VERSION ""

NS_ :

BS_:

BU_: XXX CAMERA FRONT_RADAR ADRV APRK

BO_ 53 ACCELERATOR: 32 XXX
 SG_ GEAR : 8|4@1+ (1,0) [0|15] "" XXX
 SG_ BYTE0 : 0|8@1+ (1,0) [0|255] "" XXX
 SG_ BYTE2 : 16|8@1+ (1,0) [0|255] "" XXX
 SG_ BYTE3 : 24|8@1+ (1,0) [0|255] "" XXX
 SG_ BYTE4 : 32|8@1+ (1,0) [0|255] "" XXX
 SG_ BYTE5 : 40|8@1+ (1,0) [0|255] "" XXX
 SG_ BYTE6 : 48|8@1+ (1,0) [0|255] "" XXX
 SG_ BYTE7 : 56|8@1+ (1,0) [0|255] "" XXX
 SG_ BYTE8 : 64|8@1+ (1,0) [0|255] "" XXX
 SG_ BYTE9 : 72|8@1+ (1,0) [0|255] "" XXX
 SG_ BYTE10 : 80|8@1+ (1,0) [0|255] "" XXX
 SG_ BYTE11 : 88|8@1+ (1,0) [0|255] "" XXX
 SG_ BYTE12 : 96|8@1+ (1,0) [0|255] "" XXX
 SG_ BYTE13 : 104|8@1+ (1,0) [0|255] "" XXX
 SG_ BYTE14 : 112|8@1+ (1,0) [0|255] "" XXX
 SG_ BYTE15 : 120|8@1+ (1,0) [0|255] "" XXX
 SG_ BYTE16 : 128|8@1+ (1,0) [0|255] "" XXX
 SG_ BYTE17 : 136|8@1+ (1,0) [0|255] "" XXX
 SG_ BYTE18 : 144|8@1+ (1,0) [0|255] "" XXX
 SG_ BYTE19 : 152|8@1+ (1,0) [0|255] "" XXX
 SG_ BYTE20 : 160|8@1+ (1,0) [0|255] "" XXX
 SG_ BYTE21 : 168|8@1+ (1,0) [0|255] "" XXX
 SG_ BYTE22 : 176|8@1+ (1,0) [0|255] "" XXX
 SG_ BYTE23 : 184|8@1+ (1,0) [0|255] "" XXX
 SG_ BYTE24 : 192|8@1+ (1,0) [0|255] "" XXX
 SG_ BYTE25 : 200|8@1+ (1,0) [0|255] "" XXX
 SG_ BYTE26 : 208|8@1+ (1,0) [0|255] "" XXX
 SG_ BYTE27 : 216|8@1+ (1,0) [0|255] "" XXX
 SG_ BYTE28 : 224|8@1+ (1,0) [0|255] "" XXX
 SG_ BYTE29 : 232|8@1+ (1,0) [0|255] "" XXX
 SG_ BYTE30 : 240|8@1+ (1,0) [0|255] "" XXX
 SG_ BYTE31 : 248|8@1+ (1,0) [0|255] "" XXX

BO_ 64 GEAR_ALT: 32 XXX
 SG_ GEAR : 8|4@1+ (1,0) [0|15] "" XXX
 SG_ BYTE0 : 0|8@1+ (1,0) [0|255] "" XXX
 SG_ BYTE2 : 16|8@1+ (1,0) [0|255] "" XXX
 SG_ BYTE3 : 24|8@1+ (1,0) [0|255] "" XXX
 SG_ BYTE4 : 32|8@1+ (1,0) [0|255] "" XXX
 SG_ BYTE5 : 40|8@1+ (1,0) [0|255] "" XXX
 SG_ BYTE6 : 48|8@1+ (1,0) [0|255] "" XXX
 SG_ BYTE7 : 56|8@1+ (1,0) [0|255] "" XXX
 SG_ BYTE8 : 64|8@1+ (1,0) [0|255] "" XXX
 SG_ BYTE9 : 72|8@1+ (1,0) [0|255] "" XXX
 SG_ BYTE10 : 80|8@1+ (1,0) [0|255] "" XXX
 SG_ BYTE11 : 88|8@1+ (1,0) [0|255] "" XXX
 SG_ BYTE12 : 96|8@1+ (1,0) [0|255] "" XXX
 SG_ BYTE13 : 104|8@1+ (1,0) [0|255] "" XXX
 SG_ BYTE14 : 112|8@1+ (1,0) [0|255] "" XXX
 SG_ BYTE15 : 120|8@1+ (1,0) [0|255] "" XXX
 SG_ BYTE16 : 128|8@1+ (1,0) [0|255] "" XXX
 SG_ BYTE17 : 136|8@1+ (1,0) [0|255] "" XXX
 SG_ BYTE18 : 144|8@1+ (1,0) [0|255] "" XXX
 SG_ BYTE19 : 152|8@1+ (1,0) [0|255] "" XXX
 SG_ BYTE20 : 160|8@1+ (1,0) [0|255] "" XXX
 SG_ BYTE21 : 168|8@1+ (1,0) [0|255] "" XXX
 SG_ BYTE22 : 176|8@1+ (1,0) [0|255] "" XXX
 SG_ BYTE23 : 184|8@1+ (1,0) [0|255] "" XXX
 SG_ BYTE24 : 192|8@1+ (1,0) [0|255] "" XXX
 SG_ BYTE25 : 200|8@1+ (1,0) [0|255] "" XXX
 SG_ BYTE26 : 208|8@1+ (1,0) [0|255] "" XXX
 SG_ BYTE27 : 216|8@1+ (1,0) [0|255] "" XXX
 SG_ BYTE28 : 224|8@1+ (1,0) [0|255] "" XXX
 SG_ BYTE29 : 232|8@1+ (1,0) [0|255] "" XXX
 SG_ BYTE30 : 240|8@1+ (1,0) [0|255] "" XXX
 SG_ BYTE31 : 248|8@1+ (1,0) [0|255] "" XXX

BO_ 69 GEAR: 24 XXX
 SG_ GEAR : 8|4@1+ (1,0) [0|15] "" XXX
 SG_ BYTE0 : 0|8@1+ (1,0) [0|255] "" XXX
 SG_ BYTE2 : 16|8@1+ (1,0) [0|255] "" XXX
 SG_ BYTE3 : 24|8@1+ (1,0) [0|255] "" XXX
 SG_ BYTE4 : 32|8@1+ (1,0) [0|255] "" XXX
 SG_ BYTE5 : 40|8@1+ (1,0) [0|255] "" XXX
 SG_ BYTE6 : 48|8@1+ (1,0) [0|255] "" XXX
 SG_ BYTE7 : 56|8@1+ (1,0) [0|255] "" XXX
 SG_ BYTE8 : 64|8@1+ (1,0) [0|255] "" XXX
 SG_ BYTE9 : 72|8@1+ (1,0) [0|255] "" XXX
 SG_ BYTE10 : 80|8@1+ (1,0) [0|255] "" XXX
 SG_ BYTE11 : 88|8@1+ (1,0) [0|255] "" XXX
 SG_ BYTE12 : 96|8@1+ (1,0) [0|255] "" XXX
 SG_ BYTE13 : 104|8@1+ (1,0) [0|255] "" XXX
 SG_ BYTE14 : 112|8@1+ (1,0) [0|255] "" XXX
 SG_ BYTE15 : 120|8@1+ (1,0) [0|255] "" XXX
 SG_ BYTE16 : 128|8@1+ (1,0) [0|255] "" XXX
 SG_ BYTE17 : 136|8@1+ (1,0) [0|255] "" XXX
 SG_ BYTE18 : 144|8@1+ (1,0) [0|255] "" XXX
 SG_ BYTE19 : 152|8@1+ (1,0) [0|255] "" XXX
 SG_ BYTE20 : 160|8@1+ (1,0) [0|255] "" XXX
 SG_ BYTE21 : 168|8@1+ (1,0) [0|255] "" XXX
 SG_ BYTE22 : 176|8@1+ (1,0) [0|255] "" XXX
 SG_ BYTE23 : 184|8@1+ (1,0) [0|255] "" XXX

BO_ 81 ADRV_0x51: 16 XXX
 SG_ BYTE0 : 0|8@1+ (1,0) [0|255] "" XXX
 SG_ BYTE1 : 8|8@1+ (1,0) [0|255] "" XXX
 SG_ BYTE2 : 16|8@1+ (1,0) [0|255] "" XXX
 SG_ BYTE3 : 24|8@1+ (1,0) [0|255] "" XXX
 SG_ BYTE4 : 32|8@1+ (1,0) [0|255] "" XXX
 SG_ BYTE5 : 40|8@1+ (1,0) [0|255] "" XXX
 SG_ BYTE6 : 48|8@1+ (1,0) [0|255] "" XXX
 SG_ BYTE7 : 56|8@1+ (1,0) [0|255] "" XXX
 SG_ BYTE8 : 64|8@1+ (1,0) [0|255] "" XXX
 SG_ BYTE9 : 72|8@1+ (1,0) [0|255] "" XXX
 SG_ BYTE10 : 80|8@1+ (1,0) [0|255] "" XXX
 SG_ BYTE11 : 88|8@1+ (1,0) [0|255] "" XXX
 SG_ BYTE12 : 96|8@1+ (1,0) [0|255] "" XXX
 SG_ BYTE13 : 104|8@1+ (1,0) [0|255] "" XXX
 SG_ BYTE14 : 112|8@1+ (1,0) [0|255] "" XXX
 SG_ BYTE15 : 120|8@1+ (1,0) [0|255] "" XXX

BO_ 96 ESP_STATUS: 32 XXX

BO_ 101 BRAKE: 32 XXX

BO_ 160 WHEEL_SPEEDS: 24 XXX
 SG_ BYTE0 : 0|8@1+ (1,0) [0|255] "" XXX
 SG_ BYTE1 : 8|8@1+ (1,0) [0|255] "" XXX
 SG_ BYTE2 : 16|8@1+ (1,0) [0|255] "" XXX
 SG_ BYTE3 : 24|8@1+ (1,0) [0|255] "" XXX
 SG_ BYTE4 : 32|8@1+ (1,0) [0|255] "" XXX
 SG_ BYTE5 : 40|8@1+ (1,0) [0|255] "" XXX
 SG_ BYTE6 : 48|8@1+ (1,0) [0|255] "" XXX
 SG_ BYTE7 : 56|8@1+ (1,0) [0|255] "" XXX
 SG_ BYTE8 : 64|8@1+ (1,0) [0|255] "" XXX
 SG_ BYTE9 : 72|8@1+ (1,0) [0|255] "" XXX
 SG_ BYTE10 : 80|8@1+ (1,0) [0|255] "" XXX
 SG_ BYTE11 : 88|8@1+ (1,0) [0|255] "" XXX
 SG_ BYTE12 : 96|8@1+ (1,0) [0|255] "" XXX
 SG_ BYTE13 : 104|8@1+ (1,0) [0|255] "" XXX
 SG_ BYTE14 : 112|8@1+ (1,0) [0|255] "" XXX
 SG_ BYTE15 : 120|8@1+ (1,0) [0|255] "" XXX
 SG_ BYTE16 : 128|8@1+ (1,0) [0|255] "" XXX
 SG_ BYTE17 : 136|8@1+ (1,0) [0|255] "" XXX
 SG_ BYTE18 : 144|8@1+ (1,0) [0|255] "" XXX
 SG_ BYTE19 : 152|8@1+ (1,0) [0|255] "" XXX
 SG_ BYTE20 : 160|8@1+ (1,0) [0|255] "" XXX
 SG_ BYTE21 : 168|8@1+ (1,0) [0|255] "" XXX
 SG_ BYTE22 : 176|8@1+ (1,0) [0|255] "" XXX
 SG_ BYTE23 : 184|8@1+ (1,0) [0|255] "" XXX

BO_ 234 MDPS: 32 XXX
 SG_ BYTE0 : 0|8@1+ (1,0) [0|255] "" XXX
 SG_ BYTE1 : 8|8@1+ (1,0) [0|255] "" XXX
 SG_ BYTE2 : 16|8@1+ (1,0) [0|255] "" XXX
 SG_ BYTE3 : 24|8@1+ (1,0) [0|255] "" XXX
 SG_ BYTE4 : 32|8@1+ (1,0) [0|255] "" XXX
 SG_ BYTE5 : 40|8@1+ (1,0) [0|255] "" XXX
 SG_ BYTE6 : 48|8@1+ (1,0) [0|255] "" XXX
 SG_ BYTE7 : 56|8@1+ (1,0) [0|255] "" XXX
 SG_ BYTE8 : 64|8@1+ (1,0) [0|255] "" XXX
 SG_ BYTE9 : 72|8@1+ (1,0) [0|255] "" XXX
 SG_ BYTE10 : 80|8@1+ (1,0) [0|255] "" XXX
 SG_ BYTE11 : 88|8@1+ (1,0) [0|255] "" XXX
 SG_ BYTE12 : 96|8@1+ (1,0) [0|255] "" XXX
 SG_ BYTE13 : 104|8@1+ (1,0) [0|255] "" XXX
 SG_ BYTE14 : 112|8@1+ (1,0) [0|255] "" XXX
 SG_ BYTE15 : 120|8@1+ (1,0) [0|255] "" XXX
 SG_ BYTE16 : 128|8@1+ (1,0) [0|255] "" XXX
 SG_ BYTE17 : 136|8@1+ (1,0) [0|255] "" XXX
 SG_ BYTE18 : 144|8@1+ (1,0) [0|255] "" XXX
 SG_ BYTE19 : 152|8@1+ (1,0) [0|255] "" XXX
 SG_ BYTE20 : 160|8@1+ (1,0) [0|255] "" XXX
 SG_ BYTE21 : 168|8@1+ (1,0) [0|255] "" XXX
 SG_ BYTE22 : 176|8@1+ (1,0) [0|255] "" XXX
 SG_ BYTE23 : 184|8@1+ (1,0) [0|255] "" XXX
 SG_ BYTE24 : 192|8@1+ (1,0) [0|255] "" XXX
 SG_ BYTE25 : 200|8@1+ (1,0) [0|255] "" XXX
 SG_ BYTE26 : 208|8@1+ (1,0) [0|255] "" XXX
 SG_ BYTE27 : 216|8@1+ (1,0) [0|255] "" XXX
 SG_ BYTE28 : 224|8@1+ (1,0) [0|255] "" XXX
 SG_ BYTE29 : 232|8@1+ (1,0) [0|255] "" XXX
 SG_ BYTE30 : 240|8@1+ (1,0) [0|255] "" XXX
 SG_ BYTE31 : 248|8@1+ (1,0) [0|255] "" XXX

BO_ 256 ACCELERATOR_BRAKE_ALT: 24 XXX
 SG_ BYTE0 : 0|8@1+ (1,0) [0|255] "" XXX
 SG_ BYTE1 : 8|8@1+ (1,0) [0|255] "" XXX
 SG_ BYTE2 : 16|8@1+ (1,0) [0|255] "" XXX
 SG_ BYTE3 : 24|8@1+ (1,0) [0|255] "" XXX
 SG_ BYTE4 : 32|8@1+ (1,0) [0|255] "" XXX
 SG_ BYTE5 : 40|8@1+ (1,0) [0|255] "" XXX
 SG_ BYTE6 : 48|8@1+ (1,0) [0|255] "" XXX
 SG_ BYTE7 : 56|8@1+ (1,0) [0|255] "" XXX
 SG_ BYTE8 : 64|8@1+ (1,0) [0|255] "" XXX
 SG_ BYTE9 : 72|8@1+ (1,0) [0|255] "" XXX
 SG_ BYTE10 : 80|8@1+ (1,0) [0|255] "" XXX
 SG_ BYTE11 : 88|8@1+ (1,0) [0|255] "" XXX
 SG_ BYTE12 : 96|8@1+ (1,0) [0|255] "" XXX
 SG_ BYTE13 : 104|8@1+ (1,0) [0|255] "" XXX
 SG_ BYTE14 : 112|8@1+ (1,0) [0|255] "" XXX
 SG_ BYTE15 : 120|8@1+ (1,0) [0|255] "" XXX
 SG_ BYTE16 : 128|8@1+ (1,0) [0|255] "" XXX
 SG_ BYTE17 : 136|8@1+ (1,0) [0|255] "" XXX
 SG_ BYTE18 : 144|8@1+ (1,0) [0|255] "" XXX
 SG_ BYTE19 : 152|8@1+ (1,0) [0|255] "" XXX
 SG_ BYTE20 : 160|8@1+ (1,0) [0|255] "" XXX
 SG_ BYTE21 : 168|8@1+ (1,0) [0|255] "" XXX
 SG_ BYTE22 : 176|8@1+ (1,0) [0|255] "" XXX
 SG_ BYTE23 : 184|8@1+ (1,0) [0|255] "" XXX

BO_ 272 LKAS_ALT: 32 XXX
 SG_ LKA_MODE : 24|4@1+ (1,0) [0|15] "" XXX
 SG_ LKA_ICON : 28|4@1+ (1,0) [0|15] "" XXX
 SG_ TORQUE_REQUEST : 32|11@1- (1,0) [-1024|1023] "" XXX
 SG_ LKA_ASSIST : 43|1@1+ (1,0) [0|1] "" XXX
 SG_ STEER_REQ : 44|1@1+ (1,0) [0|1] "" XXX
 SG_ STEER_MODE : 45|3@1+ (1,0) [0|7] "" XXX
 SG_ HAS_LANE_SAFETY : 48|1@1+ (1,0) [0|1] "" XXX
 SG_ LKA_AVAILABLE : 27|2@1+ (1,0) [0|3] "" XXX
 SG_ CHECKSUM : 0|16@1+ (1,0) [0|65535] "" XXX
 SG_ COUNTER : 16|8@1+ (1,0) [0|255] "" XXX
 SG_ BYTE7 : 56|8@1+ (1,0) [0|255] "" XXX
 SG_ BYTE8 : 64|8@1+ (1,0) [0|255] "" XXX
 SG_ BYTE9 : 72|8@1+ (1,0) [0|255] "" XXX
 SG_ BYTE10 : 80|8@1+ (1,0) [0|255] "" XXX
 SG_ BYTE11 : 88|8@1+ (1,0) [0|255] "" XXX
 SG_ BYTE12 : 96|8@1+ (1,0) [0|255] "" XXX
 SG_ BYTE13 : 104|8@1+ (1,0) [0|255] "" XXX
 SG_ BYTE14 : 112|8@1+ (1,0) [0|255] "" XXX
 SG_ BYTE15 : 120|8@1+ (1,0) [0|255] "" XXX
 SG_ BYTE16 : 128|8@1+ (1,0) [0|255] "" XXX
 SG_ BYTE17 : 136|8@1+ (1,0) [0|255] "" XXX
 SG_ BYTE18 : 144|8@1+ (1,0) [0|255] "" XXX
 SG_ BYTE19 : 152|8@1+ (1,0) [0|255] "" XXX
 SG_ BYTE20 : 160|8@1+ (1,0) [0|255] "" XXX
 SG_ BYTE21 : 168|8@1+ (1,0) [0|255] "" XXX
 SG_ BYTE22 : 176|8@1+ (1,0) [0|255] "" XXX
 SG_ BYTE23 : 184|8@1+ (1,0) [0|255] "" XXX
 SG_ BYTE24 : 192|8@1+ (1,0) [0|255] "" XXX
 SG_ BYTE25 : 200|8@1+ (1,0) [0|255] "" XXX
 SG_ BYTE26 : 208|8@1+ (1,0) [0|255] "" XXX
 SG_ BYTE27 : 216|8@1+ (1,0) [0|255] "" XXX
 SG_ BYTE28 : 224|8@1+ (1,0) [0|255] "" XXX
 SG_ BYTE29 : 232|8@1+ (1,0) [0|255] "" XXX
 SG_ BYTE30 : 240|8@1+ (1,0) [0|255] "" XXX
 SG_ BYTE31 : 248|8@1+ (1,0) [0|255] "" XXX

BO_ 282 FR_CMR_01_10ms: 16 XXX

BO_ 293 STEERING_SENSORS: 32 XXX
 SG_ BYTE0 : 0|8@1+ (1,0) [0|255] "" XXX
 SG_ BYTE1 : 8|8@1+ (1,0) [0|255] "" XXX
 SG_ BYTE2 : 16|8@1+ (1,0) [0|255] "" XXX
 SG_ BYTE3 : 24|8@1+ (1,0) [0|255] "" XXX
 SG_ BYTE4 : 32|8@1+ (1,0) [0|255] "" XXX
 SG_ BYTE5 : 40|8@1+ (1,0) [0|255] "" XXX
 SG_ BYTE6 : 48|8@1+ (1,0) [0|255] "" XXX
 SG_ BYTE7 : 56|8@1+ (1,0) [0|255] "" XXX
 SG_ BYTE8 : 64|8@1+ (1,0) [0|255] "" XXX
 SG_ BYTE9 : 72|8@1+ (1,0) [0|255] "" XXX
 SG_ BYTE10 : 80|8@1+ (1,0) [0|255] "" XXX
 SG_ BYTE11 : 88|8@1+ (1,0) [0|255] "" XXX
 SG_ BYTE12 : 96|8@1+ (1,0) [0|255] "" XXX
 SG_ BYTE13 : 104|8@1+ (1,0) [0|255] "" XXX
 SG_ BYTE14 : 112|8@1+ (1,0) [0|255] "" XXX
 SG_ BYTE15 : 120|8@1+ (1,0) [0|255] "" XXX
 SG_ BYTE16 : 128|8@1+ (1,0) [0|255] "" XXX
 SG_ BYTE17 : 136|8@1+ (1,0) [0|255] "" XXX
 SG_ BYTE18 : 144|8@1+ (1,0) [0|255] "" XXX
 SG_ BYTE19 : 152|8@1+ (1,0) [0|255] "" XXX
 SG_ BYTE20 : 160|8@1+ (1,0) [0|255] "" XXX
 SG_ BYTE21 : 168|8@1+ (1,0) [0|255] "" XXX
 SG_ BYTE22 : 176|8@1+ (1,0) [0|255] "" XXX
 SG_ BYTE23 : 184|8@1+ (1,0) [0|255] "" XXX
 SG_ BYTE24 : 192|8@1+ (1,0) [0|255] "" XXX
 SG_ BYTE25 : 200|8@1+ (1,0) [0|255] "" XXX
 SG_ BYTE26 : 208|8@1+ (1,0) [0|255] "" XXX
 SG_ BYTE27 : 216|8@1+ (1,0) [0|255] "" XXX
 SG_ BYTE28 : 224|8@1+ (1,0) [0|255] "" XXX
 SG_ BYTE29 : 232|8@1+ (1,0) [0|255] "" XXX
 SG_ BYTE30 : 240|8@1+ (1,0) [0|255] "" XXX
 SG_ BYTE31 : 248|8@1+ (1,0) [0|255] "" XXX

BO_ 298 LFA: 32 XXX
 SG_ LKA_MODE : 24|4@1+ (1,0) [0|15] "" XXX
 SG_ LKA_ICON : 28|4@1+ (1,0) [0|15] "" XXX
 SG_ TORQUE_REQUEST : 32|11@1- (1,0) [-1024|1023] "" XXX
 SG_ LKA_ASSIST : 43|1@1+ (1,0) [0|1] "" XXX
 SG_ STEER_REQ : 44|1@1+ (1,0) [0|1] "" XXX
 SG_ STEER_MODE : 45|3@1+ (1,0) [0|7] "" XXX
 SG_ HAS_LANE_SAFETY : 48|1@1+ (1,0) [0|1] "" XXX
 SG_ LKA_AVAILABLE : 27|2@1+ (1,0) [0|3] "" XXX
 SG_ CHECKSUM : 0|16@1+ (1,0) [0|65535] "" XXX
 SG_ COUNTER : 16|8@1+ (1,0) [0|255] "" XXX
 SG_ BYTE7 : 56|8@1+ (1,0) [0|255] "" XXX
 SG_ BYTE8 : 64|8@1+ (1,0) [0|255] "" XXX
 SG_ BYTE9 : 72|8@1+ (1,0) [0|255] "" XXX
 SG_ BYTE10 : 80|8@1+ (1,0) [0|255] "" XXX
 SG_ BYTE11 : 88|8@1+ (1,0) [0|255] "" XXX
 SG_ BYTE12 : 96|8@1+ (1,0) [0|255] "" XXX
 SG_ BYTE13 : 104|8@1+ (1,0) [0|255] "" XXX
 SG_ BYTE14 : 112|8@1+ (1,0) [0|255] "" XXX
 SG_ BYTE15 : 120|8@1+ (1,0) [0|255] "" XXX
 SG_ BYTE16 : 128|8@1+ (1,0) [0|255] "" XXX
 SG_ BYTE17 : 136|8@1+ (1,0) [0|255] "" XXX
 SG_ BYTE18 : 144|8@1+ (1,0) [0|255] "" XXX
 SG_ BYTE19 : 152|8@1+ (1,0) [0|255] "" XXX
 SG_ BYTE20 : 160|8@1+ (1,0) [0|255] "" XXX
 SG_ BYTE21 : 168|8@1+ (1,0) [0|255] "" XXX
 SG_ BYTE22 : 176|8@1+ (1,0) [0|255] "" XXX
 SG_ BYTE23 : 184|8@1+ (1,0) [0|255] "" XXX
 SG_ BYTE24 : 192|8@1+ (1,0) [0|255] "" XXX
 SG_ BYTE25 : 200|8@1+ (1,0) [0|255] "" XXX
 SG_ BYTE26 : 208|8@1+ (1,0) [0|255] "" XXX
 SG_ BYTE27 : 216|8@1+ (1,0) [0|255] "" XXX
 SG_ BYTE28 : 224|8@1+ (1,0) [0|255] "" XXX
 SG_ BYTE29 : 232|8@1+ (1,0) [0|255] "" XXX
 SG_ BYTE30 : 240|8@1+ (1,0) [0|255] "" XXX
 SG_ BYTE31 : 248|8@1+ (1,0) [0|255] "" XXX

BO_ 304 GEAR_SHIFTER: 32 XXX
 SG_ GEAR : 8|4@1+ (1,0) [0|15] "" XXX
 SG_ BYTE0 : 0|8@1+ (1,0) [0|255] "" XXX
 SG_ BYTE2 : 16|8@1+ (1,0) [0|255] "" XXX
 SG_ BYTE3 : 24|8@1+ (1,0) [0|255] "" XXX
 SG_ BYTE4 : 32|8@1+ (1,0) [0|255] "" XXX
 SG_ BYTE5 : 40|8@1+ (1,0) [0|255] "" XXX
 SG_ BYTE6 : 48|8@1+ (1,0) [0|255] "" XXX
 SG_ BYTE7 : 56|8@1+ (1,0) [0|255] "" XXX
 SG_ BYTE8 : 64|8@1+ (1,0) [0|255] "" XXX
 SG_ BYTE9 : 72|8@1+ (1,0) [0|255] "" XXX
 SG_ BYTE10 : 80|8@1+ (1,0) [0|255] "" XXX
 SG_ BYTE11 : 88|8@1+ (1,0) [0|255] "" XXX
 SG_ BYTE12 : 96|8@1+ (1,0) [0|255] "" XXX
 SG_ BYTE13 : 104|8@1+ (1,0) [0|255] "" XXX
 SG_ BYTE14 : 112|8@1+ (1,0) [0|255] "" XXX
 SG_ BYTE15 : 120|8@1+ (1,0) [0|255] "" XXX
 SG_ BYTE16 : 128|8@1+ (1,0) [0|255] "" XXX
 SG_ BYTE17 : 136|8@1+ (1,0) [0|255] "" XXX
 SG_ BYTE18 : 144|8@1+ (1,0) [0|255] "" XXX
 SG_ BYTE19 : 152|8@1+ (1,0) [0|255] "" XXX
 SG_ BYTE20 : 160|8@1+ (1,0) [0|255] "" XXX
 SG_ BYTE21 : 168|8@1+ (1,0) [0|255] "" XXX
 SG_ BYTE22 : 176|8@1+ (1,0) [0|255] "" XXX
 SG_ BYTE23 : 184|8@1+ (1,0) [0|255] "" XXX
 SG_ BYTE24 : 192|8@1+ (1,0) [0|255] "" XXX
 SG_ BYTE25 : 200|8@1+ (1,0) [0|255] "" XXX
 SG_ BYTE26 : 208|8@1+ (1,0) [0|255] "" XXX
 SG_ BYTE27 : 216|8@1+ (1,0) [0|255] "" XXX
 SG_ BYTE28 : 224|8@1+ (1,0) [0|255] "" XXX
 SG_ BYTE29 : 232|8@1+ (1,0) [0|255] "" XXX
 SG_ BYTE30 : 240|8@1+ (1,0) [0|255] "" XXX
 SG_ BYTE31 : 248|8@1+ (1,0) [0|255] "" XXX

BO_ 352 ADRV_0x160: 16 XXX
 SG_ BYTE0 : 0|8@1+ (1,0) [0|255] "" XXX
 SG_ BYTE1 : 8|8@1+ (1,0) [0|255] "" XXX
 SG_ BYTE2 : 16|8@1+ (1,0) [0|255] "" XXX
 SG_ BYTE3 : 24|8@1+ (1,0) [0|255] "" XXX
 SG_ BYTE4 : 32|8@1+ (1,0) [0|255] "" XXX
 SG_ BYTE5 : 40|8@1+ (1,0) [0|255] "" XXX
 SG_ BYTE6 : 48|8@1+ (1,0) [0|255] "" XXX
 SG_ BYTE7 : 56|8@1+ (1,0) [0|255] "" XXX
 SG_ BYTE8 : 64|8@1+ (1,0) [0|255] "" XXX
 SG_ BYTE9 : 72|8@1+ (1,0) [0|255] "" XXX
 SG_ BYTE10 : 80|8@1+ (1,0) [0|255] "" XXX
 SG_ BYTE11 : 88|8@1+ (1,0) [0|255] "" XXX
 SG_ BYTE12 : 96|8@1+ (1,0) [0|255] "" XXX
 SG_ BYTE13 : 104|8@1+ (1,0) [0|255] "" XXX
 SG_ BYTE14 : 112|8@1+ (1,0) [0|255] "" XXX
 SG_ BYTE15 : 120|8@1+ (1,0) [0|255] "" XXX

BO_ 357 ADRV_0x165: 16 XXX
 SG_ BYTE0 : 0|8@1+ (1,0) [0|255] "" XXX
 SG_ BYTE1 : 8|8@1+ (1,0) [0|255] "" XXX
 SG_ BYTE2 : 16|8@1+ (1,0) [0|255] "" XXX
 SG_ BYTE3 : 24|8@1+ (1,0) [0|255] "" XXX
 SG_ BYTE4 : 32|8@1+ (1,0) [0|255] "" XXX
 SG_ BYTE5 : 40|8@1+ (1,0) [0|255] "" XXX
 SG_ BYTE6 : 48|8@1+ (1,0) [0|255] "" XXX
 SG_ BYTE7 : 56|8@1+ (1,0) [0|255] "" XXX
 SG_ BYTE8 : 64|8@1+ (1,0) [0|255] "" XXX
 SG_ BYTE9 : 72|8@1+ (1,0) [0|255] "" XXX
 SG_ BYTE10 : 80|8@1+ (1,0) [0|255] "" XXX
 SG_ BYTE11 : 88|8@1+ (1,0) [0|255] "" XXX
 SG_ BYTE12 : 96|8@1+ (1,0) [0|255] "" XXX
 SG_ BYTE13 : 104|8@1+ (1,0) [0|255] "" XXX
 SG_ BYTE14 : 112|8@1+ (1,0) [0|255] "" XXX
 SG_ BYTE15 : 120|8@1+ (1,0) [0|255] "" XXX

BO_ 373 TCS: 16 XXX
 SG_ BYTE0 : 0|8@1+ (1,0) [0|255] "" XXX
 SG_ BYTE1 : 8|8@1+ (1,0) [0|255] "" XXX
 SG_ BYTE2 : 16|8@1+ (1,0) [0|255] "" XXX
 SG_ BYTE3 : 24|8@1+ (1,0) [0|255] "" XXX
 SG_ BYTE4 : 32|8@1+ (1,0) [0|255] "" XXX
 SG_ BYTE5 : 40|8@1+ (1,0) [0|255] "" XXX
 SG_ BYTE6 : 48|8@1+ (1,0) [0|255] "" XXX
 SG_ BYTE7 : 56|8@1+ (1,0) [0|255] "" XXX
 SG_ BYTE8 : 64|8@1+ (1,0) [0|255] "" XXX
 SG_ BYTE9 : 72|8@1+ (1,0) [0|255] "" XXX
 SG_ BYTE10 : 80|8@1+ (1,0) [0|255] "" XXX
 SG_ BYTE11 : 88|8@1+ (1,0) [0|255] "" XXX
 SG_ BYTE12 : 96|8@1+ (1,0) [0|255] "" XXX
 SG_ BYTE13 : 104|8@1+ (1,0) [0|255] "" XXX
 SG_ BYTE14 : 112|8@1+ (1,0) [0|255] "" XXX
 SG_ BYTE15 : 120|8@1+ (1,0) [0|255] "" XXX

BO_ 416 SCC_CONTROL: 32 XXX
 SG_ ACCMode : 68|3@1+ (1,0) [0|7] "" XXX
 SG_ CRUISE_STANDSTILL : 76|1@1+ (1,0) [0|1] "" XXX
 SG_ VSetDis : 103|8@0+ (1,0) [0|255] "" XXX
 SG_ aReqValue : 128|11@1+ (0.01,-10.23) [-10.23|10.24] "m/s^2" XXX
 SG_ aReqRaw : 140|11@1+ (0.01,-10.23) [-10.23|10.24] "m/s^2" XXX
 SG_ CHECKSUM : 0|16@1+ (1,0) [0|65535] "" XXX
 SG_ COUNTER : 16|8@1+ (1,0) [0|255] "" XXX
 SG_ BYTE3 : 24|8@1+ (1,0) [0|255] "" XXX
 SG_ BYTE4 : 32|8@1+ (1,0) [0|255] "" XXX
 SG_ BYTE5 : 40|8@1+ (1,0) [0|255] "" XXX
 SG_ BYTE6 : 48|8@1+ (1,0) [0|255] "" XXX
 SG_ BYTE7 : 56|8@1+ (1,0) [0|255] "" XXX
 SG_ BYTE10 : 80|8@1+ (1,0) [0|255] "" XXX
 SG_ BYTE11 : 88|8@1+ (1,0) [0|255] "" XXX
 SG_ BYTE13 : 104|8@1+ (1,0) [0|255] "" XXX
 SG_ BYTE14 : 112|8@1+ (1,0) [0|255] "" XXX
 SG_ BYTE15 : 120|8@1+ (1,0) [0|255] "" XXX
 SG_ BYTE21 : 168|8@1+ (1,0) [0|255] "" XXX
 SG_ BYTE22 : 176|8@1+ (1,0) [0|255] "" XXX
 SG_ BYTE23 : 184|8@1+ (1,0) [0|255] "" XXX
 SG_ BYTE24 : 192|8@1+ (1,0) [0|255] "" XXX
 SG_ BYTE25 : 200|8@1+ (1,0) [0|255] "" XXX
 SG_ BYTE26 : 208|8@1+ (1,0) [0|255] "" XXX
 SG_ BYTE27 : 216|8@1+ (1,0) [0|255] "" XXX
 SG_ BYTE28 : 224|8@1+ (1,0) [0|255] "" XXX
 SG_ BYTE29 : 232|8@1+ (1,0) [0|255] "" XXX
 SG_ BYTE30 : 240|8@1+ (1,0) [0|255] "" XXX
 SG_ BYTE31 : 248|8@1+ (1,0) [0|255] "" XXX

BO_ 426 CRUISE_BUTTONS_ALT: 16 XXX
 SG_ DISTANCE_UNIT : 30|1@1+ (1,0) [0|1] "" XXX
 SG_ CRUISE_BUTTONS : 36|3@1+ (1,0) [0|4] "" XXX
 SG_ LDA_BTN : 39|1@1+ (1,0) [0|1] "" XXX
 SG_ CHECKSUM : 0|16@1+ (1,0) [0|65535] "" XXX
 SG_ COUNTER : 16|8@1+ (1,0) [0|255] "" XXX
 SG_ BYTE6 : 48|8@1+ (1,0) [0|255] "" XXX
 SG_ BYTE7 : 56|8@1+ (1,0) [0|255] "" XXX
 SG_ BYTE8 : 64|8@1+ (1,0) [0|255] "" XXX
 SG_ BYTE9 : 72|8@1+ (1,0) [0|255] "" XXX
 SG_ BYTE10 : 80|8@1+ (1,0) [0|255] "" XXX
 SG_ BYTE11 : 88|8@1+ (1,0) [0|255] "" XXX
 SG_ BYTE12 : 96|8@1+ (1,0) [0|255] "" XXX
 SG_ BYTE13 : 104|8@1+ (1,0) [0|255] "" XXX
 SG_ BYTE14 : 112|8@1+ (1,0) [0|255] "" XXX
 SG_ BYTE15 : 120|8@1+ (1,0) [0|255] "" XXX

BO_ 437 CAMERA_0x1b5: 32 XXX
 SG_ BYTE0 : 0|8@1+ (1,0) [0|255] "" XXX
 SG_ BYTE1 : 8|8@1+ (1,0) [0|255] "" XXX
 SG_ BYTE2 : 16|8@1+ (1,0) [0|255] "" XXX
 SG_ BYTE3 : 24|8@1+ (1,0) [0|255] "" XXX
 SG_ BYTE4 : 32|8@1+ (1,0) [0|255] "" XXX
 SG_ BYTE5 : 40|8@1+ (1,0) [0|255] "" XXX
 SG_ BYTE6 : 48|8@1+ (1,0) [0|255] "" XXX
 SG_ BYTE7 : 56|8@1+ (1,0) [0|255] "" XXX
 SG_ BYTE8 : 64|8@1+ (1,0) [0|255] "" XXX
 SG_ BYTE9 : 72|8@1+ (1,0) [0|255] "" XXX
 SG_ BYTE10 : 80|8@1+ (1,0) [0|255] "" XXX
 SG_ BYTE11 : 88|8@1+ (1,0) [0|255] "" XXX
 SG_ BYTE12 : 96|8@1+ (1,0) [0|255] "" XXX
 SG_ BYTE13 : 104|8@1+ (1,0) [0|255] "" XXX
 SG_ BYTE14 : 112|8@1+ (1,0) [0|255] "" XXX
 SG_ BYTE15 : 120|8@1+ (1,0) [0|255] "" XXX
 SG_ BYTE16 : 128|8@1+ (1,0) [0|255] "" XXX
 SG_ BYTE17 : 136|8@1+ (1,0) [0|255] "" XXX
 SG_ BYTE18 : 144|8@1+ (1,0) [0|255] "" XXX
 SG_ BYTE19 : 152|8@1+ (1,0) [0|255] "" XXX
 SG_ BYTE20 : 160|8@1+ (1,0) [0|255] "" XXX
 SG_ BYTE21 : 168|8@1+ (1,0) [0|255] "" XXX
 SG_ BYTE22 : 176|8@1+ (1,0) [0|255] "" XXX
 SG_ BYTE23 : 184|8@1+ (1,0) [0|255] "" XXX
 SG_ BYTE24 : 192|8@1+ (1,0) [0|255] "" XXX
 SG_ BYTE25 : 200|8@1+ (1,0) [0|255] "" XXX
 SG_ BYTE26 : 208|8@1+ (1,0) [0|255] "" XXX
 SG_ BYTE27 : 216|8@1+ (1,0) [0|255] "" XXX
 SG_ BYTE28 : 224|8@1+ (1,0) [0|255] "" XXX
 SG_ BYTE29 : 232|8@1+ (1,0) [0|255] "" XXX
 SG_ BYTE30 : 240|8@1+ (1,0) [0|255] "" XXX
 SG_ BYTE31 : 248|8@1+ (1,0) [0|255] "" XXX

BO_ 442 BLINDSPOTS_REAR_CORNERS: 24 XXX
 SG_ BYTE0 : 0|8@1+ (1,0) [0|255] "" XXX
 SG_ BYTE1 : 8|8@1+ (1,0) [0|255] "" XXX
 SG_ BYTE2 : 16|8@1+ (1,0) [0|255] "" XXX
 SG_ BYTE3 : 24|8@1+ (1,0) [0|255] "" XXX
 SG_ BYTE4 : 32|8@1+ (1,0) [0|255] "" XXX
 SG_ BYTE5 : 40|8@1+ (1,0) [0|255] "" XXX
 SG_ BYTE6 : 48|8@1+ (1,0) [0|255] "" XXX
 SG_ BYTE7 : 56|8@1+ (1,0) [0|255] "" XXX
 SG_ BYTE8 : 64|8@1+ (1,0) [0|255] "" XXX
 SG_ BYTE9 : 72|8@1+ (1,0) [0|255] "" XXX
 SG_ BYTE10 : 80|8@1+ (1,0) [0|255] "" XXX
 SG_ BYTE11 : 88|8@1+ (1,0) [0|255] "" XXX
 SG_ BYTE12 : 96|8@1+ (1,0) [0|255] "" XXX
 SG_ BYTE13 : 104|8@1+ (1,0) [0|255] "" XXX
 SG_ BYTE14 : 112|8@1+ (1,0) [0|255] "" XXX
 SG_ BYTE15 : 120|8@1+ (1,0) [0|255] "" XXX
 SG_ BYTE16 : 128|8@1+ (1,0) [0|255] "" XXX
 SG_ BYTE17 : 136|8@1+ (1,0) [0|255] "" XXX
 SG_ BYTE18 : 144|8@1+ (1,0) [0|255] "" XXX
 SG_ BYTE19 : 152|8@1+ (1,0) [0|255] "" XXX
 SG_ BYTE20 : 160|8@1+ (1,0) [0|255] "" XXX
 SG_ BYTE21 : 168|8@1+ (1,0) [0|255] "" XXX
 SG_ BYTE22 : 176|8@1+ (1,0) [0|255] "" XXX
 SG_ BYTE23 : 184|8@1+ (1,0) [0|255] "" XXX

BO_ 474 ADRV_0x1da: 16 XXX
 SG_ BYTE0 : 0|8@1+ (1,0) [0|255] "" XXX
 SG_ BYTE1 : 8|8@1+ (1,0) [0|255] "" XXX
 SG_ BYTE2 : 16|8@1+ (1,0) [0|255] "" XXX
 SG_ BYTE3 : 24|8@1+ (1,0) [0|255] "" XXX
 SG_ BYTE4 : 32|8@1+ (1,0) [0|255] "" XXX
 SG_ BYTE5 : 40|8@1+ (1,0) [0|255] "" XXX
 SG_ BYTE6 : 48|8@1+ (1,0) [0|255] "" XXX
 SG_ BYTE7 : 56|8@1+ (1,0) [0|255] "" XXX
 SG_ BYTE8 : 64|8@1+ (1,0) [0|255] "" XXX
 SG_ BYTE9 : 72|8@1+ (1,0) [0|255] "" XXX
 SG_ BYTE10 : 80|8@1+ (1,0) [0|255] "" XXX
 SG_ BYTE11 : 88|8@1+ (1,0) [0|255] "" XXX
 SG_ BYTE12 : 96|8@1+ (1,0) [0|255] "" XXX
 SG_ BYTE13 : 104|8@1+ (1,0) [0|255] "" XXX
 SG_ BYTE14 : 112|8@1+ (1,0) [0|255] "" XXX
 SG_ BYTE15 : 120|8@1+ (1,0) [0|255] "" XXX

BO_ 480 LFAHDA_CLUSTER: 32 XXX
 SG_ HDA_ICON : 24|2@1+ (1,0) [0|3] "" XXX
 SG_ LFA_ICON : 28|2@1+ (1,0) [0|3] "" XXX
 SG_ CHECKSUM : 0|16@1+ (1,0) [0|65535] "" XXX
 SG_ COUNTER : 16|8@1+ (1,0) [0|255] "" XXX
 SG_ BYTE4 : 32|8@1+ (1,0) [0|255] "" XXX
 SG_ BYTE5 : 40|8@1+ (1,0) [0|255] "" XXX
 SG_ BYTE6 : 48|8@1+ (1,0) [0|255] "" XXX
 SG_ BYTE7 : 56|8@1+ (1,0) [0|255] "" XXX
 SG_ BYTE8 : 64|8@1+ (1,0) [0|255] "" XXX
 SG_ BYTE9 : 72|8@1+ (1,0) [0|255] "" XXX
 SG_ BYTE10 : 80|8@1+ (1,0) [0|255] "" XXX
 SG_ BYTE11 : 88|8@1+ (1,0) [0|255] "" XXX
 SG_ BYTE12 : 96|8@1+ (1,0) [0|255] "" XXX
 SG_ BYTE13 : 104|8@1+ (1,0) [0|255] "" XXX
 SG_ BYTE14 : 112|8@1+ (1,0) [0|255] "" XXX
 SG_ BYTE15 : 120|8@1+ (1,0) [0|255] "" XXX
 SG_ BYTE16 : 128|8@1+ (1,0) [0|255] "" XXX
 SG_ BYTE17 : 136|8@1+ (1,0) [0|255] "" XXX
 SG_ BYTE18 : 144|8@1+ (1,0) [0|255] "" XXX
 SG_ BYTE19 : 152|8@1+ (1,0) [0|255] "" XXX
 SG_ BYTE20 : 160|8@1+ (1,0) [0|255] "" XXX
 SG_ BYTE21 : 168|8@1+ (1,0) [0|255] "" XXX
 SG_ BYTE22 : 176|8@1+ (1,0) [0|255] "" XXX
 SG_ BYTE23 : 184|8@1+ (1,0) [0|255] "" XXX
 SG_ BYTE24 : 192|8@1+ (1,0) [0|255] "" XXX
 SG_ BYTE25 : 200|8@1+ (1,0) [0|255] "" XXX
 SG_ BYTE26 : 208|8@1+ (1,0) [0|255] "" XXX
 SG_ BYTE27 : 216|8@1+ (1,0) [0|255] "" XXX
 SG_ BYTE28 : 224|8@1+ (1,0) [0|255] "" XXX
 SG_ BYTE29 : 232|8@1+ (1,0) [0|255] "" XXX
 SG_ BYTE30 : 240|8@1+ (1,0) [0|255] "" XXX
 SG_ BYTE31 : 248|8@1+ (1,0) [0|255] "" XXX

BO_ 490 ADRV_0x1ea: 32 XXX
 SG_ BYTE0 : 0|8@1+ (1,0) [0|255] "" XXX
 SG_ BYTE1 : 8|8@1+ (1,0) [0|255] "" XXX
 SG_ BYTE2 : 16|8@1+ (1,0) [0|255] "" XXX
 SG_ BYTE3 : 24|8@1+ (1,0) [0|255] "" XXX
 SG_ BYTE4 : 32|8@1+ (1,0) [0|255] "" XXX
 SG_ BYTE5 : 40|8@1+ (1,0) [0|255] "" XXX
 SG_ BYTE6 : 48|8@1+ (1,0) [0|255] "" XXX
 SG_ BYTE7 : 56|8@1+ (1,0) [0|255] "" XXX
 SG_ BYTE8 : 64|8@1+ (1,0) [0|255] "" XXX
 SG_ BYTE9 : 72|8@1+ (1,0) [0|255] "" XXX
 SG_ BYTE10 : 80|8@1+ (1,0) [0|255] "" XXX
 SG_ BYTE11 : 88|8@1+ (1,0) [0|255] "" XXX
 SG_ BYTE12 : 96|8@1+ (1,0) [0|255] "" XXX
 SG_ BYTE13 : 104|8@1+ (1,0) [0|255] "" XXX
 SG_ BYTE14 : 112|8@1+ (1,0) [0|255] "" XXX
 SG_ BYTE15 : 120|8@1+ (1,0) [0|255] "" XXX
 SG_ BYTE16 : 128|8@1+ (1,0) [0|255] "" XXX
 SG_ BYTE17 : 136|8@1+ (1,0) [0|255] "" XXX
 SG_ BYTE18 : 144|8@1+ (1,0) [0|255] "" XXX
 SG_ BYTE19 : 152|8@1+ (1,0) [0|255] "" XXX
 SG_ BYTE20 : 160|8@1+ (1,0) [0|255] "" XXX
 SG_ BYTE21 : 168|8@1+ (1,0) [0|255] "" XXX
 SG_ BYTE22 : 176|8@1+ (1,0) [0|255] "" XXX
 SG_ BYTE23 : 184|8@1+ (1,0) [0|255] "" XXX
 SG_ BYTE24 : 192|8@1+ (1,0) [0|255] "" XXX
 SG_ BYTE25 : 200|8@1+ (1,0) [0|255] "" XXX
 SG_ BYTE26 : 208|8@1+ (1,0) [0|255] "" XXX
 SG_ BYTE27 : 216|8@1+ (1,0) [0|255] "" XXX
 SG_ BYTE28 : 224|8@1+ (1,0) [0|255] "" XXX
 SG_ BYTE29 : 232|8@1+ (1,0) [0|255] "" XXX
 SG_ BYTE30 : 240|8@1+ (1,0) [0|255] "" XXX
 SG_ BYTE31 : 248|8@1+ (1,0) [0|255] "" XXX

BO_ 506 ISLA: 32 XXX
 SG_ BYTE0 : 0|8@1+ (1,0) [0|255] "" XXX
 SG_ BYTE1 : 8|8@1+ (1,0) [0|255] "" XXX
 SG_ BYTE2 : 16|8@1+ (1,0) [0|255] "" XXX
 SG_ BYTE3 : 24|8@1+ (1,0) [0|255] "" XXX
 SG_ BYTE4 : 32|8@1+ (1,0) [0|255] "" XXX
 SG_ BYTE5 : 40|8@1+ (1,0) [0|255] "" XXX
 SG_ BYTE6 : 48|8@1+ (1,0) [0|255] "" XXX
 SG_ BYTE7 : 56|8@1+ (1,0) [0|255] "" XXX
 SG_ BYTE8 : 64|8@1+ (1,0) [0|255] "" XXX
 SG_ BYTE9 : 72|8@1+ (1,0) [0|255] "" XXX
 SG_ BYTE10 : 80|8@1+ (1,0) [0|255] "" XXX
 SG_ BYTE11 : 88|8@1+ (1,0) [0|255] "" XXX
 SG_ BYTE12 : 96|8@1+ (1,0) [0|255] "" XXX
 SG_ BYTE13 : 104|8@1+ (1,0) [0|255] "" XXX
 SG_ BYTE14 : 112|8@1+ (1,0) [0|255] "" XXX
 SG_ BYTE15 : 120|8@1+ (1,0) [0|255] "" XXX
 SG_ BYTE16 : 128|8@1+ (1,0) [0|255] "" XXX
 SG_ BYTE17 : 136|8@1+ (1,0) [0|255] "" XXX
 SG_ BYTE18 : 144|8@1+ (1,0) [0|255] "" XXX
 SG_ BYTE19 : 152|8@1+ (1,0) [0|255] "" XXX
 SG_ BYTE20 : 160|8@1+ (1,0) [0|255] "" XXX
 SG_ BYTE21 : 168|8@1+ (1,0) [0|255] "" XXX
 SG_ BYTE22 : 176|8@1+ (1,0) [0|255] "" XXX
 SG_ BYTE23 : 184|8@1+ (1,0) [0|255] "" XXX
 SG_ BYTE24 : 192|8@1+ (1,0) [0|255] "" XXX
 SG_ BYTE25 : 200|8@1+ (1,0) [0|255] "" XXX
 SG_ BYTE26 : 208|8@1+ (1,0) [0|255] "" XXX
 SG_ BYTE27 : 216|8@1+ (1,0) [0|255] "" XXX
 SG_ BYTE28 : 224|8@1+ (1,0) [0|255] "" XXX
 SG_ BYTE29 : 232|8@1+ (1,0) [0|255] "" XXX
 SG_ BYTE30 : 240|8@1+ (1,0) [0|255] "" XXX
 SG_ BYTE31 : 248|8@1+ (1,0) [0|255] "" XXX

BO_ 512 ADRV_0x200: 16 XXX
 SG_ BYTE0 : 0|8@1+ (1,0) [0|255] "" XXX
 SG_ BYTE1 : 8|8@1+ (1,0) [0|255] "" XXX
 SG_ BYTE2 : 16|8@1+ (1,0) [0|255] "" XXX
 SG_ BYTE3 : 24|8@1+ (1,0) [0|255] "" XXX
 SG_ BYTE4 : 32|8@1+ (1,0) [0|255] "" XXX
 SG_ BYTE5 : 40|8@1+ (1,0) [0|255] "" XXX
 SG_ BYTE6 : 48|8@1+ (1,0) [0|255] "" XXX
 SG_ BYTE7 : 56|8@1+ (1,0) [0|255] "" XXX
 SG_ BYTE8 : 64|8@1+ (1,0) [0|255] "" XXX
 SG_ BYTE9 : 72|8@1+ (1,0) [0|255] "" XXX
 SG_ BYTE10 : 80|8@1+ (1,0) [0|255] "" XXX
 SG_ BYTE11 : 88|8@1+ (1,0) [0|255] "" XXX
 SG_ BYTE12 : 96|8@1+ (1,0) [0|255] "" XXX
 SG_ BYTE13 : 104|8@1+ (1,0) [0|255] "" XXX
 SG_ BYTE14 : 112|8@1+ (1,0) [0|255] "" XXX
 SG_ BYTE15 : 120|8@1+ (1,0) [0|255] "" XXX

BO_ 560 HBA_0x230: 16 XXX
 SG_ BYTE0 : 0|8@1+ (1,0) [0|255] "" XXX
 SG_ BYTE1 : 8|8@1+ (1,0) [0|255] "" XXX
 SG_ BYTE2 : 16|8@1+ (1,0) [0|255] "" XXX
 SG_ BYTE3 : 24|8@1+ (1,0) [0|255] "" XXX
 SG_ BYTE4 : 32|8@1+ (1,0) [0|255] "" XXX
 SG_ BYTE5 : 40|8@1+ (1,0) [0|255] "" XXX
 SG_ BYTE6 : 48|8@1+ (1,0) [0|255] "" XXX
 SG_ BYTE7 : 56|8@1+ (1,0) [0|255] "" XXX
 SG_ BYTE8 : 64|8@1+ (1,0) [0|255] "" XXX
 SG_ BYTE9 : 72|8@1+ (1,0) [0|255] "" XXX
 SG_ BYTE10 : 80|8@1+ (1,0) [0|255] "" XXX
 SG_ BYTE11 : 88|8@1+ (1,0) [0|255] "" XXX
 SG_ BYTE12 : 96|8@1+ (1,0) [0|255] "" XXX
 SG_ BYTE13 : 104|8@1+ (1,0) [0|255] "" XXX
 SG_ BYTE14 : 112|8@1+ (1,0) [0|255] "" XXX
 SG_ BYTE15 : 120|8@1+ (1,0) [0|255] "" XXX

BO_ 561 HBA_0x231: 32 XXX
 SG_ BYTE0 : 0|8@1+ (1,0) [0|255] "" XXX
 SG_ BYTE1 : 8|8@1+ (1,0) [0|255] "" XXX
 SG_ BYTE2 : 16|8@1+ (1,0) [0|255] "" XXX
 SG_ BYTE3 : 24|8@1+ (1,0) [0|255] "" XXX
 SG_ BYTE4 : 32|8@1+ (1,0) [0|255] "" XXX
 SG_ BYTE5 : 40|8@1+ (1,0) [0|255] "" XXX
 SG_ BYTE6 : 48|8@1+ (1,0) [0|255] "" XXX
 SG_ BYTE7 : 56|8@1+ (1,0) [0|255] "" XXX
 SG_ BYTE8 : 64|8@1+ (1,0) [0|255] "" XXX
 SG_ BYTE9 : 72|8@1+ (1,0) [0|255] "" XXX
 SG_ BYTE10 : 80|8@1+ (1,0) [0|255] "" XXX
 SG_ BYTE11 : 88|8@1+ (1,0) [0|255] "" XXX
 SG_ BYTE12 : 96|8@1+ (1,0) [0|255] "" XXX
 SG_ BYTE13 : 104|8@1+ (1,0) [0|255] "" XXX
 SG_ BYTE14 : 112|8@1+ (1,0) [0|255] "" XXX
 SG_ BYTE15 : 120|8@1+ (1,0) [0|255] "" XXX
 SG_ BYTE16 : 128|8@1+ (1,0) [0|255] "" XXX
 SG_ BYTE17 : 136|8@1+ (1,0) [0|255] "" XXX
 SG_ BYTE18 : 144|8@1+ (1,0) [0|255] "" XXX
 SG_ BYTE19 : 152|8@1+ (1,0) [0|255] "" XXX
 SG_ BYTE20 : 160|8@1+ (1,0) [0|255] "" XXX
 SG_ BYTE21 : 168|8@1+ (1,0) [0|255] "" XXX
 SG_ BYTE22 : 176|8@1+ (1,0) [0|255] "" XXX
 SG_ BYTE23 : 184|8@1+ (1,0) [0|255] "" XXX
 SG_ BYTE24 : 192|8@1+ (1,0) [0|255] "" XXX
 SG_ BYTE25 : 200|8@1+ (1,0) [0|255] "" XXX
 SG_ BYTE26 : 208|8@1+ (1,0) [0|255] "" XXX
 SG_ BYTE27 : 216|8@1+ (1,0) [0|255] "" XXX
 SG_ BYTE28 : 224|8@1+ (1,0) [0|255] "" XXX
 SG_ BYTE29 : 232|8@1+ (1,0) [0|255] "" XXX
 SG_ BYTE30 : 240|8@1+ (1,0) [0|255] "" XXX
 SG_ BYTE31 : 248|8@1+ (1,0) [0|255] "" XXX

BO_ 562 HBA_0x232: 32 XXX
 SG_ BYTE0 : 0|8@1+ (1,0) [0|255] "" XXX
 SG_ BYTE1 : 8|8@1+ (1,0) [0|255] "" XXX
 SG_ BYTE2 : 16|8@1+ (1,0) [0|255] "" XXX
 SG_ BYTE3 : 24|8@1+ (1,0) [0|255] "" XXX
 SG_ BYTE4 : 32|8@1+ (1,0) [0|255] "" XXX
 SG_ BYTE5 : 40|8@1+ (1,0) [0|255] "" XXX
 SG_ BYTE6 : 48|8@1+ (1,0) [0|255] "" XXX
 SG_ BYTE7 : 56|8@1+ (1,0) [0|255] "" XXX
 SG_ BYTE8 : 64|8@1+ (1,0) [0|255] "" XXX
 SG_ BYTE9 : 72|8@1+ (1,0) [0|255] "" XXX
 SG_ BYTE10 : 80|8@1+ (1,0) [0|255] "" XXX
 SG_ BYTE11 : 88|8@1+ (1,0) [0|255] "" XXX
 SG_ BYTE12 : 96|8@1+ (1,0) [0|255] "" XXX
 SG_ BYTE13 : 104|8@1+ (1,0) [0|255] "" XXX
 SG_ BYTE14 : 112|8@1+ (1,0) [0|255] "" XXX
 SG_ BYTE15 : 120|8@1+ (1,0) [0|255] "" XXX
 SG_ BYTE16 : 128|8@1+ (1,0) [0|255] "" XXX
 SG_ BYTE17 : 136|8@1+ (1,0) [0|255] "" XXX
 SG_ BYTE18 : 144|8@1+ (1,0) [0|255] "" XXX
 SG_ BYTE19 : 152|8@1+ (1,0) [0|255] "" XXX
 SG_ BYTE20 : 160|8@1+ (1,0) [0|255] "" XXX
 SG_ BYTE21 : 168|8@1+ (1,0) [0|255] "" XXX
 SG_ BYTE22 : 176|8@1+ (1,0) [0|255] "" XXX
 SG_ BYTE23 : 184|8@1+ (1,0) [0|255] "" XXX
 SG_ BYTE24 : 192|8@1+ (1,0) [0|255] "" XXX
 SG_ BYTE25 : 200|8@1+ (1,0) [0|255] "" XXX
 SG_ BYTE26 : 208|8@1+ (1,0) [0|255] "" XXX
 SG_ BYTE27 : 216|8@1+ (1,0) [0|255] "" XXX
 SG_ BYTE28 : 224|8@1+ (1,0) [0|255] "" XXX
 SG_ BYTE29 : 232|8@1+ (1,0) [0|255] "" XXX
 SG_ BYTE30 : 240|8@1+ (1,0) [0|255] "" XXX
 SG_ BYTE31 : 248|8@1+ (1,0) [0|255] "" XXX

BO_ 563 HBA_0x233: 32 XXX
 SG_ BYTE0 : 0|8@1+ (1,0) [0|255] "" XXX
 SG_ BYTE1 : 8|8@1+ (1,0) [0|255] "" XXX
 SG_ BYTE2 : 16|8@1+ (1,0) [0|255] "" XXX
 SG_ BYTE3 : 24|8@1+ (1,0) [0|255] "" XXX
 SG_ BYTE4 : 32|8@1+ (1,0) [0|255] "" XXX
 SG_ BYTE5 : 40|8@1+ (1,0) [0|255] "" XXX
 SG_ BYTE6 : 48|8@1+ (1,0) [0|255] "" XXX
 SG_ BYTE7 : 56|8@1+ (1,0) [0|255] "" XXX
 SG_ BYTE8 : 64|8@1+ (1,0) [0|255] "" XXX
 SG_ BYTE9 : 72|8@1+ (1,0) [0|255] "" XXX
 SG_ BYTE10 : 80|8@1+ (1,0) [0|255] "" XXX
 SG_ BYTE11 : 88|8@1+ (1,0) [0|255] "" XXX
 SG_ BYTE12 : 96|8@1+ (1,0) [0|255] "" XXX
 SG_ BYTE13 : 104|8@1+ (1,0) [0|255] "" XXX
 SG_ BYTE14 : 112|8@1+ (1,0) [0|255] "" XXX
 SG_ BYTE15 : 120|8@1+ (1,0) [0|255] "" XXX
 SG_ BYTE16 : 128|8@1+ (1,0) [0|255] "" XXX
 SG_ BYTE17 : 136|8@1+ (1,0) [0|255] "" XXX
 SG_ BYTE18 : 144|8@1+ (1,0) [0|255] "" XXX
 SG_ BYTE19 : 152|8@1+ (1,0) [0|255] "" XXX
 SG_ BYTE20 : 160|8@1+ (1,0) [0|255] "" XXX
 SG_ BYTE21 : 168|8@1+ (1,0) [0|255] "" XXX
 SG_ BYTE22 : 176|8@1+ (1,0) [0|255] "" XXX
 SG_ BYTE23 : 184|8@1+ (1,0) [0|255] "" XXX
 SG_ BYTE24 : 192|8@1+ (1,0) [0|255] "" XXX
 SG_ BYTE25 : 200|8@1+ (1,0) [0|255] "" XXX
 SG_ BYTE26 : 208|8@1+ (1,0) [0|255] "" XXX
 SG_ BYTE27 : 216|8@1+ (1,0) [0|255] "" XXX
 SG_ BYTE28 : 224|8@1+ (1,0) [0|255] "" XXX
 SG_ BYTE29 : 232|8@1+ (1,0) [0|255] "" XXX
 SG_ BYTE30 : 240|8@1+ (1,0) [0|255] "" XXX
 SG_ BYTE31 : 248|8@1+ (1,0) [0|255] "" XXX

BO_ 564 HBA_0x234: 32 XXX
 SG_ BYTE0 : 0|8@1+ (1,0) [0|255] "" XXX
 SG_ BYTE1 : 8|8@1+ (1,0) [0|255] "" XXX
 SG_ BYTE2 : 16|8@1+ (1,0) [0|255] "" XXX
 SG_ BYTE3 : 24|8@1+ (1,0) [0|255] "" XXX
 SG_ BYTE4 : 32|8@1+ (1,0) [0|255] "" XXX
 SG_ BYTE5 : 40|8@1+ (1,0) [0|255] "" XXX
 SG_ BYTE6 : 48|8@1+ (1,0) [0|255] "" XXX
 SG_ BYTE7 : 56|8@1+ (1,0) [0|255] "" XXX
 SG_ BYTE8 : 64|8@1+ (1,0) [0|255] "" XXX
 SG_ BYTE9 : 72|8@1+ (1,0) [0|255] "" XXX
 SG_ BYTE10 : 80|8@1+ (1,0) [0|255] "" XXX
 SG_ BYTE11 : 88|8@1+ (1,0) [0|255] "" XXX
 SG_ BYTE12 : 96|8@1+ (1,0) [0|255] "" XXX
 SG_ BYTE13 : 104|8@1+ (1,0) [0|255] "" XXX
 SG_ BYTE14 : 112|8@1+ (1,0) [0|255] "" XXX
 SG_ BYTE15 : 120|8@1+ (1,0) [0|255] "" XXX
 SG_ BYTE16 : 128|8@1+ (1,0) [0|255] "" XXX
 SG_ BYTE17 : 136|8@1+ (1,0) [0|255] "" XXX
 SG_ BYTE18 : 144|8@1+ (1,0) [0|255] "" XXX
 SG_ BYTE19 : 152|8@1+ (1,0) [0|255] "" XXX
 SG_ BYTE20 : 160|8@1+ (1,0) [0|255] "" XXX
 SG_ BYTE21 : 168|8@1+ (1,0) [0|255] "" XXX
 SG_ BYTE22 : 176|8@1+ (1,0) [0|255] "" XXX
 SG_ BYTE23 : 184|8@1+ (1,0) [0|255] "" XXX
 SG_ BYTE24 : 192|8@1+ (1,0) [0|255] "" XXX
 SG_ BYTE25 : 200|8@1+ (1,0) [0|255] "" XXX
 SG_ BYTE26 : 208|8@1+ (1,0) [0|255] "" XXX
 SG_ BYTE27 : 216|8@1+ (1,0) [0|255] "" XXX
 SG_ BYTE28 : 224|8@1+ (1,0) [0|255] "" XXX
 SG_ BYTE29 : 232|8@1+ (1,0) [0|255] "" XXX
 SG_ BYTE30 : 240|8@1+ (1,0) [0|255] "" XXX
 SG_ BYTE31 : 248|8@1+ (1,0) [0|255] "" XXX

BO_ 565 HBA_0x235: 32 XXX
 SG_ BYTE0 : 0|8@1+ (1,0) [0|255] "" XXX
 SG_ BYTE1 : 8|8@1+ (1,0) [0|255] "" XXX
 SG_ BYTE2 : 16|8@1+ (1,0) [0|255] "" XXX
 SG_ BYTE3 : 24|8@1+ (1,0) [0|255] "" XXX
 SG_ BYTE4 : 32|8@1+ (1,0) [0|255] "" XXX
 SG_ BYTE5 : 40|8@1+ (1,0) [0|255] "" XXX
 SG_ BYTE6 : 48|8@1+ (1,0) [0|255] "" XXX
 SG_ BYTE7 : 56|8@1+ (1,0) [0|255] "" XXX
 SG_ BYTE8 : 64|8@1+ (1,0) [0|255] "" XXX
 SG_ BYTE9 : 72|8@1+ (1,0) [0|255] "" XXX
 SG_ BYTE10 : 80|8@1+ (1,0) [0|255] "" XXX
 SG_ BYTE11 : 88|8@1+ (1,0) [0|255] "" XXX
 SG_ BYTE12 : 96|8@1+ (1,0) [0|255] "" XXX
 SG_ BYTE13 : 104|8@1+ (1,0) [0|255] "" XXX
 SG_ BYTE14 : 112|8@1+ (1,0) [0|255] "" XXX
 SG_ BYTE15 : 120|8@1+ (1,0) [0|255] "" XXX
 SG_ BYTE16 : 128|8@1+ (1,0) [0|255] "" XXX
 SG_ BYTE17 : 136|8@1+ (1,0) [0|255] "" XXX
 SG_ BYTE18 : 144|8@1+ (1,0) [0|255] "" XXX
 SG_ BYTE19 : 152|8@1+ (1,0) [0|255] "" XXX
 SG_ BYTE20 : 160|8@1+ (1,0) [0|255] "" XXX
 SG_ BYTE21 : 168|8@1+ (1,0) [0|255] "" XXX
 SG_ BYTE22 : 176|8@1+ (1,0) [0|255] "" XXX
 SG_ BYTE23 : 184|8@1+ (1,0) [0|255] "" XXX
 SG_ BYTE24 : 192|8@1+ (1,0) [0|255] "" XXX
 SG_ BYTE25 : 200|8@1+ (1,0) [0|255] "" XXX
 SG_ BYTE26 : 208|8@1+ (1,0) [0|255] "" XXX
 SG_ BYTE27 : 216|8@1+ (1,0) [0|255] "" XXX
 SG_ BYTE28 : 224|8@1+ (1,0) [0|255] "" XXX
 SG_ BYTE29 : 232|8@1+ (1,0) [0|255] "" XXX
 SG_ BYTE30 : 240|8@1+ (1,0) [0|255] "" XXX
 SG_ BYTE31 : 248|8@1+ (1,0) [0|255] "" XXX

BO_ 566 HBA_0x236: 32 XXX
 SG_ BYTE0 : 0|8@1+ (1,0) [0|255] "" XXX
 SG_ BYTE1 : 8|8@1+ (1,0) [0|255] "" XXX
 SG_ BYTE2 : 16|8@1+ (1,0) [0|255] "" XXX
 SG_ BYTE3 : 24|8@1+ (1,0) [0|255] "" XXX
 SG_ BYTE4 : 32|8@1+ (1,0) [0|255] "" XXX
 SG_ BYTE5 : 40|8@1+ (1,0) [0|255] "" XXX
 SG_ BYTE6 : 48|8@1+ (1,0) [0|255] "" XXX
 SG_ BYTE7 : 56|8@1+ (1,0) [0|255] "" XXX
 SG_ BYTE8 : 64|8@1+ (1,0) [0|255] "" XXX
 SG_ BYTE9 : 72|8@1+ (1,0) [0|255] "" XXX
 SG_ BYTE10 : 80|8@1+ (1,0) [0|255] "" XXX
 SG_ BYTE11 : 88|8@1+ (1,0) [0|255] "" XXX
 SG_ BYTE12 : 96|8@1+ (1,0) [0|255] "" XXX
 SG_ BYTE13 : 104|8@1+ (1,0) [0|255] "" XXX
 SG_ BYTE14 : 112|8@1+ (1,0) [0|255] "" XXX
 SG_ BYTE15 : 120|8@1+ (1,0) [0|255] "" XXX
 SG_ BYTE16 : 128|8@1+ (1,0) [0|255] "" XXX
 SG_ BYTE17 : 136|8@1+ (1,0) [0|255] "" XXX
 SG_ BYTE18 : 144|8@1+ (1,0) [0|255] "" XXX
 SG_ BYTE19 : 152|8@1+ (1,0) [0|255] "" XXX
 SG_ BYTE20 : 160|8@1+ (1,0) [0|255] "" XXX
 SG_ BYTE21 : 168|8@1+ (1,0) [0|255] "" XXX
 SG_ BYTE22 : 176|8@1+ (1,0) [0|255] "" XXX
 SG_ BYTE23 : 184|8@1+ (1,0) [0|255] "" XXX
 SG_ BYTE24 : 192|8@1+ (1,0) [0|255] "" XXX
 SG_ BYTE25 : 200|8@1+ (1,0) [0|255] "" XXX
 SG_ BYTE26 : 208|8@1+ (1,0) [0|255] "" XXX
 SG_ BYTE27 : 216|8@1+ (1,0) [0|255] "" XXX
 SG_ BYTE28 : 224|8@1+ (1,0) [0|255] "" XXX
 SG_ BYTE29 : 232|8@1+ (1,0) [0|255] "" XXX
 SG_ BYTE30 : 240|8@1+ (1,0) [0|255] "" XXX
 SG_ BYTE31 : 248|8@1+ (1,0) [0|255] "" XXX

BO_ 567 HBA_0x237: 32 XXX
 SG_ BYTE0 : 0|8@1+ (1,0) [0|255] "" XXX
 SG_ BYTE1 : 8|8@1+ (1,0) [0|255] "" XXX
 SG_ BYTE2 : 16|8@1+ (1,0) [0|255] "" XXX
 SG_ BYTE3 : 24|8@1+ (1,0) [0|255] "" XXX
 SG_ BYTE4 : 32|8@1+ (1,0) [0|255] "" XXX
 SG_ BYTE5 : 40|8@1+ (1,0) [0|255] "" XXX
 SG_ BYTE6 : 48|8@1+ (1,0) [0|255] "" XXX
 SG_ BYTE7 : 56|8@1+ (1,0) [0|255] "" XXX
 SG_ BYTE8 : 64|8@1+ (1,0) [0|255] "" XXX
 SG_ BYTE9 : 72|8@1+ (1,0) [0|255] "" XXX
 SG_ BYTE10 : 80|8@1+ (1,0) [0|255] "" XXX
 SG_ BYTE11 : 88|8@1+ (1,0) [0|255] "" XXX
 SG_ BYTE12 : 96|8@1+ (1,0) [0|255] "" XXX
 SG_ BYTE13 : 104|8@1+ (1,0) [0|255] "" XXX
 SG_ BYTE14 : 112|8@1+ (1,0) [0|255] "" XXX
 SG_ BYTE15 : 120|8@1+ (1,0) [0|255] "" XXX
 SG_ BYTE16 : 128|8@1+ (1,0) [0|255] "" XXX
 SG_ BYTE17 : 136|8@1+ (1,0) [0|255] "" XXX
 SG_ BYTE18 : 144|8@1+ (1,0) [0|255] "" XXX
 SG_ BYTE19 : 152|8@1+ (1,0) [0|255] "" XXX
 SG_ BYTE20 : 160|8@1+ (1,0) [0|255] "" XXX
 SG_ BYTE21 : 168|8@1+ (1,0) [0|255] "" XXX
 SG_ BYTE22 : 176|8@1+ (1,0) [0|255] "" XXX
 SG_ BYTE23 : 184|8@1+ (1,0) [0|255] "" XXX
 SG_ BYTE24 : 192|8@1+ (1,0) [0|255] "" XXX
 SG_ BYTE25 : 200|8@1+ (1,0) [0|255] "" XXX
 SG_ BYTE26 : 208|8@1+ (1,0) [0|255] "" XXX
 SG_ BYTE27 : 216|8@1+ (1,0) [0|255] "" XXX
 SG_ BYTE28 : 224|8@1+ (1,0) [0|255] "" XXX
 SG_ BYTE29 : 232|8@1+ (1,0) [0|255] "" XXX
 SG_ BYTE30 : 240|8@1+ (1,0) [0|255] "" XXX
 SG_ BYTE31 : 248|8@1+ (1,0) [0|255] "" XXX

BO_ 568 HBA_0x238: 32 XXX
 SG_ BYTE0 : 0|8@1+ (1,0) [0|255] "" XXX
 SG_ BYTE1 : 8|8@1+ (1,0) [0|255] "" XXX
 SG_ BYTE2 : 16|8@1+ (1,0) [0|255] "" XXX
 SG_ BYTE3 : 24|8@1+ (1,0) [0|255] "" XXX
 SG_ BYTE4 : 32|8@1+ (1,0) [0|255] "" XXX
 SG_ BYTE5 : 40|8@1+ (1,0) [0|255] "" XXX
 SG_ BYTE6 : 48|8@1+ (1,0) [0|255] "" XXX
 SG_ BYTE7 : 56|8@1+ (1,0) [0|255] "" XXX
 SG_ BYTE8 : 64|8@1+ (1,0) [0|255] "" XXX
 SG_ BYTE9 : 72|8@1+ (1,0) [0|255] "" XXX
 SG_ BYTE10 : 80|8@1+ (1,0) [0|255] "" XXX
 SG_ BYTE11 : 88|8@1+ (1,0) [0|255] "" XXX
 SG_ BYTE12 : 96|8@1+ (1,0) [0|255] "" XXX
 SG_ BYTE13 : 104|8@1+ (1,0) [0|255] "" XXX
 SG_ BYTE14 : 112|8@1+ (1,0) [0|255] "" XXX
 SG_ BYTE15 : 120|8@1+ (1,0) [0|255] "" XXX
 SG_ BYTE16 : 128|8@1+ (1,0) [0|255] "" XXX
 SG_ BYTE17 : 136|8@1+ (1,0) [0|255] "" XXX
 SG_ BYTE18 : 144|8@1+ (1,0) [0|255] "" XXX
 SG_ BYTE19 : 152|8@1+ (1,0) [0|255] "" XXX
 SG_ BYTE20 : 160|8@1+ (1,0) [0|255] "" XXX
 SG_ BYTE21 : 168|8@1+ (1,0) [0|255] "" XXX
 SG_ BYTE22 : 176|8@1+ (1,0) [0|255] "" XXX
 SG_ BYTE23 : 184|8@1+ (1,0) [0|255] "" XXX
 SG_ BYTE24 : 192|8@1+ (1,0) [0|255] "" XXX
 SG_ BYTE25 : 200|8@1+ (1,0) [0|255] "" XXX
 SG_ BYTE26 : 208|8@1+ (1,0) [0|255] "" XXX
 SG_ BYTE27 : 216|8@1+ (1,0) [0|255] "" XXX
 SG_ BYTE28 : 224|8@1+ (1,0) [0|255] "" XXX
 SG_ BYTE29 : 232|8@1+ (1,0) [0|255] "" XXX
 SG_ BYTE30 : 240|8@1+ (1,0) [0|255] "" XXX
 SG_ BYTE31 : 248|8@1+ (1,0) [0|255] "" XXX

BO_ 569 HBA_0x239: 32 XXX
 SG_ BYTE0 : 0|8@1+ (1,0) [0|255] "" XXX
 SG_ BYTE1 : 8|8@1+ (1,0) [0|255] "" XXX
 SG_ BYTE2 : 16|8@1+ (1,0) [0|255] "" XXX
 SG_ BYTE3 : 24|8@1+ (1,0) [0|255] "" XXX
 SG_ BYTE4 : 32|8@1+ (1,0) [0|255] "" XXX
 SG_ BYTE5 : 40|8@1+ (1,0) [0|255] "" XXX
 SG_ BYTE6 : 48|8@1+ (1,0) [0|255] "" XXX
 SG_ BYTE7 : 56|8@1+ (1,0) [0|255] "" XXX
 SG_ BYTE8 : 64|8@1+ (1,0) [0|255] "" XXX
 SG_ BYTE9 : 72|8@1+ (1,0) [0|255] "" XXX
 SG_ BYTE10 : 80|8@1+ (1,0) [0|255] "" XXX
 SG_ BYTE11 : 88|8@1+ (1,0) [0|255] "" XXX
 SG_ BYTE12 : 96|8@1+ (1,0) [0|255] "" XXX
 SG_ BYTE13 : 104|8@1+ (1,0) [0|255] "" XXX
 SG_ BYTE14 : 112|8@1+ (1,0) [0|255] "" XXX
 SG_ BYTE15 : 120|8@1+ (1,0) [0|255] "" XXX
 SG_ BYTE16 : 128|8@1+ (1,0) [0|255] "" XXX
 SG_ BYTE17 : 136|8@1+ (1,0) [0|255] "" XXX
 SG_ BYTE18 : 144|8@1+ (1,0) [0|255] "" XXX
 SG_ BYTE19 : 152|8@1+ (1,0) [0|255] "" XXX
 SG_ BYTE20 : 160|8@1+ (1,0) [0|255] "" XXX
 SG_ BYTE21 : 168|8@1+ (1,0) [0|255] "" XXX
 SG_ BYTE22 : 176|8@1+ (1,0) [0|255] "" XXX
 SG_ BYTE23 : 184|8@1+ (1,0) [0|255] "" XXX
 SG_ BYTE24 : 192|8@1+ (1,0) [0|255] "" XXX
 SG_ BYTE25 : 200|8@1+ (1,0) [0|255] "" XXX
 SG_ BYTE26 : 208|8@1+ (1,0) [0|255] "" XXX
 SG_ BYTE27 : 216|8@1+ (1,0) [0|255] "" XXX
 SG_ BYTE28 : 224|8@1+ (1,0) [0|255] "" XXX
 SG_ BYTE29 : 232|8@1+ (1,0) [0|255] "" XXX
 SG_ BYTE30 : 240|8@1+ (1,0) [0|255] "" XXX
 SG_ BYTE31 : 248|8@1+ (1,0) [0|255] "" XXX

BO_ 570 HBA_0x23a: 32 XXX
 SG_ BYTE0 : 0|8@1+ (1,0) [0|255] "" XXX
 SG_ BYTE1 : 8|8@1+ (1,0) [0|255] "" XXX
 SG_ BYTE2 : 16|8@1+ (1,0) [0|255] "" XXX
 SG_ BYTE3 : 24|8@1+ (1,0) [0|255] "" XXX
 SG_ BYTE4 : 32|8@1+ (1,0) [0|255] "" XXX
 SG_ BYTE5 : 40|8@1+ (1,0) [0|255] "" XXX
 SG_ BYTE6 : 48|8@1+ (1,0) [0|255] "" XXX
 SG_ BYTE7 : 56|8@1+ (1,0) [0|255] "" XXX
 SG_ BYTE8 : 64|8@1+ (1,0) [0|255] "" XXX
 SG_ BYTE9 : 72|8@1+ (1,0) [0|255] "" XXX
 SG_ BYTE10 : 80|8@1+ (1,0) [0|255] "" XXX
 SG_ BYTE11 : 88|8@1+ (1,0) [0|255] "" XXX
 SG_ BYTE12 : 96|8@1+ (1,0) [0|255] "" XXX
 SG_ BYTE13 : 104|8@1+ (1,0) [0|255] "" XXX
 SG_ BYTE14 : 112|8@1+ (1,0) [0|255] "" XXX
 SG_ BYTE15 : 120|8@1+ (1,0) [0|255] "" XXX
 SG_ BYTE16 : 128|8@1+ (1,0) [0|255] "" XXX
 SG_ BYTE17 : 136|8@1+ (1,0) [0|255] "" XXX
 SG_ BYTE18 : 144|8@1+ (1,0) [0|255] "" XXX
 SG_ BYTE19 : 152|8@1+ (1,0) [0|255] "" XXX
 SG_ BYTE20 : 160|8@1+ (1,0) [0|255] "" XXX
 SG_ BYTE21 : 168|8@1+ (1,0) [0|255] "" XXX
 SG_ BYTE22 : 176|8@1+ (1,0) [0|255] "" XXX
 SG_ BYTE23 : 184|8@1+ (1,0) [0|255] "" XXX
 SG_ BYTE24 : 192|8@1+ (1,0) [0|255] "" XXX
 SG_ BYTE25 : 200|8@1+ (1,0) [0|255] "" XXX
 SG_ BYTE26 : 208|8@1+ (1,0) [0|255] "" XXX
 SG_ BYTE27 : 216|8@1+ (1,0) [0|255] "" XXX
 SG_ BYTE28 : 224|8@1+ (1,0) [0|255] "" XXX
 SG_ BYTE29 : 232|8@1+ (1,0) [0|255] "" XXX
 SG_ BYTE30 : 240|8@1+ (1,0) [0|255] "" XXX
 SG_ BYTE31 : 248|8@1+ (1,0) [0|255] "" XXX

BO_ 571 HBA_0x23b: 32 XXX
 SG_ BYTE0 : 0|8@1+ (1,0) [0|255] "" XXX
 SG_ BYTE1 : 8|8@1+ (1,0) [0|255] "" XXX
 SG_ BYTE2 : 16|8@1+ (1,0) [0|255] "" XXX
 SG_ BYTE3 : 24|8@1+ (1,0) [0|255] "" XXX
 SG_ BYTE4 : 32|8@1+ (1,0) [0|255] "" XXX
 SG_ BYTE5 : 40|8@1+ (1,0) [0|255] "" XXX
 SG_ BYTE6 : 48|8@1+ (1,0) [0|255] "" XXX
 SG_ BYTE7 : 56|8@1+ (1,0) [0|255] "" XXX
 SG_ BYTE8 : 64|8@1+ (1,0) [0|255] "" XXX
 SG_ BYTE9 : 72|8@1+ (1,0) [0|255] "" XXX
 SG_ BYTE10 : 80|8@1+ (1,0) [0|255] "" XXX
 SG_ BYTE11 : 88|8@1+ (1,0) [0|255] "" XXX
 SG_ BYTE12 : 96|8@1+ (1,0) [0|255] "" XXX
 SG_ BYTE13 : 104|8@1+ (1,0) [0|255] "" XXX
 SG_ BYTE14 : 112|8@1+ (1,0) [0|255] "" XXX
 SG_ BYTE15 : 120|8@1+ (1,0) [0|255] "" XXX
 SG_ BYTE16 : 128|8@1+ (1,0) [0|255] "" XXX
 SG_ BYTE17 : 136|8@1+ (1,0) [0|255] "" XXX
 SG_ BYTE18 : 144|8@1+ (1,0) [0|255] "" XXX
 SG_ BYTE19 : 152|8@1+ (1,0) [0|255] "" XXX
 SG_ BYTE20 : 160|8@1+ (1,0) [0|255] "" XXX
 SG_ BYTE21 : 168|8@1+ (1,0) [0|255] "" XXX
 SG_ BYTE22 : 176|8@1+ (1,0) [0|255] "" XXX
 SG_ BYTE23 : 184|8@1+ (1,0) [0|255] "" XXX
 SG_ BYTE24 : 192|8@1+ (1,0) [0|255] "" XXX
 SG_ BYTE25 : 200|8@1+ (1,0) [0|255] "" XXX
 SG_ BYTE26 : 208|8@1+ (1,0) [0|255] "" XXX
 SG_ BYTE27 : 216|8@1+ (1,0) [0|255] "" XXX
 SG_ BYTE28 : 224|8@1+ (1,0) [0|255] "" XXX
 SG_ BYTE29 : 232|8@1+ (1,0) [0|255] "" XXX
 SG_ BYTE30 : 240|8@1+ (1,0) [0|255] "" XXX
 SG_ BYTE31 : 248|8@1+ (1,0) [0|255] "" XXX

BO_ 572 HBA_0x23c: 32 XXX
 SG_ BYTE0 : 0|8@1+ (1,0) [0|255] "" XXX
 SG_ BYTE1 : 8|8@1+ (1,0) [0|255] "" XXX
 SG_ BYTE2 : 16|8@1+ (1,0) [0|255] "" XXX
 SG_ BYTE3 : 24|8@1+ (1,0) [0|255] "" XXX
 SG_ BYTE4 : 32|8@1+ (1,0) [0|255] "" XXX
 SG_ BYTE5 : 40|8@1+ (1,0) [0|255] "" XXX
 SG_ BYTE6 : 48|8@1+ (1,0) [0|255] "" XXX
 SG_ BYTE7 : 56|8@1+ (1,0) [0|255] "" XXX
 SG_ BYTE8 : 64|8@1+ (1,0) [0|255] "" XXX
 SG_ BYTE9 : 72|8@1+ (1,0) [0|255] "" XXX
 SG_ BYTE10 : 80|8@1+ (1,0) [0|255] "" XXX
 SG_ BYTE11 : 88|8@1+ (1,0) [0|255] "" XXX
 SG_ BYTE12 : 96|8@1+ (1,0) [0|255] "" XXX
 SG_ BYTE13 : 104|8@1+ (1,0) [0|255] "" XXX
 SG_ BYTE14 : 112|8@1+ (1,0) [0|255] "" XXX
 SG_ BYTE15 : 120|8@1+ (1,0) [0|255] "" XXX
 SG_ BYTE16 : 128|8@1+ (1,0) [0|255] "" XXX
 SG_ BYTE17 : 136|8@1+ (1,0) [0|255] "" XXX
 SG_ BYTE18 : 144|8@1+ (1,0) [0|255] "" XXX
 SG_ BYTE19 : 152|8@1+ (1,0) [0|255] "" XXX
 SG_ BYTE20 : 160|8@1+ (1,0) [0|255] "" XXX
 SG_ BYTE21 : 168|8@1+ (1,0) [0|255] "" XXX
 SG_ BYTE22 : 176|8@1+ (1,0) [0|255] "" XXX
 SG_ BYTE23 : 184|8@1+ (1,0) [0|255] "" XXX
 SG_ BYTE24 : 192|8@1+ (1,0) [0|255] "" XXX
 SG_ BYTE25 : 200|8@1+ (1,0) [0|255] "" XXX
 SG_ BYTE26 : 208|8@1+ (1,0) [0|255] "" XXX
 SG_ BYTE27 : 216|8@1+ (1,0) [0|255] "" XXX
 SG_ BYTE28 : 224|8@1+ (1,0) [0|255] "" XXX
 SG_ BYTE29 : 232|8@1+ (1,0) [0|255] "" XXX
 SG_ BYTE30 : 240|8@1+ (1,0) [0|255] "" XXX
 SG_ BYTE31 : 248|8@1+ (1,0) [0|255] "" XXX

BO_ 573 HBA_0x23d: 32 XXX
 SG_ BYTE0 : 0|8@1+ (1,0) [0|255] "" XXX
 SG_ BYTE1 : 8|8@1+ (1,0) [0|255] "" XXX
 SG_ BYTE2 : 16|8@1+ (1,0) [0|255] "" XXX
 SG_ BYTE3 : 24|8@1+ (1,0) [0|255] "" XXX
 SG_ BYTE4 : 32|8@1+ (1,0) [0|255] "" XXX
 SG_ BYTE5 : 40|8@1+ (1,0) [0|255] "" XXX
 SG_ BYTE6 : 48|8@1+ (1,0) [0|255] "" XXX
 SG_ BYTE7 : 56|8@1+ (1,0) [0|255] "" XXX
 SG_ BYTE8 : 64|8@1+ (1,0) [0|255] "" XXX
 SG_ BYTE9 : 72|8@1+ (1,0) [0|255] "" XXX
 SG_ BYTE10 : 80|8@1+ (1,0) [0|255] "" XXX
 SG_ BYTE11 : 88|8@1+ (1,0) [0|255] "" XXX
 SG_ BYTE12 : 96|8@1+ (1,0) [0|255] "" XXX
 SG_ BYTE13 : 104|8@1+ (1,0) [0|255] "" XXX
 SG_ BYTE14 : 112|8@1+ (1,0) [0|255] "" XXX
 SG_ BYTE15 : 120|8@1+ (1,0) [0|255] "" XXX
 SG_ BYTE16 : 128|8@1+ (1,0) [0|255] "" XXX
 SG_ BYTE17 : 136|8@1+ (1,0) [0|255] "" XXX
 SG_ BYTE18 : 144|8@1+ (1,0) [0|255] "" XXX
 SG_ BYTE19 : 152|8@1+ (1,0) [0|255] "" XXX
 SG_ BYTE20 : 160|8@1+ (1,0) [0|255] "" XXX
 SG_ BYTE21 : 168|8@1+ (1,0) [0|255] "" XXX
 SG_ BYTE22 : 176|8@1+ (1,0) [0|255] "" XXX
 SG_ BYTE23 : 184|8@1+ (1,0) [0|255] "" XXX
 SG_ BYTE24 : 192|8@1+ (1,0) [0|255] "" XXX
 SG_ BYTE25 : 200|8@1+ (1,0) [0|255] "" XXX
 SG_ BYTE26 : 208|8@1+ (1,0) [0|255] "" XXX
 SG_ BYTE27 : 216|8@1+ (1,0) [0|255] "" XXX
 SG_ BYTE28 : 224|8@1+ (1,0) [0|255] "" XXX
 SG_ BYTE29 : 232|8@1+ (1,0) [0|255] "" XXX
 SG_ BYTE30 : 240|8@1+ (1,0) [0|255] "" XXX
 SG_ BYTE31 : 248|8@1+ (1,0) [0|255] "" XXX

BO_ 574 HBA_0x23e: 32 XXX
 SG_ BYTE0 : 0|8@1+ (1,0) [0|255] "" XXX
 SG_ BYTE1 : 8|8@1+ (1,0) [0|255] "" XXX
 SG_ BYTE2 : 16|8@1+ (1,0) [0|255] "" XXX
 SG_ BYTE3 : 24|8@1+ (1,0) [0|255] "" XXX
 SG_ BYTE4 : 32|8@1+ (1,0) [0|255] "" XXX
 SG_ BYTE5 : 40|8@1+ (1,0) [0|255] "" XXX
 SG_ BYTE6 : 48|8@1+ (1,0) [0|255] "" XXX
 SG_ BYTE7 : 56|8@1+ (1,0) [0|255] "" XXX
 SG_ BYTE8 : 64|8@1+ (1,0) [0|255] "" XXX
 SG_ BYTE9 : 72|8@1+ (1,0) [0|255] "" XXX
 SG_ BYTE10 : 80|8@1+ (1,0) [0|255] "" XXX
 SG_ BYTE11 : 88|8@1+ (1,0) [0|255] "" XXX
 SG_ BYTE12 : 96|8@1+ (1,0) [0|255] "" XXX
 SG_ BYTE13 : 104|8@1+ (1,0) [0|255] "" XXX
 SG_ BYTE14 : 112|8@1+ (1,0) [0|255] "" XXX
 SG_ BYTE15 : 120|8@1+ (1,0) [0|255] "" XXX
 SG_ BYTE16 : 128|8@1+ (1,0) [0|255] "" XXX
 SG_ BYTE17 : 136|8@1+ (1,0) [0|255] "" XXX
 SG_ BYTE18 : 144|8@1+ (1,0) [0|255] "" XXX
 SG_ BYTE19 : 152|8@1+ (1,0) [0|255] "" XXX
 SG_ BYTE20 : 160|8@1+ (1,0) [0|255] "" XXX
 SG_ BYTE21 : 168|8@1+ (1,0) [0|255] "" XXX
 SG_ BYTE22 : 176|8@1+ (1,0) [0|255] "" XXX
 SG_ BYTE23 : 184|8@1+ (1,0) [0|255] "" XXX
 SG_ BYTE24 : 192|8@1+ (1,0) [0|255] "" XXX
 SG_ BYTE25 : 200|8@1+ (1,0) [0|255] "" XXX
 SG_ BYTE26 : 208|8@1+ (1,0) [0|255] "" XXX
 SG_ BYTE27 : 216|8@1+ (1,0) [0|255] "" XXX
 SG_ BYTE28 : 224|8@1+ (1,0) [0|255] "" XXX
 SG_ BYTE29 : 232|8@1+ (1,0) [0|255] "" XXX
 SG_ BYTE30 : 240|8@1+ (1,0) [0|255] "" XXX
 SG_ BYTE31 : 248|8@1+ (1,0) [0|255] "" XXX

BO_ 575 HBA_0x23f: 32 XXX
 SG_ BYTE0 : 0|8@1+ (1,0) [0|255] "" XXX
 SG_ BYTE1 : 8|8@1+ (1,0) [0|255] "" XXX
 SG_ BYTE2 : 16|8@1+ (1,0) [0|255] "" XXX
 SG_ BYTE3 : 24|8@1+ (1,0) [0|255] "" XXX
 SG_ BYTE4 : 32|8@1+ (1,0) [0|255] "" XXX
 SG_ BYTE5 : 40|8@1+ (1,0) [0|255] "" XXX
 SG_ BYTE6 : 48|8@1+ (1,0) [0|255] "" XXX
 SG_ BYTE7 : 56|8@1+ (1,0) [0|255] "" XXX
 SG_ BYTE8 : 64|8@1+ (1,0) [0|255] "" XXX
 SG_ BYTE9 : 72|8@1+ (1,0) [0|255] "" XXX
 SG_ BYTE10 : 80|8@1+ (1,0) [0|255] "" XXX
 SG_ BYTE11 : 88|8@1+ (1,0) [0|255] "" XXX
 SG_ BYTE12 : 96|8@1+ (1,0) [0|255] "" XXX
 SG_ BYTE13 : 104|8@1+ (1,0) [0|255] "" XXX
 SG_ BYTE14 : 112|8@1+ (1,0) [0|255] "" XXX
 SG_ BYTE15 : 120|8@1+ (1,0) [0|255] "" XXX
 SG_ BYTE16 : 128|8@1+ (1,0) [0|255] "" XXX
 SG_ BYTE17 : 136|8@1+ (1,0) [0|255] "" XXX
 SG_ BYTE18 : 144|8@1+ (1,0) [0|255] "" XXX
 SG_ BYTE19 : 152|8@1+ (1,0) [0|255] "" XXX
 SG_ BYTE20 : 160|8@1+ (1,0) [0|255] "" XXX
 SG_ BYTE21 : 168|8@1+ (1,0) [0|255] "" XXX
 SG_ BYTE22 : 176|8@1+ (1,0) [0|255] "" XXX
 SG_ BYTE23 : 184|8@1+ (1,0) [0|255] "" XXX
 SG_ BYTE24 : 192|8@1+ (1,0) [0|255] "" XXX
 SG_ BYTE25 : 200|8@1+ (1,0) [0|255] "" XXX
 SG_ BYTE26 : 208|8@1+ (1,0) [0|255] "" XXX
 SG_ BYTE27 : 216|8@1+ (1,0) [0|255] "" XXX
 SG_ BYTE28 : 224|8@1+ (1,0) [0|255] "" XXX
 SG_ BYTE29 : 232|8@1+ (1,0) [0|255] "" XXX
 SG_ BYTE30 : 240|8@1+ (1,0) [0|255] "" XXX
 SG_ BYTE31 : 248|8@1+ (1,0) [0|255] "" XXX

BO_ 576 RADAR_0x240: 32 XXX
 SG_ BYTE0 : 0|8@1+ (1,0) [0|255] "" XXX
 SG_ BYTE1 : 8|8@1+ (1,0) [0|255] "" XXX
 SG_ BYTE2 : 16|8@1+ (1,0) [0|255] "" XXX
 SG_ BYTE3 : 24|8@1+ (1,0) [0|255] "" XXX
 SG_ BYTE4 : 32|8@1+ (1,0) [0|255] "" XXX
 SG_ BYTE5 : 40|8@1+ (1,0) [0|255] "" XXX
 SG_ BYTE6 : 48|8@1+ (1,0) [0|255] "" XXX
 SG_ BYTE7 : 56|8@1+ (1,0) [0|255] "" XXX
 SG_ BYTE8 : 64|8@1+ (1,0) [0|255] "" XXX
 SG_ BYTE9 : 72|8@1+ (1,0) [0|255] "" XXX
 SG_ BYTE10 : 80|8@1+ (1,0) [0|255] "" XXX
 SG_ BYTE11 : 88|8@1+ (1,0) [0|255] "" XXX
 SG_ BYTE12 : 96|8@1+ (1,0) [0|255] "" XXX
 SG_ BYTE13 : 104|8@1+ (1,0) [0|255] "" XXX
 SG_ BYTE14 : 112|8@1+ (1,0) [0|255] "" XXX
 SG_ BYTE15 : 120|8@1+ (1,0) [0|255] "" XXX
 SG_ BYTE16 : 128|8@1+ (1,0) [0|255] "" XXX
 SG_ BYTE17 : 136|8@1+ (1,0) [0|255] "" XXX
 SG_ BYTE18 : 144|8@1+ (1,0) [0|255] "" XXX
 SG_ BYTE19 : 152|8@1+ (1,0) [0|255] "" XXX
 SG_ BYTE20 : 160|8@1+ (1,0) [0|255] "" XXX
 SG_ BYTE21 : 168|8@1+ (1,0) [0|255] "" XXX
 SG_ BYTE22 : 176|8@1+ (1,0) [0|255] "" XXX
 SG_ BYTE23 : 184|8@1+ (1,0) [0|255] "" XXX
 SG_ BYTE24 : 192|8@1+ (1,0) [0|255] "" XXX
 SG_ BYTE25 : 200|8@1+ (1,0) [0|255] "" XXX
 SG_ BYTE26 : 208|8@1+ (1,0) [0|255] "" XXX
 SG_ BYTE27 : 216|8@1+ (1,0) [0|255] "" XXX
 SG_ BYTE28 : 224|8@1+ (1,0) [0|255] "" XXX
 SG_ BYTE29 : 232|8@1+ (1,0) [0|255] "" XXX
 SG_ BYTE30 : 240|8@1+ (1,0) [0|255] "" XXX
 SG_ BYTE31 : 248|8@1+ (1,0) [0|255] "" XXX

BO_ 577 HBA_0x241: 32 XXX
 SG_ BYTE0 : 0|8@1+ (1,0) [0|255] "" XXX
 SG_ BYTE1 : 8|8@1+ (1,0) [0|255] "" XXX
 SG_ BYTE2 : 16|8@1+ (1,0) [0|255] "" XXX
 SG_ BYTE3 : 24|8@1+ (1,0) [0|255] "" XXX
 SG_ BYTE4 : 32|8@1+ (1,0) [0|255] "" XXX
 SG_ BYTE5 : 40|8@1+ (1,0) [0|255] "" XXX
 SG_ BYTE6 : 48|8@1+ (1,0) [0|255] "" XXX
 SG_ BYTE7 : 56|8@1+ (1,0) [0|255] "" XXX
 SG_ BYTE8 : 64|8@1+ (1,0) [0|255] "" XXX
 SG_ BYTE9 : 72|8@1+ (1,0) [0|255] "" XXX
 SG_ BYTE10 : 80|8@1+ (1,0) [0|255] "" XXX
 SG_ BYTE11 : 88|8@1+ (1,0) [0|255] "" XXX
 SG_ BYTE12 : 96|8@1+ (1,0) [0|255] "" XXX
 SG_ BYTE13 : 104|8@1+ (1,0) [0|255] "" XXX
 SG_ BYTE14 : 112|8@1+ (1,0) [0|255] "" XXX
 SG_ BYTE15 : 120|8@1+ (1,0) [0|255] "" XXX
 SG_ BYTE16 : 128|8@1+ (1,0) [0|255] "" XXX
 SG_ BYTE17 : 136|8@1+ (1,0) [0|255] "" XXX
 SG_ BYTE18 : 144|8@1+ (1,0) [0|255] "" XXX
 SG_ BYTE19 : 152|8@1+ (1,0) [0|255] "" XXX
 SG_ BYTE20 : 160|8@1+ (1,0) [0|255] "" XXX
 SG_ BYTE21 : 168|8@1+ (1,0) [0|255] "" XXX
 SG_ BYTE22 : 176|8@1+ (1,0) [0|255] "" XXX
 SG_ BYTE23 : 184|8@1+ (1,0) [0|255] "" XXX
 SG_ BYTE24 : 192|8@1+ (1,0) [0|255] "" XXX
 SG_ BYTE25 : 200|8@1+ (1,0) [0|255] "" XXX
 SG_ BYTE26 : 208|8@1+ (1,0) [0|255] "" XXX
 SG_ BYTE27 : 216|8@1+ (1,0) [0|255] "" XXX
 SG_ BYTE28 : 224|8@1+ (1,0) [0|255] "" XXX
 SG_ BYTE29 : 232|8@1+ (1,0) [0|255] "" XXX
 SG_ BYTE30 : 240|8@1+ (1,0) [0|255] "" XXX
 SG_ BYTE31 : 248|8@1+ (1,0) [0|255] "" XXX

BO_ 578 HBA_0x242: 32 XXX
 SG_ BYTE0 : 0|8@1+ (1,0) [0|255] "" XXX
 SG_ BYTE1 : 8|8@1+ (1,0) [0|255] "" XXX
 SG_ BYTE2 : 16|8@1+ (1,0) [0|255] "" XXX
 SG_ BYTE3 : 24|8@1+ (1,0) [0|255] "" XXX
 SG_ BYTE4 : 32|8@1+ (1,0) [0|255] "" XXX
 SG_ BYTE5 : 40|8@1+ (1,0) [0|255] "" XXX
 SG_ BYTE6 : 48|8@1+ (1,0) [0|255] "" XXX
 SG_ BYTE7 : 56|8@1+ (1,0) [0|255] "" XXX
 SG_ BYTE8 : 64|8@1+ (1,0) [0|255] "" XXX
 SG_ BYTE9 : 72|8@1+ (1,0) [0|255] "" XXX
 SG_ BYTE10 : 80|8@1+ (1,0) [0|255] "" XXX
 SG_ BYTE11 : 88|8@1+ (1,0) [0|255] "" XXX
 SG_ BYTE12 : 96|8@1+ (1,0) [0|255] "" XXX
 SG_ BYTE13 : 104|8@1+ (1,0) [0|255] "" XXX
 SG_ BYTE14 : 112|8@1+ (1,0) [0|255] "" XXX
 SG_ BYTE15 : 120|8@1+ (1,0) [0|255] "" XXX
 SG_ BYTE16 : 128|8@1+ (1,0) [0|255] "" XXX
 SG_ BYTE17 : 136|8@1+ (1,0) [0|255] "" XXX
 SG_ BYTE18 : 144|8@1+ (1,0) [0|255] "" XXX
 SG_ BYTE19 : 152|8@1+ (1,0) [0|255] "" XXX
 SG_ BYTE20 : 160|8@1+ (1,0) [0|255] "" XXX
 SG_ BYTE21 : 168|8@1+ (1,0) [0|255] "" XXX
 SG_ BYTE22 : 176|8@1+ (1,0) [0|255] "" XXX
 SG_ BYTE23 : 184|8@1+ (1,0) [0|255] "" XXX
 SG_ BYTE24 : 192|8@1+ (1,0) [0|255] "" XXX
 SG_ BYTE25 : 200|8@1+ (1,0) [0|255] "" XXX
 SG_ BYTE26 : 208|8@1+ (1,0) [0|255] "" XXX
 SG_ BYTE27 : 216|8@1+ (1,0) [0|255] "" XXX
 SG_ BYTE28 : 224|8@1+ (1,0) [0|255] "" XXX
 SG_ BYTE29 : 232|8@1+ (1,0) [0|255] "" XXX
 SG_ BYTE30 : 240|8@1+ (1,0) [0|255] "" XXX
 SG_ BYTE31 : 248|8@1+ (1,0) [0|255] "" XXX

BO_ 579 HBA_0x243: 32 XXX
 SG_ BYTE0 : 0|8@1+ (1,0) [0|255] "" XXX
 SG_ BYTE1 : 8|8@1+ (1,0) [0|255] "" XXX
 SG_ BYTE2 : 16|8@1+ (1,0) [0|255] "" XXX
 SG_ BYTE3 : 24|8@1+ (1,0) [0|255] "" XXX
 SG_ BYTE4 : 32|8@1+ (1,0) [0|255] "" XXX
 SG_ BYTE5 : 40|8@1+ (1,0) [0|255] "" XXX
 SG_ BYTE6 : 48|8@1+ (1,0) [0|255] "" XXX
 SG_ BYTE7 : 56|8@1+ (1,0) [0|255] "" XXX
 SG_ BYTE8 : 64|8@1+ (1,0) [0|255] "" XXX
 SG_ BYTE9 : 72|8@1+ (1,0) [0|255] "" XXX
 SG_ BYTE10 : 80|8@1+ (1,0) [0|255] "" XXX
 SG_ BYTE11 : 88|8@1+ (1,0) [0|255] "" XXX
 SG_ BYTE12 : 96|8@1+ (1,0) [0|255] "" XXX
 SG_ BYTE13 : 104|8@1+ (1,0) [0|255] "" XXX
 SG_ BYTE14 : 112|8@1+ (1,0) [0|255] "" XXX
 SG_ BYTE15 : 120|8@1+ (1,0) [0|255] "" XXX
 SG_ BYTE16 : 128|8@1+ (1,0) [0|255] "" XXX
 SG_ BYTE17 : 136|8@1+ (1,0) [0|255] "" XXX
 SG_ BYTE18 : 144|8@1+ (1,0) [0|255] "" XXX
 SG_ BYTE19 : 152|8@1+ (1,0) [0|255] "" XXX
 SG_ BYTE20 : 160|8@1+ (1,0) [0|255] "" XXX
 SG_ BYTE21 : 168|8@1+ (1,0) [0|255] "" XXX
 SG_ BYTE22 : 176|8@1+ (1,0) [0|255] "" XXX
 SG_ BYTE23 : 184|8@1+ (1,0) [0|255] "" XXX
 SG_ BYTE24 : 192|8@1+ (1,0) [0|255] "" XXX
 SG_ BYTE25 : 200|8@1+ (1,0) [0|255] "" XXX
 SG_ BYTE26 : 208|8@1+ (1,0) [0|255] "" XXX
 SG_ BYTE27 : 216|8@1+ (1,0) [0|255] "" XXX
 SG_ BYTE28 : 224|8@1+ (1,0) [0|255] "" XXX
 SG_ BYTE29 : 232|8@1+ (1,0) [0|255] "" XXX
 SG_ BYTE30 : 240|8@1+ (1,0) [0|255] "" XXX
 SG_ BYTE31 : 248|8@1+ (1,0) [0|255] "" XXX

BO_ 580 HBA_0x244: 32 XXX
 SG_ BYTE0 : 0|8@1+ (1,0) [0|255] "" XXX
 SG_ BYTE1 : 8|8@1+ (1,0) [0|255] "" XXX
 SG_ BYTE2 : 16|8@1+ (1,0) [0|255] "" XXX
 SG_ BYTE3 : 24|8@1+ (1,0) [0|255] "" XXX
 SG_ BYTE4 : 32|8@1+ (1,0) [0|255] "" XXX
 SG_ BYTE5 : 40|8@1+ (1,0) [0|255] "" XXX
 SG_ BYTE6 : 48|8@1+ (1,0) [0|255] "" XXX
 SG_ BYTE7 : 56|8@1+ (1,0) [0|255] "" XXX
 SG_ BYTE8 : 64|8@1+ (1,0) [0|255] "" XXX
 SG_ BYTE9 : 72|8@1+ (1,0) [0|255] "" XXX
 SG_ BYTE10 : 80|8@1+ (1,0) [0|255] "" XXX
 SG_ BYTE11 : 88|8@1+ (1,0) [0|255] "" XXX
 SG_ BYTE12 : 96|8@1+ (1,0) [0|255] "" XXX
 SG_ BYTE13 : 104|8@1+ (1,0) [0|255] "" XXX
 SG_ BYTE14 : 112|8@1+ (1,0) [0|255] "" XXX
 SG_ BYTE15 : 120|8@1+ (1,0) [0|255] "" XXX
 SG_ BYTE16 : 128|8@1+ (1,0) [0|255] "" XXX
 SG_ BYTE17 : 136|8@1+ (1,0) [0|255] "" XXX
 SG_ BYTE18 : 144|8@1+ (1,0) [0|255] "" XXX
 SG_ BYTE19 : 152|8@1+ (1,0) [0|255] "" XXX
 SG_ BYTE20 : 160|8@1+ (1,0) [0|255] "" XXX
 SG_ BYTE21 : 168|8@1+ (1,0) [0|255] "" XXX
 SG_ BYTE22 : 176|8@1+ (1,0) [0|255] "" XXX
 SG_ BYTE23 : 184|8@1+ (1,0) [0|255] "" XXX
 SG_ BYTE24 : 192|8@1+ (1,0) [0|255] "" XXX
 SG_ BYTE25 : 200|8@1+ (1,0) [0|255] "" XXX
 SG_ BYTE26 : 208|8@1+ (1,0) [0|255] "" XXX
 SG_ BYTE27 : 216|8@1+ (1,0) [0|255] "" XXX
 SG_ BYTE28 : 224|8@1+ (1,0) [0|255] "" XXX
 SG_ BYTE29 : 232|8@1+ (1,0) [0|255] "" XXX
 SG_ BYTE30 : 240|8@1+ (1,0) [0|255] "" XXX
 SG_ BYTE31 : 248|8@1+ (1,0) [0|255] "" XXX

BO_ 581 HBA_0x245: 32 XXX
 SG_ BYTE0 : 0|8@1+ (1,0) [0|255] "" XXX
 SG_ BYTE1 : 8|8@1+ (1,0) [0|255] "" XXX
 SG_ BYTE2 : 16|8@1+ (1,0) [0|255] "" XXX
 SG_ BYTE3 : 24|8@1+ (1,0) [0|255] "" XXX
 SG_ BYTE4 : 32|8@1+ (1,0) [0|255] "" XXX
 SG_ BYTE5 : 40|8@1+ (1,0) [0|255] "" XXX
 SG_ BYTE6 : 48|8@1+ (1,0) [0|255] "" XXX
 SG_ BYTE7 : 56|8@1+ (1,0) [0|255] "" XXX
 SG_ BYTE8 : 64|8@1+ (1,0) [0|255] "" XXX
 SG_ BYTE9 : 72|8@1+ (1,0) [0|255] "" XXX
 SG_ BYTE10 : 80|8@1+ (1,0) [0|255] "" XXX
 SG_ BYTE11 : 88|8@1+ (1,0) [0|255] "" XXX
 SG_ BYTE12 : 96|8@1+ (1,0) [0|255] "" XXX
 SG_ BYTE13 : 104|8@1+ (1,0) [0|255] "" XXX
 SG_ BYTE14 : 112|8@1+ (1,0) [0|255] "" XXX
 SG_ BYTE15 : 120|8@1+ (1,0) [0|255] "" XXX
 SG_ BYTE16 : 128|8@1+ (1,0) [0|255] "" XXX
 SG_ BYTE17 : 136|8@1+ (1,0) [0|255] "" XXX
 SG_ BYTE18 : 144|8@1+ (1,0) [0|255] "" XXX
 SG_ BYTE19 : 152|8@1+ (1,0) [0|255] "" XXX
 SG_ BYTE20 : 160|8@1+ (1,0) [0|255] "" XXX
 SG_ BYTE21 : 168|8@1+ (1,0) [0|255] "" XXX
 SG_ BYTE22 : 176|8@1+ (1,0) [0|255] "" XXX
 SG_ BYTE23 : 184|8@1+ (1,0) [0|255] "" XXX
 SG_ BYTE24 : 192|8@1+ (1,0) [0|255] "" XXX
 SG_ BYTE25 : 200|8@1+ (1,0) [0|255] "" XXX
 SG_ BYTE26 : 208|8@1+ (1,0) [0|255] "" XXX
 SG_ BYTE27 : 216|8@1+ (1,0) [0|255] "" XXX
 SG_ BYTE28 : 224|8@1+ (1,0) [0|255] "" XXX
 SG_ BYTE29 : 232|8@1+ (1,0) [0|255] "" XXX
 SG_ BYTE30 : 240|8@1+ (1,0) [0|255] "" XXX
 SG_ BYTE31 : 248|8@1+ (1,0) [0|255] "" XXX

BO_ 582 HBA_0x246: 32 XXX
 SG_ BYTE0 : 0|8@1+ (1,0) [0|255] "" XXX
 SG_ BYTE1 : 8|8@1+ (1,0) [0|255] "" XXX
 SG_ BYTE2 : 16|8@1+ (1,0) [0|255] "" XXX
 SG_ BYTE3 : 24|8@1+ (1,0) [0|255] "" XXX
 SG_ BYTE4 : 32|8@1+ (1,0) [0|255] "" XXX
 SG_ BYTE5 : 40|8@1+ (1,0) [0|255] "" XXX
 SG_ BYTE6 : 48|8@1+ (1,0) [0|255] "" XXX
 SG_ BYTE7 : 56|8@1+ (1,0) [0|255] "" XXX
 SG_ BYTE8 : 64|8@1+ (1,0) [0|255] "" XXX
 SG_ BYTE9 : 72|8@1+ (1,0) [0|255] "" XXX
 SG_ BYTE10 : 80|8@1+ (1,0) [0|255] "" XXX
 SG_ BYTE11 : 88|8@1+ (1,0) [0|255] "" XXX
 SG_ BYTE12 : 96|8@1+ (1,0) [0|255] "" XXX
 SG_ BYTE13 : 104|8@1+ (1,0) [0|255] "" XXX
 SG_ BYTE14 : 112|8@1+ (1,0) [0|255] "" XXX
 SG_ BYTE15 : 120|8@1+ (1,0) [0|255] "" XXX
 SG_ BYTE16 : 128|8@1+ (1,0) [0|255] "" XXX
 SG_ BYTE17 : 136|8@1+ (1,0) [0|255] "" XXX
 SG_ BYTE18 : 144|8@1+ (1,0) [0|255] "" XXX
 SG_ BYTE19 : 152|8@1+ (1,0) [0|255] "" XXX
 SG_ BYTE20 : 160|8@1+ (1,0) [0|255] "" XXX
 SG_ BYTE21 : 168|8@1+ (1,0) [0|255] "" XXX
 SG_ BYTE22 : 176|8@1+ (1,0) [0|255] "" XXX
 SG_ BYTE23 : 184|8@1+ (1,0) [0|255] "" XXX
 SG_ BYTE24 : 192|8@1+ (1,0) [0|255] "" XXX
 SG_ BYTE25 : 200|8@1+ (1,0) [0|255] "" XXX
 SG_ BYTE26 : 208|8@1+ (1,0) [0|255] "" XXX
 SG_ BYTE27 : 216|8@1+ (1,0) [0|255] "" XXX
 SG_ BYTE28 : 224|8@1+ (1,0) [0|255] "" XXX
 SG_ BYTE29 : 232|8@1+ (1,0) [0|255] "" XXX
 SG_ BYTE30 : 240|8@1+ (1,0) [0|255] "" XXX
 SG_ BYTE31 : 248|8@1+ (1,0) [0|255] "" XXX

BO_ 583 HBA_0x247: 32 XXX
 SG_ BYTE0 : 0|8@1+ (1,0) [0|255] "" XXX
 SG_ BYTE1 : 8|8@1+ (1,0) [0|255] "" XXX
 SG_ BYTE2 : 16|8@1+ (1,0) [0|255] "" XXX
 SG_ BYTE3 : 24|8@1+ (1,0) [0|255] "" XXX
 SG_ BYTE4 : 32|8@1+ (1,0) [0|255] "" XXX
 SG_ BYTE5 : 40|8@1+ (1,0) [0|255] "" XXX
 SG_ BYTE6 : 48|8@1+ (1,0) [0|255] "" XXX
 SG_ BYTE7 : 56|8@1+ (1,0) [0|255] "" XXX
 SG_ BYTE8 : 64|8@1+ (1,0) [0|255] "" XXX
 SG_ BYTE9 : 72|8@1+ (1,0) [0|255] "" XXX
 SG_ BYTE10 : 80|8@1+ (1,0) [0|255] "" XXX
 SG_ BYTE11 : 88|8@1+ (1,0) [0|255] "" XXX
 SG_ BYTE12 : 96|8@1+ (1,0) [0|255] "" XXX
 SG_ BYTE13 : 104|8@1+ (1,0) [0|255] "" XXX
 SG_ BYTE14 : 112|8@1+ (1,0) [0|255] "" XXX
 SG_ BYTE15 : 120|8@1+ (1,0) [0|255] "" XXX
 SG_ BYTE16 : 128|8@1+ (1,0) [0|255] "" XXX
 SG_ BYTE17 : 136|8@1+ (1,0) [0|255] "" XXX
 SG_ BYTE18 : 144|8@1+ (1,0) [0|255] "" XXX
 SG_ BYTE19 : 152|8@1+ (1,0) [0|255] "" XXX
 SG_ BYTE20 : 160|8@1+ (1,0) [0|255] "" XXX
 SG_ BYTE21 : 168|8@1+ (1,0) [0|255] "" XXX
 SG_ BYTE22 : 176|8@1+ (1,0) [0|255] "" XXX
 SG_ BYTE23 : 184|8@1+ (1,0) [0|255] "" XXX
 SG_ BYTE24 : 192|8@1+ (1,0) [0|255] "" XXX
 SG_ BYTE25 : 200|8@1+ (1,0) [0|255] "" XXX
 SG_ BYTE26 : 208|8@1+ (1,0) [0|255] "" XXX
 SG_ BYTE27 : 216|8@1+ (1,0) [0|255] "" XXX
 SG_ BYTE28 : 224|8@1+ (1,0) [0|255] "" XXX
 SG_ BYTE29 : 232|8@1+ (1,0) [0|255] "" XXX
 SG_ BYTE30 : 240|8@1+ (1,0) [0|255] "" XXX
 SG_ BYTE31 : 248|8@1+ (1,0) [0|255] "" XXX

BO_ 584 HBA_0x248: 32 XXX
 SG_ BYTE0 : 0|8@1+ (1,0) [0|255] "" XXX
 SG_ BYTE1 : 8|8@1+ (1,0) [0|255] "" XXX
 SG_ BYTE2 : 16|8@1+ (1,0) [0|255] "" XXX
 SG_ BYTE3 : 24|8@1+ (1,0) [0|255] "" XXX
 SG_ BYTE4 : 32|8@1+ (1,0) [0|255] "" XXX
 SG_ BYTE5 : 40|8@1+ (1,0) [0|255] "" XXX
 SG_ BYTE6 : 48|8@1+ (1,0) [0|255] "" XXX
 SG_ BYTE7 : 56|8@1+ (1,0) [0|255] "" XXX
 SG_ BYTE8 : 64|8@1+ (1,0) [0|255] "" XXX
 SG_ BYTE9 : 72|8@1+ (1,0) [0|255] "" XXX
 SG_ BYTE10 : 80|8@1+ (1,0) [0|255] "" XXX
 SG_ BYTE11 : 88|8@1+ (1,0) [0|255] "" XXX
 SG_ BYTE12 : 96|8@1+ (1,0) [0|255] "" XXX
 SG_ BYTE13 : 104|8@1+ (1,0) [0|255] "" XXX
 SG_ BYTE14 : 112|8@1+ (1,0) [0|255] "" XXX
 SG_ BYTE15 : 120|8@1+ (1,0) [0|255] "" XXX
 SG_ BYTE16 : 128|8@1+ (1,0) [0|255] "" XXX
 SG_ BYTE17 : 136|8@1+ (1,0) [0|255] "" XXX
 SG_ BYTE18 : 144|8@1+ (1,0) [0|255] "" XXX
 SG_ BYTE19 : 152|8@1+ (1,0) [0|255] "" XXX
 SG_ BYTE20 : 160|8@1+ (1,0) [0|255] "" XXX
 SG_ BYTE21 : 168|8@1+ (1,0) [0|255] "" XXX
 SG_ BYTE22 : 176|8@1+ (1,0) [0|255] "" XXX
 SG_ BYTE23 : 184|8@1+ (1,0) [0|255] "" XXX
 SG_ BYTE24 : 192|8@1+ (1,0) [0|255] "" XXX
 SG_ BYTE25 : 200|8@1+ (1,0) [0|255] "" XXX
 SG_ BYTE26 : 208|8@1+ (1,0) [0|255] "" XXX
 SG_ BYTE27 : 216|8@1+ (1,0) [0|255] "" XXX
 SG_ BYTE28 : 224|8@1+ (1,0) [0|255] "" XXX
 SG_ BYTE29 : 232|8@1+ (1,0) [0|255] "" XXX
 SG_ BYTE30 : 240|8@1+ (1,0) [0|255] "" XXX
 SG_ BYTE31 : 248|8@1+ (1,0) [0|255] "" XXX

BO_ 676 CAM_0x2a4: 24 XXX

BO_ 698 IFS_0x2ba: 32 XXX
 SG_ BYTE0 : 0|8@1+ (1,0) [0|255] "" XXX
 SG_ BYTE1 : 8|8@1+ (1,0) [0|255] "" XXX
 SG_ BYTE2 : 16|8@1+ (1,0) [0|255] "" XXX
 SG_ BYTE3 : 24|8@1+ (1,0) [0|255] "" XXX
 SG_ BYTE4 : 32|8@1+ (1,0) [0|255] "" XXX
 SG_ BYTE5 : 40|8@1+ (1,0) [0|255] "" XXX
 SG_ BYTE6 : 48|8@1+ (1,0) [0|255] "" XXX
 SG_ BYTE7 : 56|8@1+ (1,0) [0|255] "" XXX
 SG_ BYTE8 : 64|8@1+ (1,0) [0|255] "" XXX
 SG_ BYTE9 : 72|8@1+ (1,0) [0|255] "" XXX
 SG_ BYTE10 : 80|8@1+ (1,0) [0|255] "" XXX
 SG_ BYTE11 : 88|8@1+ (1,0) [0|255] "" XXX
 SG_ BYTE12 : 96|8@1+ (1,0) [0|255] "" XXX
 SG_ BYTE13 : 104|8@1+ (1,0) [0|255] "" XXX
 SG_ BYTE14 : 112|8@1+ (1,0) [0|255] "" XXX
 SG_ BYTE15 : 120|8@1+ (1,0) [0|255] "" XXX
 SG_ BYTE16 : 128|8@1+ (1,0) [0|255] "" XXX
 SG_ BYTE17 : 136|8@1+ (1,0) [0|255] "" XXX
 SG_ BYTE18 : 144|8@1+ (1,0) [0|255] "" XXX
 SG_ BYTE19 : 152|8@1+ (1,0) [0|255] "" XXX
 SG_ BYTE20 : 160|8@1+ (1,0) [0|255] "" XXX
 SG_ BYTE21 : 168|8@1+ (1,0) [0|255] "" XXX
 SG_ BYTE22 : 176|8@1+ (1,0) [0|255] "" XXX
 SG_ BYTE23 : 184|8@1+ (1,0) [0|255] "" XXX
 SG_ BYTE24 : 192|8@1+ (1,0) [0|255] "" XXX
 SG_ BYTE25 : 200|8@1+ (1,0) [0|255] "" XXX
 SG_ BYTE26 : 208|8@1+ (1,0) [0|255] "" XXX
 SG_ BYTE27 : 216|8@1+ (1,0) [0|255] "" XXX
 SG_ BYTE28 : 224|8@1+ (1,0) [0|255] "" XXX
 SG_ BYTE29 : 232|8@1+ (1,0) [0|255] "" XXX
 SG_ BYTE30 : 240|8@1+ (1,0) [0|255] "" XXX
 SG_ BYTE31 : 248|8@1+ (1,0) [0|255] "" XXX

BO_ 736 MANUAL_SPEED_LIMIT_ASSIST: 32 XXX

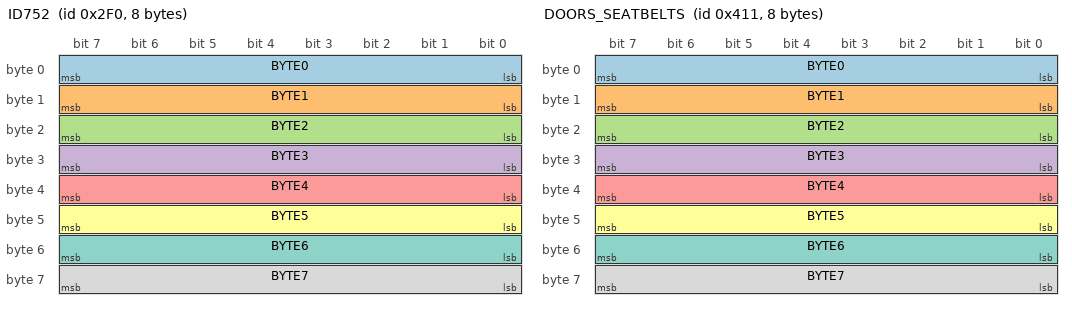
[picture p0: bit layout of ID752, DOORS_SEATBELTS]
BO_ 752 ID752: 8 XXX
 SG_ BYTE0 : 0|8@1+ (1,0) [0|255] "" XXX
 SG_ BYTE1 : 8|8@1+ (1,0) [0|255] "" XXX
 SG_ BYTE2 : 16|8@1+ (1,0) [0|255] "" XXX
 SG_ BYTE3 : 24|8@1+ (1,0) [0|255] "" XXX
 SG_ BYTE4 : 32|8@1+ (1,0) [0|255] "" XXX
 SG_ BYTE5 : 40|8@1+ (1,0) [0|255] "" XXX
 SG_ BYTE6 : 48|8@1+ (1,0) [0|255] "" XXX
 SG_ BYTE7 : 56|8@1+ (1,0) [0|255] "" XXX

BO_ 811 ADRV_0x32b: 32 XXX
 SG_ BYTE0 : 0|8@1+ (1,0) [0|255] "" XXX
 SG_ BYTE1 : 8|8@1+ (1,0) [0|255] "" XXX
 SG_ BYTE2 : 16|8@1+ (1,0) [0|255] "" XXX
 SG_ BYTE3 : 24|8@1+ (1,0) [0|255] "" XXX
 SG_ BYTE4 : 32|8@1+ (1,0) [0|255] "" XXX
 SG_ BYTE5 : 40|8@1+ (1,0) [0|255] "" XXX
 SG_ BYTE6 : 48|8@1+ (1,0) [0|255] "" XXX
 SG_ BYTE7 : 56|8@1+ (1,0) [0|255] "" XXX
 SG_ BYTE8 : 64|8@1+ (1,0) [0|255] "" XXX
 SG_ BYTE9 : 72|8@1+ (1,0) [0|255] "" XXX
 SG_ BYTE10 : 80|8@1+ (1,0) [0|255] "" XXX
 SG_ BYTE11 : 88|8@1+ (1,0) [0|255] "" XXX
 SG_ BYTE12 : 96|8@1+ (1,0) [0|255] "" XXX
 SG_ BYTE13 : 104|8@1+ (1,0) [0|255] "" XXX
 SG_ BYTE14 : 112|8@1+ (1,0) [0|255] "" XXX
 SG_ BYTE15 : 120|8@1+ (1,0) [0|255] "" XXX
 SG_ BYTE16 : 128|8@1+ (1,0) [0|255] "" XXX
 SG_ BYTE17 : 136|8@1+ (1,0) [0|255] "" XXX
 SG_ BYTE18 : 144|8@1+ (1,0) [0|255] "" XXX
 SG_ BYTE19 : 152|8@1+ (1,0) [0|255] "" XXX
 SG_ BYTE20 : 160|8@1+ (1,0) [0|255] "" XXX
 SG_ BYTE21 : 168|8@1+ (1,0) [0|255] "" XXX
 SG_ BYTE22 : 176|8@1+ (1,0) [0|255] "" XXX
 SG_ BYTE23 : 184|8@1+ (1,0) [0|255] "" XXX
 SG_ BYTE24 : 192|8@1+ (1,0) [0|255] "" XXX
 SG_ BYTE25 : 200|8@1+ (1,0) [0|255] "" XXX
 SG_ BYTE26 : 208|8@1+ (1,0) [0|255] "" XXX
 SG_ BYTE27 : 216|8@1+ (1,0) [0|255] "" XXX
 SG_ BYTE28 : 224|8@1+ (1,0) [0|255] "" XXX
 SG_ BYTE29 : 232|8@1+ (1,0) [0|255] "" XXX
 SG_ BYTE30 : 240|8@1+ (1,0) [0|255] "" XXX
 SG_ BYTE31 : 248|8@1+ (1,0) [0|255] "" XXX

BO_ 813 ADRV_0x32d: 32 XXX
 SG_ BYTE0 : 0|8@1+ (1,0) [0|255] "" XXX
 SG_ BYTE1 : 8|8@1+ (1,0) [0|255] "" XXX
 SG_ BYTE2 : 16|8@1+ (1,0) [0|255] "" XXX
 SG_ BYTE3 : 24|8@1+ (1,0) [0|255] "" XXX
 SG_ BYTE4 : 32|8@1+ (1,0) [0|255] "" XXX
 SG_ BYTE5 : 40|8@1+ (1,0) [0|255] "" XXX
 SG_ BYTE6 : 48|8@1+ (1,0) [0|255] "" XXX
 SG_ BYTE7 : 56|8@1+ (1,0) [0|255] "" XXX
 SG_ BYTE8 : 64|8@1+ (1,0) [0|255] "" XXX
 SG_ BYTE9 : 72|8@1+ (1,0) [0|255] "" XXX
 SG_ BYTE10 : 80|8@1+ (1,0) [0|255] "" XXX
 SG_ BYTE11 : 88|8@1+ (1,0) [0|255] "" XXX
 SG_ BYTE12 : 96|8@1+ (1,0) [0|255] "" XXX
 SG_ BYTE13 : 104|8@1+ (1,0) [0|255] "" XXX
 SG_ BYTE14 : 112|8@1+ (1,0) [0|255] "" XXX
 SG_ BYTE15 : 120|8@1+ (1,0) [0|255] "" XXX
 SG_ BYTE16 : 128|8@1+ (1,0) [0|255] "" XXX
 SG_ BYTE17 : 136|8@1+ (1,0) [0|255] "" XXX
 SG_ BYTE18 : 144|8@1+ (1,0) [0|255] "" XXX
 SG_ BYTE19 : 152|8@1+ (1,0) [0|255] "" XXX
 SG_ BYTE20 : 160|8@1+ (1,0) [0|255] "" XXX
 SG_ BYTE21 : 168|8@1+ (1,0) [0|255] "" XXX
 SG_ BYTE22 : 176|8@1+ (1,0) [0|255] "" XXX
 SG_ BYTE23 : 184|8@1+ (1,0) [0|255] "" XXX
 SG_ BYTE24 : 192|8@1+ (1,0) [0|255] "" XXX
 SG_ BYTE25 : 200|8@1+ (1,0) [0|255] "" XXX
 SG_ BYTE26 : 208|8@1+ (1,0) [0|255] "" XXX
 SG_ BYTE27 : 216|8@1+ (1,0) [0|255] "" XXX
 SG_ BYTE28 : 224|8@1+ (1,0) [0|255] "" XXX
 SG_ BYTE29 : 232|8@1+ (1,0) [0|255] "" XXX
 SG_ BYTE30 : 240|8@1+ (1,0) [0|255] "" XXX
 SG_ BYTE31 : 248|8@1+ (1,0) [0|255] "" XXX

BO_ 816 ADRV_0x330: 32 XXX
 SG_ BYTE0 : 0|8@1+ (1,0) [0|255] "" XXX
 SG_ BYTE1 : 8|8@1+ (1,0) [0|255] "" XXX
 SG_ BYTE2 : 16|8@1+ (1,0) [0|255] "" XXX
 SG_ BYTE3 : 24|8@1+ (1,0) [0|255] "" XXX
 SG_ BYTE4 : 32|8@1+ (1,0) [0|255] "" XXX
 SG_ BYTE5 : 40|8@1+ (1,0) [0|255] "" XXX
 SG_ BYTE6 : 48|8@1+ (1,0) [0|255] "" XXX
 SG_ BYTE7 : 56|8@1+ (1,0) [0|255] "" XXX
 SG_ BYTE8 : 64|8@1+ (1,0) [0|255] "" XXX
 SG_ BYTE9 : 72|8@1+ (1,0) [0|255] "" XXX
 SG_ BYTE10 : 80|8@1+ (1,0) [0|255] "" XXX
 SG_ BYTE11 : 88|8@1+ (1,0) [0|255] "" XXX
 SG_ BYTE12 : 96|8@1+ (1,0) [0|255] "" XXX
 SG_ BYTE13 : 104|8@1+ (1,0) [0|255] "" XXX
 SG_ BYTE14 : 112|8@1+ (1,0) [0|255] "" XXX
 SG_ BYTE15 : 120|8@1+ (1,0) [0|255] "" XXX
 SG_ BYTE16 : 128|8@1+ (1,0) [0|255] "" XXX
 SG_ BYTE17 : 136|8@1+ (1,0) [0|255] "" XXX
 SG_ BYTE18 : 144|8@1+ (1,0) [0|255] "" XXX
 SG_ BYTE19 : 152|8@1+ (1,0) [0|255] "" XXX
 SG_ BYTE20 : 160|8@1+ (1,0) [0|255] "" XXX
 SG_ BYTE21 : 168|8@1+ (1,0) [0|255] "" XXX
 SG_ BYTE22 : 176|8@1+ (1,0) [0|255] "" XXX
 SG_ BYTE23 : 184|8@1+ (1,0) [0|255] "" XXX
 SG_ BYTE24 : 192|8@1+ (1,0) [0|255] "" XXX
 SG_ BYTE25 : 200|8@1+ (1,0) [0|255] "" XXX
 SG_ BYTE26 : 208|8@1+ (1,0) [0|255] "" XXX
 SG_ BYTE27 : 216|8@1+ (1,0) [0|255] "" XXX
 SG_ BYTE28 : 224|8@1+ (1,0) [0|255] "" XXX
 SG_ BYTE29 : 232|8@1+ (1,0) [0|255] "" XXX
 SG_ BYTE30 : 240|8@1+ (1,0) [0|255] "" XXX
 SG_ BYTE31 : 248|8@1+ (1,0) [0|255] "" XXX

BO_ 837 ADRV_0x345: 16 XXX
 SG_ BYTE0 : 0|8@1+ (1,0) [0|255] "" XXX
 SG_ BYTE1 : 8|8@1+ (1,0) [0|255] "" XXX
 SG_ BYTE2 : 16|8@1+ (1,0) [0|255] "" XXX
 SG_ BYTE3 : 24|8@1+ (1,0) [0|255] "" XXX
 SG_ BYTE4 : 32|8@1+ (1,0) [0|255] "" XXX
 SG_ BYTE5 : 40|8@1+ (1,0) [0|255] "" XXX
 SG_ BYTE6 : 48|8@1+ (1,0) [0|255] "" XXX
 SG_ BYTE7 : 56|8@1+ (1,0) [0|255] "" XXX
 SG_ BYTE8 : 64|8@1+ (1,0) [0|255] "" XXX
 SG_ BYTE9 : 72|8@1+ (1,0) [0|255] "" XXX
 SG_ BYTE10 : 80|8@1+ (1,0) [0|255] "" XXX
 SG_ BYTE11 : 88|8@1+ (1,0) [0|255] "" XXX
 SG_ BYTE12 : 96|8@1+ (1,0) [0|255] "" XXX
 SG_ BYTE13 : 104|8@1+ (1,0) [0|255] "" XXX
 SG_ BYTE14 : 112|8@1+ (1,0) [0|255] "" XXX
 SG_ BYTE15 : 120|8@1+ (1,0) [0|255] "" XXX

BO_ 864 LFA_BUTTON: 32 XXX
 SG_ LEFT_BLINKER : 0|8@1+ (1,0) [0|255] "" XXX
 SG_ RIGHT_BLINKER : 8|8@1+ (1,0) [0|255] "" XXX
 SG_ LFA_BTN : 16|1@1+ (1,0) [0|1] "" XXX
 SG_ BYTE3 : 24|8@1+ (1,0) [0|255] "" XXX
 SG_ BYTE4 : 32|8@1+ (1,0) [0|255] "" XXX
 SG_ BYTE5 : 40|8@1+ (1,0) [0|255] "" XXX
 SG_ BYTE6 : 48|8@1+ (1,0) [0|255] "" XXX
 SG_ BYTE7 : 56|8@1+ (1,0) [0|255] "" XXX
 SG_ BYTE8 : 64|8@1+ (1,0) [0|255] "" XXX
 SG_ BYTE9 : 72|8@1+ (1,0) [0|255] "" XXX
 SG_ BYTE10 : 80|8@1+ (1,0) [0|255] "" XXX
 SG_ BYTE11 : 88|8@1+ (1,0) [0|255] "" XXX
 SG_ BYTE12 : 96|8@1+ (1,0) [0|255] "" XXX
 SG_ BYTE13 : 104|8@1+ (1,0) [0|255] "" XXX
 SG_ BYTE14 : 112|8@1+ (1,0) [0|255] "" XXX
 SG_ BYTE15 : 120|8@1+ (1,0) [0|255] "" XXX
 SG_ BYTE16 : 128|8@1+ (1,0) [0|255] "" XXX
 SG_ BYTE17 : 136|8@1+ (1,0) [0|255] "" XXX
 SG_ BYTE18 : 144|8@1+ (1,0) [0|255] "" XXX
 SG_ BYTE19 : 152|8@1+ (1,0) [0|255] "" XXX
 SG_ BYTE20 : 160|8@1+ (1,0) [0|255] "" XXX
 SG_ BYTE21 : 168|8@1+ (1,0) [0|255] "" XXX
 SG_ BYTE22 : 176|8@1+ (1,0) [0|255] "" XXX
 SG_ BYTE23 : 184|8@1+ (1,0) [0|255] "" XXX
 SG_ BYTE24 : 192|8@1+ (1,0) [0|255] "" XXX
 SG_ BYTE25 : 200|8@1+ (1,0) [0|255] "" XXX
 SG_ BYTE26 : 208|8@1+ (1,0) [0|255] "" XXX
 SG_ BYTE27 : 216|8@1+ (1,0) [0|255] "" XXX
 SG_ BYTE28 : 224|8@1+ (1,0) [0|255] "" XXX
 SG_ BYTE29 : 232|8@1+ (1,0) [0|255] "" XXX
 SG_ BYTE30 : 240|8@1+ (1,0) [0|255] "" XXX
 SG_ BYTE31 : 248|8@1+ (1,0) [0|255] "" XXX

BO_ 865 ID865: 32 XXX
 SG_ BYTE0 : 0|8@1+ (1,0) [0|255] "" XXX
 SG_ BYTE1 : 8|8@1+ (1,0) [0|255] "" XXX
 SG_ BYTE2 : 16|8@1+ (1,0) [0|255] "" XXX
 SG_ BYTE3 : 24|8@1+ (1,0) [0|255] "" XXX
 SG_ BYTE4 : 32|8@1+ (1,0) [0|255] "" XXX
 SG_ BYTE5 : 40|8@1+ (1,0) [0|255] "" XXX
 SG_ BYTE6 : 48|8@1+ (1,0) [0|255] "" XXX
 SG_ BYTE7 : 56|8@1+ (1,0) [0|255] "" XXX
 SG_ BYTE8 : 64|8@1+ (1,0) [0|255] "" XXX
 SG_ BYTE9 : 72|8@1+ (1,0) [0|255] "" XXX
 SG_ BYTE10 : 80|8@1+ (1,0) [0|255] "" XXX
 SG_ BYTE11 : 88|8@1+ (1,0) [0|255] "" XXX
 SG_ BYTE12 : 96|8@1+ (1,0) [0|255] "" XXX
 SG_ BYTE13 : 104|8@1+ (1,0) [0|255] "" XXX
 SG_ BYTE14 : 112|8@1+ (1,0) [0|255] "" XXX
 SG_ BYTE15 : 120|8@1+ (1,0) [0|255] "" XXX
 SG_ BYTE16 : 128|8@1+ (1,0) [0|255] "" XXX
 SG_ BYTE17 : 136|8@1+ (1,0) [0|255] "" XXX
 SG_ BYTE18 : 144|8@1+ (1,0) [0|255] "" XXX
 SG_ BYTE19 : 152|8@1+ (1,0) [0|255] "" XXX
 SG_ BYTE20 : 160|8@1+ (1,0) [0|255] "" XXX
 SG_ BYTE21 : 168|8@1+ (1,0) [0|255] "" XXX
 SG_ BYTE22 : 176|8@1+ (1,0) [0|255] "" XXX
 SG_ BYTE23 : 184|8@1+ (1,0) [0|255] "" XXX
 SG_ BYTE24 : 192|8@1+ (1,0) [0|255] "" XXX
 SG_ BYTE25 : 200|8@1+ (1,0) [0|255] "" XXX
 SG_ BYTE26 : 208|8@1+ (1,0) [0|255] "" XXX
 SG_ BYTE27 : 216|8@1+ (1,0) [0|255] "" XXX
 SG_ BYTE28 : 224|8@1+ (1,0) [0|255] "" XXX
 SG_ BYTE29 : 232|8@1+ (1,0) [0|255] "" XXX
 SG_ BYTE30 : 240|8@1+ (1,0) [0|255] "" XXX
 SG_ BYTE31 : 248|8@1+ (1,0) [0|255] "" XXX

BO_ 866 CAM_0x362: 32 XXX
 SG_ BYTE0 : 0|8@1+ (1,0) [0|255] "" XXX
 SG_ BYTE1 : 8|8@1+ (1,0) [0|255] "" XXX
 SG_ BYTE2 : 16|8@1+ (1,0) [0|255] "" XXX
 SG_ BYTE3 : 24|8@1+ (1,0) [0|255] "" XXX
 SG_ BYTE4 : 32|8@1+ (1,0) [0|255] "" XXX
 SG_ BYTE5 : 40|8@1+ (1,0) [0|255] "" XXX
 SG_ BYTE6 : 48|8@1+ (1,0) [0|255] "" XXX
 SG_ BYTE7 : 56|8@1+ (1,0) [0|255] "" XXX
 SG_ BYTE8 : 64|8@1+ (1,0) [0|255] "" XXX
 SG_ BYTE9 : 72|8@1+ (1,0) [0|255] "" XXX
 SG_ BYTE10 : 80|8@1+ (1,0) [0|255] "" XXX
 SG_ BYTE11 : 88|8@1+ (1,0) [0|255] "" XXX
 SG_ BYTE12 : 96|8@1+ (1,0) [0|255] "" XXX
 SG_ BYTE13 : 104|8@1+ (1,0) [0|255] "" XXX
 SG_ BYTE14 : 112|8@1+ (1,0) [0|255] "" XXX
 SG_ BYTE15 : 120|8@1+ (1,0) [0|255] "" XXX
 SG_ BYTE16 : 128|8@1+ (1,0) [0|255] "" XXX
 SG_ BYTE17 : 136|8@1+ (1,0) [0|255] "" XXX
 SG_ BYTE18 : 144|8@1+ (1,0) [0|255] "" XXX
 SG_ BYTE19 : 152|8@1+ (1,0) [0|255] "" XXX
 SG_ BYTE20 : 160|8@1+ (1,0) [0|255] "" XXX
 SG_ BYTE21 : 168|8@1+ (1,0) [0|255] "" XXX
 SG_ BYTE22 : 176|8@1+ (1,0) [0|255] "" XXX
 SG_ BYTE23 : 184|8@1+ (1,0) [0|255] "" XXX
 SG_ BYTE24 : 192|8@1+ (1,0) [0|255] "" XXX
 SG_ BYTE25 : 200|8@1+ (1,0) [0|255] "" XXX
 SG_ BYTE26 : 208|8@1+ (1,0) [0|255] "" XXX
 SG_ BYTE27 : 216|8@1+ (1,0) [0|255] "" XXX
 SG_ BYTE28 : 224|8@1+ (1,0) [0|255] "" XXX
 SG_ BYTE29 : 232|8@1+ (1,0) [0|255] "" XXX
 SG_ BYTE30 : 240|8@1+ (1,0) [0|255] "" XXX
 SG_ BYTE31 : 248|8@1+ (1,0) [0|255] "" XXX

BO_ 867 CAM_0x363: 32 XXX
 SG_ BYTE0 : 0|8@1+ (1,0) [0|255] "" XXX
 SG_ BYTE1 : 8|8@1+ (1,0) [0|255] "" XXX
 SG_ BYTE2 : 16|8@1+ (1,0) [0|255] "" XXX
 SG_ BYTE3 : 24|8@1+ (1,0) [0|255] "" XXX
 SG_ BYTE4 : 32|8@1+ (1,0) [0|255] "" XXX
 SG_ BYTE5 : 40|8@1+ (1,0) [0|255] "" XXX
 SG_ BYTE6 : 48|8@1+ (1,0) [0|255] "" XXX
 SG_ BYTE7 : 56|8@1+ (1,0) [0|255] "" XXX
 SG_ BYTE8 : 64|8@1+ (1,0) [0|255] "" XXX
 SG_ BYTE9 : 72|8@1+ (1,0) [0|255] "" XXX
 SG_ BYTE10 : 80|8@1+ (1,0) [0|255] "" XXX
 SG_ BYTE11 : 88|8@1+ (1,0) [0|255] "" XXX
 SG_ BYTE12 : 96|8@1+ (1,0) [0|255] "" XXX
 SG_ BYTE13 : 104|8@1+ (1,0) [0|255] "" XXX
 SG_ BYTE14 : 112|8@1+ (1,0) [0|255] "" XXX
 SG_ BYTE15 : 120|8@1+ (1,0) [0|255] "" XXX
 SG_ BYTE16 : 128|8@1+ (1,0) [0|255] "" XXX
 SG_ BYTE17 : 136|8@1+ (1,0) [0|255] "" XXX
 SG_ BYTE18 : 144|8@1+ (1,0) [0|255] "" XXX
 SG_ BYTE19 : 152|8@1+ (1,0) [0|255] "" XXX
 SG_ BYTE20 : 160|8@1+ (1,0) [0|255] "" XXX
 SG_ BYTE21 : 168|8@1+ (1,0) [0|255] "" XXX
 SG_ BYTE22 : 176|8@1+ (1,0) [0|255] "" XXX
 SG_ BYTE23 : 184|8@1+ (1,0) [0|255] "" XXX
 SG_ BYTE24 : 192|8@1+ (1,0) [0|255] "" XXX
 SG_ BYTE25 : 200|8@1+ (1,0) [0|255] "" XXX
 SG_ BYTE26 : 208|8@1+ (1,0) [0|255] "" XXX
 SG_ BYTE27 : 216|8@1+ (1,0) [0|255] "" XXX
 SG_ BYTE28 : 224|8@1+ (1,0) [0|255] "" XXX
 SG_ BYTE29 : 232|8@1+ (1,0) [0|255] "" XXX
 SG_ BYTE30 : 240|8@1+ (1,0) [0|255] "" XXX
 SG_ BYTE31 : 248|8@1+ (1,0) [0|255] "" XXX

BO_ 868 CAM_0x364: 32 XXX
 SG_ BYTE0 : 0|8@1+ (1,0) [0|255] "" XXX
 SG_ BYTE1 : 8|8@1+ (1,0) [0|255] "" XXX
 SG_ BYTE2 : 16|8@1+ (1,0) [0|255] "" XXX
 SG_ BYTE3 : 24|8@1+ (1,0) [0|255] "" XXX
 SG_ BYTE4 : 32|8@1+ (1,0) [0|255] "" XXX
 SG_ BYTE5 : 40|8@1+ (1,0) [0|255] "" XXX
 SG_ BYTE6 : 48|8@1+ (1,0) [0|255] "" XXX
 SG_ BYTE7 : 56|8@1+ (1,0) [0|255] "" XXX
 SG_ BYTE8 : 64|8@1+ (1,0) [0|255] "" XXX
 SG_ BYTE9 : 72|8@1+ (1,0) [0|255] "" XXX
 SG_ BYTE10 : 80|8@1+ (1,0) [0|255] "" XXX
 SG_ BYTE11 : 88|8@1+ (1,0) [0|255] "" XXX
 SG_ BYTE12 : 96|8@1+ (1,0) [0|255] "" XXX
 SG_ BYTE13 : 104|8@1+ (1,0) [0|255] "" XXX
 SG_ BYTE14 : 112|8@1+ (1,0) [0|255] "" XXX
 SG_ BYTE15 : 120|8@1+ (1,0) [0|255] "" XXX
 SG_ BYTE16 : 128|8@1+ (1,0) [0|255] "" XXX
 SG_ BYTE17 : 136|8@1+ (1,0) [0|255] "" XXX
 SG_ BYTE18 : 144|8@1+ (1,0) [0|255] "" XXX
 SG_ BYTE19 : 152|8@1+ (1,0) [0|255] "" XXX
 SG_ BYTE20 : 160|8@1+ (1,0) [0|255] "" XXX
 SG_ BYTE21 : 168|8@1+ (1,0) [0|255] "" XXX
 SG_ BYTE22 : 176|8@1+ (1,0) [0|255] "" XXX
 SG_ BYTE23 : 184|8@1+ (1,0) [0|255] "" XXX
 SG_ BYTE24 : 192|8@1+ (1,0) [0|255] "" XXX
 SG_ BYTE25 : 200|8@1+ (1,0) [0|255] "" XXX
 SG_ BYTE26 : 208|8@1+ (1,0) [0|255] "" XXX
 SG_ BYTE27 : 216|8@1+ (1,0) [0|255] "" XXX
 SG_ BYTE28 : 224|8@1+ (1,0) [0|255] "" XXX
 SG_ BYTE29 : 232|8@1+ (1,0) [0|255] "" XXX
 SG_ BYTE30 : 240|8@1+ (1,0) [0|255] "" XXX
 SG_ BYTE31 : 248|8@1+ (1,0) [0|255] "" XXX

BO_ 896 ADRV_0x380: 24 XXX
 SG_ BYTE0 : 0|8@1+ (1,0) [0|255] "" XXX
 SG_ BYTE1 : 8|8@1+ (1,0) [0|255] "" XXX
 SG_ BYTE2 : 16|8@1+ (1,0) [0|255] "" XXX
 SG_ BYTE3 : 24|8@1+ (1,0) [0|255] "" XXX
 SG_ BYTE4 : 32|8@1+ (1,0) [0|255] "" XXX
 SG_ BYTE5 : 40|8@1+ (1,0) [0|255] "" XXX
 SG_ BYTE6 : 48|8@1+ (1,0) [0|255] "" XXX
 SG_ BYTE7 : 56|8@1+ (1,0) [0|255] "" XXX
 SG_ BYTE8 : 64|8@1+ (1,0) [0|255] "" XXX
 SG_ BYTE9 : 72|8@1+ (1,0) [0|255] "" XXX
 SG_ BYTE10 : 80|8@1+ (1,0) [0|255] "" XXX
 SG_ BYTE11 : 88|8@1+ (1,0) [0|255] "" XXX
 SG_ BYTE12 : 96|8@1+ (1,0) [0|255] "" XXX
 SG_ BYTE13 : 104|8@1+ (1,0) [0|255] "" XXX
 SG_ BYTE14 : 112|8@1+ (1,0) [0|255] "" XXX
 SG_ BYTE15 : 120|8@1+ (1,0) [0|255] "" XXX
 SG_ BYTE16 : 128|8@1+ (1,0) [0|255] "" XXX
 SG_ BYTE17 : 136|8@1+ (1,0) [0|255] "" XXX
 SG_ BYTE18 : 144|8@1+ (1,0) [0|255] "" XXX
 SG_ BYTE19 : 152|8@1+ (1,0) [0|255] "" XXX
 SG_ BYTE20 : 160|8@1+ (1,0) [0|255] "" XXX
 SG_ BYTE21 : 168|8@1+ (1,0) [0|255] "" XXX
 SG_ BYTE22 : 176|8@1+ (1,0) [0|255] "" XXX
 SG_ BYTE23 : 184|8@1+ (1,0) [0|255] "" XXX

BO_ 905 ADRV_0x389: 24 XXX
 SG_ BYTE0 : 0|8@1+ (1,0) [0|255] "" XXX
 SG_ BYTE1 : 8|8@1+ (1,0) [0|255] "" XXX
 SG_ BYTE2 : 16|8@1+ (1,0) [0|255] "" XXX
 SG_ BYTE3 : 24|8@1+ (1,0) [0|255] "" XXX
 SG_ BYTE4 : 32|8@1+ (1,0) [0|255] "" XXX
 SG_ BYTE5 : 40|8@1+ (1,0) [0|255] "" XXX
 SG_ BYTE6 : 48|8@1+ (1,0) [0|255] "" XXX
 SG_ BYTE7 : 56|8@1+ (1,0) [0|255] "" XXX
 SG_ BYTE8 : 64|8@1+ (1,0) [0|255] "" XXX
 SG_ BYTE9 : 72|8@1+ (1,0) [0|255] "" XXX
 SG_ BYTE10 : 80|8@1+ (1,0) [0|255] "" XXX
 SG_ BYTE11 : 88|8@1+ (1,0) [0|255] "" XXX
 SG_ BYTE12 : 96|8@1+ (1,0) [0|255] "" XXX
 SG_ BYTE13 : 104|8@1+ (1,0) [0|255] "" XXX
 SG_ BYTE14 : 112|8@1+ (1,0) [0|255] "" XXX
 SG_ BYTE15 : 120|8@1+ (1,0) [0|255] "" XXX
 SG_ BYTE16 : 128|8@1+ (1,0) [0|255] "" XXX
 SG_ BYTE17 : 136|8@1+ (1,0) [0|255] "" XXX
 SG_ BYTE18 : 144|8@1+ (1,0) [0|255] "" XXX
 SG_ BYTE19 : 152|8@1+ (1,0) [0|255] "" XXX
 SG_ BYTE20 : 160|8@1+ (1,0) [0|255] "" XXX
 SG_ BYTE21 : 168|8@1+ (1,0) [0|255] "" XXX
 SG_ BYTE22 : 176|8@1+ (1,0) [0|255] "" XXX
 SG_ BYTE23 : 184|8@1+ (1,0) [0|255] "" XXX

BO_ 917 ID917: 32 XXX
 SG_ BYTE0 : 0|8@1+ (1,0) [0|255] "" XXX
 SG_ BYTE1 : 8|8@1+ (1,0) [0|255] "" XXX
 SG_ BYTE2 : 16|8@1+ (1,0) [0|255] "" XXX
 SG_ BYTE3 : 24|8@1+ (1,0) [0|255] "" XXX
 SG_ BYTE4 : 32|8@1+ (1,0) [0|255] "" XXX
 SG_ BYTE5 : 40|8@1+ (1,0) [0|255] "" XXX
 SG_ BYTE6 : 48|8@1+ (1,0) [0|255] "" XXX
 SG_ BYTE7 : 56|8@1+ (1,0) [0|255] "" XXX
 SG_ BYTE8 : 64|8@1+ (1,0) [0|255] "" XXX
 SG_ BYTE9 : 72|8@1+ (1,0) [0|255] "" XXX
 SG_ BYTE10 : 80|8@1+ (1,0) [0|255] "" XXX
 SG_ BYTE11 : 88|8@1+ (1,0) [0|255] "" XXX
 SG_ BYTE12 : 96|8@1+ (1,0) [0|255] "" XXX
 SG_ BYTE13 : 104|8@1+ (1,0) [0|255] "" XXX
 SG_ BYTE14 : 112|8@1+ (1,0) [0|255] "" XXX
 SG_ BYTE15 : 120|8@1+ (1,0) [0|255] "" XXX
 SG_ BYTE16 : 128|8@1+ (1,0) [0|255] "" XXX
 SG_ BYTE17 : 136|8@1+ (1,0) [0|255] "" XXX
 SG_ BYTE18 : 144|8@1+ (1,0) [0|255] "" XXX
 SG_ BYTE19 : 152|8@1+ (1,0) [0|255] "" XXX
 SG_ BYTE20 : 160|8@1+ (1,0) [0|255] "" XXX
 SG_ BYTE21 : 168|8@1+ (1,0) [0|255] "" XXX
 SG_ BYTE22 : 176|8@1+ (1,0) [0|255] "" XXX
 SG_ BYTE23 : 184|8@1+ (1,0) [0|255] "" XXX
 SG_ BYTE24 : 192|8@1+ (1,0) [0|255] "" XXX
 SG_ BYTE25 : 200|8@1+ (1,0) [0|255] "" XXX
 SG_ BYTE26 : 208|8@1+ (1,0) [0|255] "" XXX
 SG_ BYTE27 : 216|8@1+ (1,0) [0|255] "" XXX
 SG_ BYTE28 : 224|8@1+ (1,0) [0|255] "" XXX
 SG_ BYTE29 : 232|8@1+ (1,0) [0|255] "" XXX
 SG_ BYTE30 : 240|8@1+ (1,0) [0|255] "" XXX
 SG_ BYTE31 : 248|8@1+ (1,0) [0|255] "" XXX

BO_ 928 ID928: 32 XXX
 SG_ BYTE0 : 0|8@1+ (1,0) [0|255] "" XXX
 SG_ BYTE1 : 8|8@1+ (1,0) [0|255] "" XXX
 SG_ BYTE2 : 16|8@1+ (1,0) [0|255] "" XXX
 SG_ BYTE3 : 24|8@1+ (1,0) [0|255] "" XXX
 SG_ BYTE4 : 32|8@1+ (1,0) [0|255] "" XXX
 SG_ BYTE5 : 40|8@1+ (1,0) [0|255] "" XXX
 SG_ BYTE6 : 48|8@1+ (1,0) [0|255] "" XXX
 SG_ BYTE7 : 56|8@1+ (1,0) [0|255] "" XXX
 SG_ BYTE8 : 64|8@1+ (1,0) [0|255] "" XXX
 SG_ BYTE9 : 72|8@1+ (1,0) [0|255] "" XXX
 SG_ BYTE10 : 80|8@1+ (1,0) [0|255] "" XXX
 SG_ BYTE11 : 88|8@1+ (1,0) [0|255] "" XXX
 SG_ BYTE12 : 96|8@1+ (1,0) [0|255] "" XXX
 SG_ BYTE13 : 104|8@1+ (1,0) [0|255] "" XXX
 SG_ BYTE14 : 112|8@1+ (1,0) [0|255] "" XXX
 SG_ BYTE15 : 120|8@1+ (1,0) [0|255] "" XXX
 SG_ BYTE16 : 128|8@1+ (1,0) [0|255] "" XXX
 SG_ BYTE17 : 136|8@1+ (1,0) [0|255] "" XXX
 SG_ BYTE18 : 144|8@1+ (1,0) [0|255] "" XXX
 SG_ BYTE19 : 152|8@1+ (1,0) [0|255] "" XXX
 SG_ BYTE20 : 160|8@1+ (1,0) [0|255] "" XXX
 SG_ BYTE21 : 168|8@1+ (1,0) [0|255] "" XXX
 SG_ BYTE22 : 176|8@1+ (1,0) [0|255] "" XXX
 SG_ BYTE23 : 184|8@1+ (1,0) [0|255] "" XXX
 SG_ BYTE24 : 192|8@1+ (1,0) [0|255] "" XXX
 SG_ BYTE25 : 200|8@1+ (1,0) [0|255] "" XXX
 SG_ BYTE26 : 208|8@1+ (1,0) [0|255] "" XXX
 SG_ BYTE27 : 216|8@1+ (1,0) [0|255] "" XXX
 SG_ BYTE28 : 224|8@1+ (1,0) [0|255] "" XXX
 SG_ BYTE29 : 232|8@1+ (1,0) [0|255] "" XXX
 SG_ BYTE30 : 240|8@1+ (1,0) [0|255] "" XXX
 SG_ BYTE31 : 248|8@1+ (1,0) [0|255] "" XXX

BO_ 933 RADAR_TRACK_933: 24 XXX
 SG_ BYTE0 : 0|8@1+ (1,0) [0|255] "" XXX
 SG_ BYTE1 : 8|8@1+ (1,0) [0|255] "" XXX
 SG_ BYTE2 : 16|8@1+ (1,0) [0|255] "" XXX
 SG_ BYTE3 : 24|8@1+ (1,0) [0|255] "" XXX
 SG_ BYTE4 : 32|8@1+ (1,0) [0|255] "" XXX
 SG_ BYTE5 : 40|8@1+ (1,0) [0|255] "" XXX
 SG_ BYTE6 : 48|8@1+ (1,0) [0|255] "" XXX
 SG_ BYTE7 : 56|8@1+ (1,0) [0|255] "" XXX
 SG_ BYTE8 : 64|8@1+ (1,0) [0|255] "" XXX
 SG_ BYTE9 : 72|8@1+ (1,0) [0|255] "" XXX
 SG_ BYTE10 : 80|8@1+ (1,0) [0|255] "" XXX
 SG_ BYTE11 : 88|8@1+ (1,0) [0|255] "" XXX
 SG_ BYTE12 : 96|8@1+ (1,0) [0|255] "" XXX
 SG_ BYTE13 : 104|8@1+ (1,0) [0|255] "" XXX
 SG_ BYTE14 : 112|8@1+ (1,0) [0|255] "" XXX
 SG_ BYTE15 : 120|8@1+ (1,0) [0|255] "" XXX
 SG_ BYTE16 : 128|8@1+ (1,0) [0|255] "" XXX
 SG_ BYTE17 : 136|8@1+ (1,0) [0|255] "" XXX
 SG_ BYTE18 : 144|8@1+ (1,0) [0|255] "" XXX
 SG_ BYTE19 : 152|8@1+ (1,0) [0|255] "" XXX
 SG_ BYTE20 : 160|8@1+ (1,0) [0|255] "" XXX
 SG_ BYTE21 : 168|8@1+ (1,0) [0|255] "" XXX
 SG_ BYTE22 : 176|8@1+ (1,0) [0|255] "" XXX
 SG_ BYTE23 : 184|8@1+ (1,0) [0|255] "" XXX

BO_ 934 RADAR_TRACK_934: 24 XXX
 SG_ BYTE0 : 0|8@1+ (1,0) [0|255] "" XXX
 SG_ BYTE1 : 8|8@1+ (1,0) [0|255] "" XXX
 SG_ BYTE2 : 16|8@1+ (1,0) [0|255] "" XXX
 SG_ BYTE3 : 24|8@1+ (1,0) [0|255] "" XXX
 SG_ BYTE4 : 32|8@1+ (1,0) [0|255] "" XXX
 SG_ BYTE5 : 40|8@1+ (1,0) [0|255] "" XXX
 SG_ BYTE6 : 48|8@1+ (1,0) [0|255] "" XXX
 SG_ BYTE7 : 56|8@1+ (1,0) [0|255] "" XXX
 SG_ BYTE8 : 64|8@1+ (1,0) [0|255] "" XXX
 SG_ BYTE9 : 72|8@1+ (1,0) [0|255] "" XXX
 SG_ BYTE10 : 80|8@1+ (1,0) [0|255] "" XXX
 SG_ BYTE11 : 88|8@1+ (1,0) [0|255] "" XXX
 SG_ BYTE12 : 96|8@1+ (1,0) [0|255] "" XXX
 SG_ BYTE13 : 104|8@1+ (1,0) [0|255] "" XXX
 SG_ BYTE14 : 112|8@1+ (1,0) [0|255] "" XXX
 SG_ BYTE15 : 120|8@1+ (1,0) [0|255] "" XXX
 SG_ BYTE16 : 128|8@1+ (1,0) [0|255] "" XXX
 SG_ BYTE17 : 136|8@1+ (1,0) [0|255] "" XXX
 SG_ BYTE18 : 144|8@1+ (1,0) [0|255] "" XXX
 SG_ BYTE19 : 152|8@1+ (1,0) [0|255] "" XXX
 SG_ BYTE20 : 160|8@1+ (1,0) [0|255] "" XXX
 SG_ BYTE21 : 168|8@1+ (1,0) [0|255] "" XXX
 SG_ BYTE22 : 176|8@1+ (1,0) [0|255] "" XXX
 SG_ BYTE23 : 184|8@1+ (1,0) [0|255] "" XXX

BO_ 935 RADAR_TRACK_935: 24 XXX
 SG_ BYTE0 : 0|8@1+ (1,0) [0|255] "" XXX
 SG_ BYTE1 : 8|8@1+ (1,0) [0|255] "" XXX
 SG_ BYTE2 : 16|8@1+ (1,0) [0|255] "" XXX
 SG_ BYTE3 : 24|8@1+ (1,0) [0|255] "" XXX
 SG_ BYTE4 : 32|8@1+ (1,0) [0|255] "" XXX
 SG_ BYTE5 : 40|8@1+ (1,0) [0|255] "" XXX
 SG_ BYTE6 : 48|8@1+ (1,0) [0|255] "" XXX
 SG_ BYTE7 : 56|8@1+ (1,0) [0|255] "" XXX
 SG_ BYTE8 : 64|8@1+ (1,0) [0|255] "" XXX
 SG_ BYTE9 : 72|8@1+ (1,0) [0|255] "" XXX
 SG_ BYTE10 : 80|8@1+ (1,0) [0|255] "" XXX
 SG_ BYTE11 : 88|8@1+ (1,0) [0|255] "" XXX
 SG_ BYTE12 : 96|8@1+ (1,0) [0|255] "" XXX
 SG_ BYTE13 : 104|8@1+ (1,0) [0|255] "" XXX
 SG_ BYTE14 : 112|8@1+ (1,0) [0|255] "" XXX
 SG_ BYTE15 : 120|8@1+ (1,0) [0|255] "" XXX
 SG_ BYTE16 : 128|8@1+ (1,0) [0|255] "" XXX
 SG_ BYTE17 : 136|8@1+ (1,0) [0|255] "" XXX
 SG_ BYTE18 : 144|8@1+ (1,0) [0|255] "" XXX
 SG_ BYTE19 : 152|8@1+ (1,0) [0|255] "" XXX
 SG_ BYTE20 : 160|8@1+ (1,0) [0|255] "" XXX
 SG_ BYTE21 : 168|8@1+ (1,0) [0|255] "" XXX
 SG_ BYTE22 : 176|8@1+ (1,0) [0|255] "" XXX
 SG_ BYTE23 : 184|8@1+ (1,0) [0|255] "" XXX

BO_ 936 RADAR_TRACK_936: 24 XXX
 SG_ BYTE0 : 0|8@1+ (1,0) [0|255] "" XXX
 SG_ BYTE1 : 8|8@1+ (1,0) [0|255] "" XXX
 SG_ BYTE2 : 16|8@1+ (1,0) [0|255] "" XXX
 SG_ BYTE3 : 24|8@1+ (1,0) [0|255] "" XXX
 SG_ BYTE4 : 32|8@1+ (1,0) [0|255] "" XXX
 SG_ BYTE5 : 40|8@1+ (1,0) [0|255] "" XXX
 SG_ BYTE6 : 48|8@1+ (1,0) [0|255] "" XXX
 SG_ BYTE7 : 56|8@1+ (1,0) [0|255] "" XXX
 SG_ BYTE8 : 64|8@1+ (1,0) [0|255] "" XXX
 SG_ BYTE9 : 72|8@1+ (1,0) [0|255] "" XXX
 SG_ BYTE10 : 80|8@1+ (1,0) [0|255] "" XXX
 SG_ BYTE11 : 88|8@1+ (1,0) [0|255] "" XXX
 SG_ BYTE12 : 96|8@1+ (1,0) [0|255] "" XXX
 SG_ BYTE13 : 104|8@1+ (1,0) [0|255] "" XXX
 SG_ BYTE14 : 112|8@1+ (1,0) [0|255] "" XXX
 SG_ BYTE15 : 120|8@1+ (1,0) [0|255] "" XXX
 SG_ BYTE16 : 128|8@1+ (1,0) [0|255] "" XXX
 SG_ BYTE17 : 136|8@1+ (1,0) [0|255] "" XXX
 SG_ BYTE18 : 144|8@1+ (1,0) [0|255] "" XXX
 SG_ BYTE19 : 152|8@1+ (1,0) [0|255] "" XXX
 SG_ BYTE20 : 160|8@1+ (1,0) [0|255] "" XXX
 SG_ BYTE21 : 168|8@1+ (1,0) [0|255] "" XXX
 SG_ BYTE22 : 176|8@1+ (1,0) [0|255] "" XXX
 SG_ BYTE23 : 184|8@1+ (1,0) [0|255] "" XXX

BO_ 937 RADAR_TRACK_937: 24 XXX
 SG_ BYTE0 : 0|8@1+ (1,0) [0|255] "" XXX
 SG_ BYTE1 : 8|8@1+ (1,0) [0|255] "" XXX
 SG_ BYTE2 : 16|8@1+ (1,0) [0|255] "" XXX
 SG_ BYTE3 : 24|8@1+ (1,0) [0|255] "" XXX
 SG_ BYTE4 : 32|8@1+ (1,0) [0|255] "" XXX
 SG_ BYTE5 : 40|8@1+ (1,0) [0|255] "" XXX
 SG_ BYTE6 : 48|8@1+ (1,0) [0|255] "" XXX
 SG_ BYTE7 : 56|8@1+ (1,0) [0|255] "" XXX
 SG_ BYTE8 : 64|8@1+ (1,0) [0|255] "" XXX
 SG_ BYTE9 : 72|8@1+ (1,0) [0|255] "" XXX
 SG_ BYTE10 : 80|8@1+ (1,0) [0|255] "" XXX
 SG_ BYTE11 : 88|8@1+ (1,0) [0|255] "" XXX
 SG_ BYTE12 : 96|8@1+ (1,0) [0|255] "" XXX
 SG_ BYTE13 : 104|8@1+ (1,0) [0|255] "" XXX
 SG_ BYTE14 : 112|8@1+ (1,0) [0|255] "" XXX
 SG_ BYTE15 : 120|8@1+ (1,0) [0|255] "" XXX
 SG_ BYTE16 : 128|8@1+ (1,0) [0|255] "" XXX
 SG_ BYTE17 : 136|8@1+ (1,0) [0|255] "" XXX
 SG_ BYTE18 : 144|8@1+ (1,0) [0|255] "" XXX
 SG_ BYTE19 : 152|8@1+ (1,0) [0|255] "" XXX
 SG_ BYTE20 : 160|8@1+ (1,0) [0|255] "" XXX
 SG_ BYTE21 : 168|8@1+ (1,0) [0|255] "" XXX
 SG_ BYTE22 : 176|8@1+ (1,0) [0|255] "" XXX
 SG_ BYTE23 : 184|8@1+ (1,0) [0|255] "" XXX

BO_ 938 RADAR_TRACK_938: 24 XXX
 SG_ BYTE0 : 0|8@1+ (1,0) [0|255] "" XXX
 SG_ BYTE1 : 8|8@1+ (1,0) [0|255] "" XXX
 SG_ BYTE2 : 16|8@1+ (1,0) [0|255] "" XXX
 SG_ BYTE3 : 24|8@1+ (1,0) [0|255] "" XXX
 SG_ BYTE4 : 32|8@1+ (1,0) [0|255] "" XXX
 SG_ BYTE5 : 40|8@1+ (1,0) [0|255] "" XXX
 SG_ BYTE6 : 48|8@1+ (1,0) [0|255] "" XXX
 SG_ BYTE7 : 56|8@1+ (1,0) [0|255] "" XXX
 SG_ BYTE8 : 64|8@1+ (1,0) [0|255] "" XXX
 SG_ BYTE9 : 72|8@1+ (1,0) [0|255] "" XXX
 SG_ BYTE10 : 80|8@1+ (1,0) [0|255] "" XXX
 SG_ BYTE11 : 88|8@1+ (1,0) [0|255] "" XXX
 SG_ BYTE12 : 96|8@1+ (1,0) [0|255] "" XXX
 SG_ BYTE13 : 104|8@1+ (1,0) [0|255] "" XXX
 SG_ BYTE14 : 112|8@1+ (1,0) [0|255] "" XXX
 SG_ BYTE15 : 120|8@1+ (1,0) [0|255] "" XXX
 SG_ BYTE16 : 128|8@1+ (1,0) [0|255] "" XXX
 SG_ BYTE17 : 136|8@1+ (1,0) [0|255] "" XXX
 SG_ BYTE18 : 144|8@1+ (1,0) [0|255] "" XXX
 SG_ BYTE19 : 152|8@1+ (1,0) [0|255] "" XXX
 SG_ BYTE20 : 160|8@1+ (1,0) [0|255] "" XXX
 SG_ BYTE21 : 168|8@1+ (1,0) [0|255] "" XXX
 SG_ BYTE22 : 176|8@1+ (1,0) [0|255] "" XXX
 SG_ BYTE23 : 184|8@1+ (1,0) [0|255] "" XXX

BO_ 939 RADAR_TRACK_939: 24 XXX
 SG_ BYTE0 : 0|8@1+ (1,0) [0|255] "" XXX
 SG_ BYTE1 : 8|8@1+ (1,0) [0|255] "" XXX
 SG_ BYTE2 : 16|8@1+ (1,0) [0|255] "" XXX
 SG_ BYTE3 : 24|8@1+ (1,0) [0|255] "" XXX
 SG_ BYTE4 : 32|8@1+ (1,0) [0|255] "" XXX
 SG_ BYTE5 : 40|8@1+ (1,0) [0|255] "" XXX
 SG_ BYTE6 : 48|8@1+ (1,0) [0|255] "" XXX
 SG_ BYTE7 : 56|8@1+ (1,0) [0|255] "" XXX
 SG_ BYTE8 : 64|8@1+ (1,0) [0|255] "" XXX
 SG_ BYTE9 : 72|8@1+ (1,0) [0|255] "" XXX
 SG_ BYTE10 : 80|8@1+ (1,0) [0|255] "" XXX
 SG_ BYTE11 : 88|8@1+ (1,0) [0|255] "" XXX
 SG_ BYTE12 : 96|8@1+ (1,0) [0|255] "" XXX
 SG_ BYTE13 : 104|8@1+ (1,0) [0|255] "" XXX
 SG_ BYTE14 : 112|8@1+ (1,0) [0|255] "" XXX
 SG_ BYTE15 : 120|8@1+ (1,0) [0|255] "" XXX
 SG_ BYTE16 : 128|8@1+ (1,0) [0|255] "" XXX
 SG_ BYTE17 : 136|8@1+ (1,0) [0|255] "" XXX
 SG_ BYTE18 : 144|8@1+ (1,0) [0|255] "" XXX
 SG_ BYTE19 : 152|8@1+ (1,0) [0|255] "" XXX
 SG_ BYTE20 : 160|8@1+ (1,0) [0|255] "" XXX
 SG_ BYTE21 : 168|8@1+ (1,0) [0|255] "" XXX
 SG_ BYTE22 : 176|8@1+ (1,0) [0|255] "" XXX
 SG_ BYTE23 : 184|8@1+ (1,0) [0|255] "" XXX

BO_ 940 RADAR_TRACK_940: 24 XXX
 SG_ BYTE0 : 0|8@1+ (1,0) [0|255] "" XXX
 SG_ BYTE1 : 8|8@1+ (1,0) [0|255] "" XXX
 SG_ BYTE2 : 16|8@1+ (1,0) [0|255] "" XXX
 SG_ BYTE3 : 24|8@1+ (1,0) [0|255] "" XXX
 SG_ BYTE4 : 32|8@1+ (1,0) [0|255] "" XXX
 SG_ BYTE5 : 40|8@1+ (1,0) [0|255] "" XXX
 SG_ BYTE6 : 48|8@1+ (1,0) [0|255] "" XXX
 SG_ BYTE7 : 56|8@1+ (1,0) [0|255] "" XXX
 SG_ BYTE8 : 64|8@1+ (1,0) [0|255] "" XXX
 SG_ BYTE9 : 72|8@1+ (1,0) [0|255] "" XXX
 SG_ BYTE10 : 80|8@1+ (1,0) [0|255] "" XXX
 SG_ BYTE11 : 88|8@1+ (1,0) [0|255] "" XXX
 SG_ BYTE12 : 96|8@1+ (1,0) [0|255] "" XXX
 SG_ BYTE13 : 104|8@1+ (1,0) [0|255] "" XXX
 SG_ BYTE14 : 112|8@1+ (1,0) [0|255] "" XXX
 SG_ BYTE15 : 120|8@1+ (1,0) [0|255] "" XXX
 SG_ BYTE16 : 128|8@1+ (1,0) [0|255] "" XXX
 SG_ BYTE17 : 136|8@1+ (1,0) [0|255] "" XXX
 SG_ BYTE18 : 144|8@1+ (1,0) [0|255] "" XXX
 SG_ BYTE19 : 152|8@1+ (1,0) [0|255] "" XXX
 SG_ BYTE20 : 160|8@1+ (1,0) [0|255] "" XXX
 SG_ BYTE21 : 168|8@1+ (1,0) [0|255] "" XXX
 SG_ BYTE22 : 176|8@1+ (1,0) [0|255] "" XXX
 SG_ BYTE23 : 184|8@1+ (1,0) [0|255] "" XXX

BO_ 941 RADAR_TRACK_941: 24 XXX
 SG_ BYTE0 : 0|8@1+ (1,0) [0|255] "" XXX
 SG_ BYTE1 : 8|8@1+ (1,0) [0|255] "" XXX
 SG_ BYTE2 : 16|8@1+ (1,0) [0|255] "" XXX
 SG_ BYTE3 : 24|8@1+ (1,0) [0|255] "" XXX
 SG_ BYTE4 : 32|8@1+ (1,0) [0|255] "" XXX
 SG_ BYTE5 : 40|8@1+ (1,0) [0|255] "" XXX
 SG_ BYTE6 : 48|8@1+ (1,0) [0|255] "" XXX
 SG_ BYTE7 : 56|8@1+ (1,0) [0|255] "" XXX
 SG_ BYTE8 : 64|8@1+ (1,0) [0|255] "" XXX
 SG_ BYTE9 : 72|8@1+ (1,0) [0|255] "" XXX
 SG_ BYTE10 : 80|8@1+ (1,0) [0|255] "" XXX
 SG_ BYTE11 : 88|8@1+ (1,0) [0|255] "" XXX
 SG_ BYTE12 : 96|8@1+ (1,0) [0|255] "" XXX
 SG_ BYTE13 : 104|8@1+ (1,0) [0|255] "" XXX
 SG_ BYTE14 : 112|8@1+ (1,0) [0|255] "" XXX
 SG_ BYTE15 : 120|8@1+ (1,0) [0|255] "" XXX
 SG_ BYTE16 : 128|8@1+ (1,0) [0|255] "" XXX
 SG_ BYTE17 : 136|8@1+ (1,0) [0|255] "" XXX
 SG_ BYTE18 : 144|8@1+ (1,0) [0|255] "" XXX
 SG_ BYTE19 : 152|8@1+ (1,0) [0|255] "" XXX
 SG_ BYTE20 : 160|8@1+ (1,0) [0|255] "" XXX
 SG_ BYTE21 : 168|8@1+ (1,0) [0|255] "" XXX
 SG_ BYTE22 : 176|8@1+ (1,0) [0|255] "" XXX
 SG_ BYTE23 : 184|8@1+ (1,0) [0|255] "" XXX

BO_ 942 RADAR_TRACK_942: 24 XXX
 SG_ BYTE0 : 0|8@1+ (1,0) [0|255] "" XXX
 SG_ BYTE1 : 8|8@1+ (1,0) [0|255] "" XXX
 SG_ BYTE2 : 16|8@1+ (1,0) [0|255] "" XXX
 SG_ BYTE3 : 24|8@1+ (1,0) [0|255] "" XXX
 SG_ BYTE4 : 32|8@1+ (1,0) [0|255] "" XXX
 SG_ BYTE5 : 40|8@1+ (1,0) [0|255] "" XXX
 SG_ BYTE6 : 48|8@1+ (1,0) [0|255] "" XXX
 SG_ BYTE7 : 56|8@1+ (1,0) [0|255] "" XXX
 SG_ BYTE8 : 64|8@1+ (1,0) [0|255] "" XXX
 SG_ BYTE9 : 72|8@1+ (1,0) [0|255] "" XXX
 SG_ BYTE10 : 80|8@1+ (1,0) [0|255] "" XXX
 SG_ BYTE11 : 88|8@1+ (1,0) [0|255] "" XXX
 SG_ BYTE12 : 96|8@1+ (1,0) [0|255] "" XXX
 SG_ BYTE13 : 104|8@1+ (1,0) [0|255] "" XXX
 SG_ BYTE14 : 112|8@1+ (1,0) [0|255] "" XXX
 SG_ BYTE15 : 120|8@1+ (1,0) [0|255] "" XXX
 SG_ BYTE16 : 128|8@1+ (1,0) [0|255] "" XXX
 SG_ BYTE17 : 136|8@1+ (1,0) [0|255] "" XXX
 SG_ BYTE18 : 144|8@1+ (1,0) [0|255] "" XXX
 SG_ BYTE19 : 152|8@1+ (1,0) [0|255] "" XXX
 SG_ BYTE20 : 160|8@1+ (1,0) [0|255] "" XXX
 SG_ BYTE21 : 168|8@1+ (1,0) [0|255] "" XXX
 SG_ BYTE22 : 176|8@1+ (1,0) [0|255] "" XXX
 SG_ BYTE23 : 184|8@1+ (1,0) [0|255] "" XXX

BO_ 943 RADAR_TRACK_943: 24 XXX
 SG_ BYTE0 : 0|8@1+ (1,0) [0|255] "" XXX
 SG_ BYTE1 : 8|8@1+ (1,0) [0|255] "" XXX
 SG_ BYTE2 : 16|8@1+ (1,0) [0|255] "" XXX
 SG_ BYTE3 : 24|8@1+ (1,0) [0|255] "" XXX
 SG_ BYTE4 : 32|8@1+ (1,0) [0|255] "" XXX
 SG_ BYTE5 : 40|8@1+ (1,0) [0|255] "" XXX
 SG_ BYTE6 : 48|8@1+ (1,0) [0|255] "" XXX
 SG_ BYTE7 : 56|8@1+ (1,0) [0|255] "" XXX
 SG_ BYTE8 : 64|8@1+ (1,0) [0|255] "" XXX
 SG_ BYTE9 : 72|8@1+ (1,0) [0|255] "" XXX
 SG_ BYTE10 : 80|8@1+ (1,0) [0|255] "" XXX
 SG_ BYTE11 : 88|8@1+ (1,0) [0|255] "" XXX
 SG_ BYTE12 : 96|8@1+ (1,0) [0|255] "" XXX
 SG_ BYTE13 : 104|8@1+ (1,0) [0|255] "" XXX
 SG_ BYTE14 : 112|8@1+ (1,0) [0|255] "" XXX
 SG_ BYTE15 : 120|8@1+ (1,0) [0|255] "" XXX
 SG_ BYTE16 : 128|8@1+ (1,0) [0|255] "" XXX
 SG_ BYTE17 : 136|8@1+ (1,0) [0|255] "" XXX
 SG_ BYTE18 : 144|8@1+ (1,0) [0|255] "" XXX
 SG_ BYTE19 : 152|8@1+ (1,0) [0|255] "" XXX
 SG_ BYTE20 : 160|8@1+ (1,0) [0|255] "" XXX
 SG_ BYTE21 : 168|8@1+ (1,0) [0|255] "" XXX
 SG_ BYTE22 : 176|8@1+ (1,0) [0|255] "" XXX
 SG_ BYTE23 : 184|8@1+ (1,0) [0|255] "" XXX

BO_ 944 RADAR_TRACK_944: 24 XXX
 SG_ BYTE0 : 0|8@1+ (1,0) [0|255] "" XXX
 SG_ BYTE1 : 8|8@1+ (1,0) [0|255] "" XXX
 SG_ BYTE2 : 16|8@1+ (1,0) [0|255] "" XXX
 SG_ BYTE3 : 24|8@1+ (1,0) [0|255] "" XXX
 SG_ BYTE4 : 32|8@1+ (1,0) [0|255] "" XXX
 SG_ BYTE5 : 40|8@1+ (1,0) [0|255] "" XXX
 SG_ BYTE6 : 48|8@1+ (1,0) [0|255] "" XXX
 SG_ BYTE7 : 56|8@1+ (1,0) [0|255] "" XXX
 SG_ BYTE8 : 64|8@1+ (1,0) [0|255] "" XXX
 SG_ BYTE9 : 72|8@1+ (1,0) [0|255] "" XXX
 SG_ BYTE10 : 80|8@1+ (1,0) [0|255] "" XXX
 SG_ BYTE11 : 88|8@1+ (1,0) [0|255] "" XXX
 SG_ BYTE12 : 96|8@1+ (1,0) [0|255] "" XXX
 SG_ BYTE13 : 104|8@1+ (1,0) [0|255] "" XXX
 SG_ BYTE14 : 112|8@1+ (1,0) [0|255] "" XXX
 SG_ BYTE15 : 120|8@1+ (1,0) [0|255] "" XXX
 SG_ BYTE16 : 128|8@1+ (1,0) [0|255] "" XXX
 SG_ BYTE17 : 136|8@1+ (1,0) [0|255] "" XXX
 SG_ BYTE18 : 144|8@1+ (1,0) [0|255] "" XXX
 SG_ BYTE19 : 152|8@1+ (1,0) [0|255] "" XXX
 SG_ BYTE20 : 160|8@1+ (1,0) [0|255] "" XXX
 SG_ BYTE21 : 168|8@1+ (1,0) [0|255] "" XXX
 SG_ BYTE22 : 176|8@1+ (1,0) [0|255] "" XXX
 SG_ BYTE23 : 184|8@1+ (1,0) [0|255] "" XXX

BO_ 945 RADAR_TRACK_945: 24 XXX
 SG_ BYTE0 : 0|8@1+ (1,0) [0|255] "" XXX
 SG_ BYTE1 : 8|8@1+ (1,0) [0|255] "" XXX
 SG_ BYTE2 : 16|8@1+ (1,0) [0|255] "" XXX
 SG_ BYTE3 : 24|8@1+ (1,0) [0|255] "" XXX
 SG_ BYTE4 : 32|8@1+ (1,0) [0|255] "" XXX
 SG_ BYTE5 : 40|8@1+ (1,0) [0|255] "" XXX
 SG_ BYTE6 : 48|8@1+ (1,0) [0|255] "" XXX
 SG_ BYTE7 : 56|8@1+ (1,0) [0|255] "" XXX
 SG_ BYTE8 : 64|8@1+ (1,0) [0|255] "" XXX
 SG_ BYTE9 : 72|8@1+ (1,0) [0|255] "" XXX
 SG_ BYTE10 : 80|8@1+ (1,0) [0|255] "" XXX
 SG_ BYTE11 : 88|8@1+ (1,0) [0|255] "" XXX
 SG_ BYTE12 : 96|8@1+ (1,0) [0|255] "" XXX
 SG_ BYTE13 : 104|8@1+ (1,0) [0|255] "" XXX
 SG_ BYTE14 : 112|8@1+ (1,0) [0|255] "" XXX
 SG_ BYTE15 : 120|8@1+ (1,0) [0|255] "" XXX
 SG_ BYTE16 : 128|8@1+ (1,0) [0|255] "" XXX
 SG_ BYTE17 : 136|8@1+ (1,0) [0|255] "" XXX
 SG_ BYTE18 : 144|8@1+ (1,0) [0|255] "" XXX
 SG_ BYTE19 : 152|8@1+ (1,0) [0|255] "" XXX
 SG_ BYTE20 : 160|8@1+ (1,0) [0|255] "" XXX
 SG_ BYTE21 : 168|8@1+ (1,0) [0|255] "" XXX
 SG_ BYTE22 : 176|8@1+ (1,0) [0|255] "" XXX
 SG_ BYTE23 : 184|8@1+ (1,0) [0|255] "" XXX

BO_ 946 RADAR_TRACK_946: 24 XXX
 SG_ BYTE0 : 0|8@1+ (1,0) [0|255] "" XXX
 SG_ BYTE1 : 8|8@1+ (1,0) [0|255] "" XXX
 SG_ BYTE2 : 16|8@1+ (1,0) [0|255] "" XXX
 SG_ BYTE3 : 24|8@1+ (1,0) [0|255] "" XXX
 SG_ BYTE4 : 32|8@1+ (1,0) [0|255] "" XXX
 SG_ BYTE5 : 40|8@1+ (1,0) [0|255] "" XXX
 SG_ BYTE6 : 48|8@1+ (1,0) [0|255] "" XXX
 SG_ BYTE7 : 56|8@1+ (1,0) [0|255] "" XXX
 SG_ BYTE8 : 64|8@1+ (1,0) [0|255] "" XXX
 SG_ BYTE9 : 72|8@1+ (1,0) [0|255] "" XXX
 SG_ BYTE10 : 80|8@1+ (1,0) [0|255] "" XXX
 SG_ BYTE11 : 88|8@1+ (1,0) [0|255] "" XXX
 SG_ BYTE12 : 96|8@1+ (1,0) [0|255] "" XXX
 SG_ BYTE13 : 104|8@1+ (1,0) [0|255] "" XXX
 SG_ BYTE14 : 112|8@1+ (1,0) [0|255] "" XXX
 SG_ BYTE15 : 120|8@1+ (1,0) [0|255] "" XXX
 SG_ BYTE16 : 128|8@1+ (1,0) [0|255] "" XXX
 SG_ BYTE17 : 136|8@1+ (1,0) [0|255] "" XXX
 SG_ BYTE18 : 144|8@1+ (1,0) [0|255] "" XXX
 SG_ BYTE19 : 152|8@1+ (1,0) [0|255] "" XXX
 SG_ BYTE20 : 160|8@1+ (1,0) [0|255] "" XXX
 SG_ BYTE21 : 168|8@1+ (1,0) [0|255] "" XXX
 SG_ BYTE22 : 176|8@1+ (1,0) [0|255] "" XXX
 SG_ BYTE23 : 184|8@1+ (1,0) [0|255] "" XXX

BO_ 947 RADAR_TRACK_947: 24 XXX
 SG_ BYTE0 : 0|8@1+ (1,0) [0|255] "" XXX
 SG_ BYTE1 : 8|8@1+ (1,0) [0|255] "" XXX
 SG_ BYTE2 : 16|8@1+ (1,0) [0|255] "" XXX
 SG_ BYTE3 : 24|8@1+ (1,0) [0|255] "" XXX
 SG_ BYTE4 : 32|8@1+ (1,0) [0|255] "" XXX
 SG_ BYTE5 : 40|8@1+ (1,0) [0|255] "" XXX
 SG_ BYTE6 : 48|8@1+ (1,0) [0|255] "" XXX
 SG_ BYTE7 : 56|8@1+ (1,0) [0|255] "" XXX
 SG_ BYTE8 : 64|8@1+ (1,0) [0|255] "" XXX
 SG_ BYTE9 : 72|8@1+ (1,0) [0|255] "" XXX
 SG_ BYTE10 : 80|8@1+ (1,0) [0|255] "" XXX
 SG_ BYTE11 : 88|8@1+ (1,0) [0|255] "" XXX
 SG_ BYTE12 : 96|8@1+ (1,0) [0|255] "" XXX
 SG_ BYTE13 : 104|8@1+ (1,0) [0|255] "" XXX
 SG_ BYTE14 : 112|8@1+ (1,0) [0|255] "" XXX
 SG_ BYTE15 : 120|8@1+ (1,0) [0|255] "" XXX
 SG_ BYTE16 : 128|8@1+ (1,0) [0|255] "" XXX
 SG_ BYTE17 : 136|8@1+ (1,0) [0|255] "" XXX
 SG_ BYTE18 : 144|8@1+ (1,0) [0|255] "" XXX
 SG_ BYTE19 : 152|8@1+ (1,0) [0|255] "" XXX
 SG_ BYTE20 : 160|8@1+ (1,0) [0|255] "" XXX
 SG_ BYTE21 : 168|8@1+ (1,0) [0|255] "" XXX
 SG_ BYTE22 : 176|8@1+ (1,0) [0|255] "" XXX
 SG_ BYTE23 : 184|8@1+ (1,0) [0|255] "" XXX

BO_ 948 RADAR_TRACK_948: 24 XXX
 SG_ BYTE0 : 0|8@1+ (1,0) [0|255] "" XXX
 SG_ BYTE1 : 8|8@1+ (1,0) [0|255] "" XXX
 SG_ BYTE2 : 16|8@1+ (1,0) [0|255] "" XXX
 SG_ BYTE3 : 24|8@1+ (1,0) [0|255] "" XXX
 SG_ BYTE4 : 32|8@1+ (1,0) [0|255] "" XXX
 SG_ BYTE5 : 40|8@1+ (1,0) [0|255] "" XXX
 SG_ BYTE6 : 48|8@1+ (1,0) [0|255] "" XXX
 SG_ BYTE7 : 56|8@1+ (1,0) [0|255] "" XXX
 SG_ BYTE8 : 64|8@1+ (1,0) [0|255] "" XXX
 SG_ BYTE9 : 72|8@1+ (1,0) [0|255] "" XXX
 SG_ BYTE10 : 80|8@1+ (1,0) [0|255] "" XXX
 SG_ BYTE11 : 88|8@1+ (1,0) [0|255] "" XXX
 SG_ BYTE12 : 96|8@1+ (1,0) [0|255] "" XXX
 SG_ BYTE13 : 104|8@1+ (1,0) [0|255] "" XXX
 SG_ BYTE14 : 112|8@1+ (1,0) [0|255] "" XXX
 SG_ BYTE15 : 120|8@1+ (1,0) [0|255] "" XXX
 SG_ BYTE16 : 128|8@1+ (1,0) [0|255] "" XXX
 SG_ BYTE17 : 136|8@1+ (1,0) [0|255] "" XXX
 SG_ BYTE18 : 144|8@1+ (1,0) [0|255] "" XXX
 SG_ BYTE19 : 152|8@1+ (1,0) [0|255] "" XXX
 SG_ BYTE20 : 160|8@1+ (1,0) [0|255] "" XXX
 SG_ BYTE21 : 168|8@1+ (1,0) [0|255] "" XXX
 SG_ BYTE22 : 176|8@1+ (1,0) [0|255] "" XXX
 SG_ BYTE23 : 184|8@1+ (1,0) [0|255] "" XXX

BO_ 949 RADAR_TRACK_949: 24 XXX
 SG_ BYTE0 : 0|8@1+ (1,0) [0|255] "" XXX
 SG_ BYTE1 : 8|8@1+ (1,0) [0|255] "" XXX
 SG_ BYTE2 : 16|8@1+ (1,0) [0|255] "" XXX
 SG_ BYTE3 : 24|8@1+ (1,0) [0|255] "" XXX
 SG_ BYTE4 : 32|8@1+ (1,0) [0|255] "" XXX
 SG_ BYTE5 : 40|8@1+ (1,0) [0|255] "" XXX
 SG_ BYTE6 : 48|8@1+ (1,0) [0|255] "" XXX
 SG_ BYTE7 : 56|8@1+ (1,0) [0|255] "" XXX
 SG_ BYTE8 : 64|8@1+ (1,0) [0|255] "" XXX
 SG_ BYTE9 : 72|8@1+ (1,0) [0|255] "" XXX
 SG_ BYTE10 : 80|8@1+ (1,0) [0|255] "" XXX
 SG_ BYTE11 : 88|8@1+ (1,0) [0|255] "" XXX
 SG_ BYTE12 : 96|8@1+ (1,0) [0|255] "" XXX
 SG_ BYTE13 : 104|8@1+ (1,0) [0|255] "" XXX
 SG_ BYTE14 : 112|8@1+ (1,0) [0|255] "" XXX
 SG_ BYTE15 : 120|8@1+ (1,0) [0|255] "" XXX
 SG_ BYTE16 : 128|8@1+ (1,0) [0|255] "" XXX
 SG_ BYTE17 : 136|8@1+ (1,0) [0|255] "" XXX
 SG_ BYTE18 : 144|8@1+ (1,0) [0|255] "" XXX
 SG_ BYTE19 : 152|8@1+ (1,0) [0|255] "" XXX
 SG_ BYTE20 : 160|8@1+ (1,0) [0|255] "" XXX
 SG_ BYTE21 : 168|8@1+ (1,0) [0|255] "" XXX
 SG_ BYTE22 : 176|8@1+ (1,0) [0|255] "" XXX
 SG_ BYTE23 : 184|8@1+ (1,0) [0|255] "" XXX

BO_ 950 RADAR_TRACK_950: 24 XXX
 SG_ BYTE0 : 0|8@1+ (1,0) [0|255] "" XXX
 SG_ BYTE1 : 8|8@1+ (1,0) [0|255] "" XXX
 SG_ BYTE2 : 16|8@1+ (1,0) [0|255] "" XXX
 SG_ BYTE3 : 24|8@1+ (1,0) [0|255] "" XXX
 SG_ BYTE4 : 32|8@1+ (1,0) [0|255] "" XXX
 SG_ BYTE5 : 40|8@1+ (1,0) [0|255] "" XXX
 SG_ BYTE6 : 48|8@1+ (1,0) [0|255] "" XXX
 SG_ BYTE7 : 56|8@1+ (1,0) [0|255] "" XXX
 SG_ BYTE8 : 64|8@1+ (1,0) [0|255] "" XXX
 SG_ BYTE9 : 72|8@1+ (1,0) [0|255] "" XXX
 SG_ BYTE10 : 80|8@1+ (1,0) [0|255] "" XXX
 SG_ BYTE11 : 88|8@1+ (1,0) [0|255] "" XXX
 SG_ BYTE12 : 96|8@1+ (1,0) [0|255] "" XXX
 SG_ BYTE13 : 104|8@1+ (1,0) [0|255] "" XXX
 SG_ BYTE14 : 112|8@1+ (1,0) [0|255] "" XXX
 SG_ BYTE15 : 120|8@1+ (1,0) [0|255] "" XXX
 SG_ BYTE16 : 128|8@1+ (1,0) [0|255] "" XXX
 SG_ BYTE17 : 136|8@1+ (1,0) [0|255] "" XXX
 SG_ BYTE18 : 144|8@1+ (1,0) [0|255] "" XXX
 SG_ BYTE19 : 152|8@1+ (1,0) [0|255] "" XXX
 SG_ BYTE20 : 160|8@1+ (1,0) [0|255] "" XXX
 SG_ BYTE21 : 168|8@1+ (1,0) [0|255] "" XXX
 SG_ BYTE22 : 176|8@1+ (1,0) [0|255] "" XXX
 SG_ BYTE23 : 184|8@1+ (1,0) [0|255] "" XXX

BO_ 951 RADAR_TRACK_951: 24 XXX
 SG_ BYTE0 : 0|8@1+ (1,0) [0|255] "" XXX
 SG_ BYTE1 : 8|8@1+ (1,0) [0|255] "" XXX
 SG_ BYTE2 : 16|8@1+ (1,0) [0|255] "" XXX
 SG_ BYTE3 : 24|8@1+ (1,0) [0|255] "" XXX
 SG_ BYTE4 : 32|8@1+ (1,0) [0|255] "" XXX
 SG_ BYTE5 : 40|8@1+ (1,0) [0|255] "" XXX
 SG_ BYTE6 : 48|8@1+ (1,0) [0|255] "" XXX
 SG_ BYTE7 : 56|8@1+ (1,0) [0|255] "" XXX
 SG_ BYTE8 : 64|8@1+ (1,0) [0|255] "" XXX
 SG_ BYTE9 : 72|8@1+ (1,0) [0|255] "" XXX
 SG_ BYTE10 : 80|8@1+ (1,0) [0|255] "" XXX
 SG_ BYTE11 : 88|8@1+ (1,0) [0|255] "" XXX
 SG_ BYTE12 : 96|8@1+ (1,0) [0|255] "" XXX
 SG_ BYTE13 : 104|8@1+ (1,0) [0|255] "" XXX
 SG_ BYTE14 : 112|8@1+ (1,0) [0|255] "" XXX
 SG_ BYTE15 : 120|8@1+ (1,0) [0|255] "" XXX
 SG_ BYTE16 : 128|8@1+ (1,0) [0|255] "" XXX
 SG_ BYTE17 : 136|8@1+ (1,0) [0|255] "" XXX
 SG_ BYTE18 : 144|8@1+ (1,0) [0|255] "" XXX
 SG_ BYTE19 : 152|8@1+ (1,0) [0|255] "" XXX
 SG_ BYTE20 : 160|8@1+ (1,0) [0|255] "" XXX
 SG_ BYTE21 : 168|8@1+ (1,0) [0|255] "" XXX
 SG_ BYTE22 : 176|8@1+ (1,0) [0|255] "" XXX
 SG_ BYTE23 : 184|8@1+ (1,0) [0|255] "" XXX

BO_ 952 RADAR_TRACK_952: 24 XXX
 SG_ BYTE0 : 0|8@1+ (1,0) [0|255] "" XXX
 SG_ BYTE1 : 8|8@1+ (1,0) [0|255] "" XXX
 SG_ BYTE2 : 16|8@1+ (1,0) [0|255] "" XXX
 SG_ BYTE3 : 24|8@1+ (1,0) [0|255] "" XXX
 SG_ BYTE4 : 32|8@1+ (1,0) [0|255] "" XXX
 SG_ BYTE5 : 40|8@1+ (1,0) [0|255] "" XXX
 SG_ BYTE6 : 48|8@1+ (1,0) [0|255] "" XXX
 SG_ BYTE7 : 56|8@1+ (1,0) [0|255] "" XXX
 SG_ BYTE8 : 64|8@1+ (1,0) [0|255] "" XXX
 SG_ BYTE9 : 72|8@1+ (1,0) [0|255] "" XXX
 SG_ BYTE10 : 80|8@1+ (1,0) [0|255] "" XXX
 SG_ BYTE11 : 88|8@1+ (1,0) [0|255] "" XXX
 SG_ BYTE12 : 96|8@1+ (1,0) [0|255] "" XXX
 SG_ BYTE13 : 104|8@1+ (1,0) [0|255] "" XXX
 SG_ BYTE14 : 112|8@1+ (1,0) [0|255] "" XXX
 SG_ BYTE15 : 120|8@1+ (1,0) [0|255] "" XXX
 SG_ BYTE16 : 128|8@1+ (1,0) [0|255] "" XXX
 SG_ BYTE17 : 136|8@1+ (1,0) [0|255] "" XXX
 SG_ BYTE18 : 144|8@1+ (1,0) [0|255] "" XXX
 SG_ BYTE19 : 152|8@1+ (1,0) [0|255] "" XXX
 SG_ BYTE20 : 160|8@1+ (1,0) [0|255] "" XXX
 SG_ BYTE21 : 168|8@1+ (1,0) [0|255] "" XXX
 SG_ BYTE22 : 176|8@1+ (1,0) [0|255] "" XXX
 SG_ BYTE23 : 184|8@1+ (1,0) [0|255] "" XXX

BO_ 953 RADAR_TRACK_953: 24 XXX
 SG_ BYTE0 : 0|8@1+ (1,0) [0|255] "" XXX
 SG_ BYTE1 : 8|8@1+ (1,0) [0|255] "" XXX
 SG_ BYTE2 : 16|8@1+ (1,0) [0|255] "" XXX
 SG_ BYTE3 : 24|8@1+ (1,0) [0|255] "" XXX
 SG_ BYTE4 : 32|8@1+ (1,0) [0|255] "" XXX
 SG_ BYTE5 : 40|8@1+ (1,0) [0|255] "" XXX
 SG_ BYTE6 : 48|8@1+ (1,0) [0|255] "" XXX
 SG_ BYTE7 : 56|8@1+ (1,0) [0|255] "" XXX
 SG_ BYTE8 : 64|8@1+ (1,0) [0|255] "" XXX
 SG_ BYTE9 : 72|8@1+ (1,0) [0|255] "" XXX
 SG_ BYTE10 : 80|8@1+ (1,0) [0|255] "" XXX
 SG_ BYTE11 : 88|8@1+ (1,0) [0|255] "" XXX
 SG_ BYTE12 : 96|8@1+ (1,0) [0|255] "" XXX
 SG_ BYTE13 : 104|8@1+ (1,0) [0|255] "" XXX
 SG_ BYTE14 : 112|8@1+ (1,0) [0|255] "" XXX
 SG_ BYTE15 : 120|8@1+ (1,0) [0|255] "" XXX
 SG_ BYTE16 : 128|8@1+ (1,0) [0|255] "" XXX
 SG_ BYTE17 : 136|8@1+ (1,0) [0|255] "" XXX
 SG_ BYTE18 : 144|8@1+ (1,0) [0|255] "" XXX
 SG_ BYTE19 : 152|8@1+ (1,0) [0|255] "" XXX
 SG_ BYTE20 : 160|8@1+ (1,0) [0|255] "" XXX
 SG_ BYTE21 : 168|8@1+ (1,0) [0|255] "" XXX
 SG_ BYTE22 : 176|8@1+ (1,0) [0|255] "" XXX
 SG_ BYTE23 : 184|8@1+ (1,0) [0|255] "" XXX

BO_ 954 RADAR_TRACK_954: 24 XXX
 SG_ BYTE0 : 0|8@1+ (1,0) [0|255] "" XXX
 SG_ BYTE1 : 8|8@1+ (1,0) [0|255] "" XXX
 SG_ BYTE2 : 16|8@1+ (1,0) [0|255] "" XXX
 SG_ BYTE3 : 24|8@1+ (1,0) [0|255] "" XXX
 SG_ BYTE4 : 32|8@1+ (1,0) [0|255] "" XXX
 SG_ BYTE5 : 40|8@1+ (1,0) [0|255] "" XXX
 SG_ BYTE6 : 48|8@1+ (1,0) [0|255] "" XXX
 SG_ BYTE7 : 56|8@1+ (1,0) [0|255] "" XXX
 SG_ BYTE8 : 64|8@1+ (1,0) [0|255] "" XXX
 SG_ BYTE9 : 72|8@1+ (1,0) [0|255] "" XXX
 SG_ BYTE10 : 80|8@1+ (1,0) [0|255] "" XXX
 SG_ BYTE11 : 88|8@1+ (1,0) [0|255] "" XXX
 SG_ BYTE12 : 96|8@1+ (1,0) [0|255] "" XXX
 SG_ BYTE13 : 104|8@1+ (1,0) [0|255] "" XXX
 SG_ BYTE14 : 112|8@1+ (1,0) [0|255] "" XXX
 SG_ BYTE15 : 120|8@1+ (1,0) [0|255] "" XXX
 SG_ BYTE16 : 128|8@1+ (1,0) [0|255] "" XXX
 SG_ BYTE17 : 136|8@1+ (1,0) [0|255] "" XXX
 SG_ BYTE18 : 144|8@1+ (1,0) [0|255] "" XXX
 SG_ BYTE19 : 152|8@1+ (1,0) [0|255] "" XXX
 SG_ BYTE20 : 160|8@1+ (1,0) [0|255] "" XXX
 SG_ BYTE21 : 168|8@1+ (1,0) [0|255] "" XXX
 SG_ BYTE22 : 176|8@1+ (1,0) [0|255] "" XXX
 SG_ BYTE23 : 184|8@1+ (1,0) [0|255] "" XXX

BO_ 955 RADAR_TRACK_955: 24 XXX
 SG_ BYTE0 : 0|8@1+ (1,0) [0|255] "" XXX
 SG_ BYTE1 : 8|8@1+ (1,0) [0|255] "" XXX
 SG_ BYTE2 : 16|8@1+ (1,0) [0|255] "" XXX
 SG_ BYTE3 : 24|8@1+ (1,0) [0|255] "" XXX
 SG_ BYTE4 : 32|8@1+ (1,0) [0|255] "" XXX
 SG_ BYTE5 : 40|8@1+ (1,0) [0|255] "" XXX
 SG_ BYTE6 : 48|8@1+ (1,0) [0|255] "" XXX
 SG_ BYTE7 : 56|8@1+ (1,0) [0|255] "" XXX
 SG_ BYTE8 : 64|8@1+ (1,0) [0|255] "" XXX
 SG_ BYTE9 : 72|8@1+ (1,0) [0|255] "" XXX
 SG_ BYTE10 : 80|8@1+ (1,0) [0|255] "" XXX
 SG_ BYTE11 : 88|8@1+ (1,0) [0|255] "" XXX
 SG_ BYTE12 : 96|8@1+ (1,0) [0|255] "" XXX
 SG_ BYTE13 : 104|8@1+ (1,0) [0|255] "" XXX
 SG_ BYTE14 : 112|8@1+ (1,0) [0|255] "" XXX
 SG_ BYTE15 : 120|8@1+ (1,0) [0|255] "" XXX
 SG_ BYTE16 : 128|8@1+ (1,0) [0|255] "" XXX
 SG_ BYTE17 : 136|8@1+ (1,0) [0|255] "" XXX
 SG_ BYTE18 : 144|8@1+ (1,0) [0|255] "" XXX
 SG_ BYTE19 : 152|8@1+ (1,0) [0|255] "" XXX
 SG_ BYTE20 : 160|8@1+ (1,0) [0|255] "" XXX
 SG_ BYTE21 : 168|8@1+ (1,0) [0|255] "" XXX
 SG_ BYTE22 : 176|8@1+ (1,0) [0|255] "" XXX
 SG_ BYTE23 : 184|8@1+ (1,0) [0|255] "" XXX

BO_ 956 RADAR_TRACK_956: 24 XXX
 SG_ BYTE0 : 0|8@1+ (1,0) [0|255] "" XXX
 SG_ BYTE1 : 8|8@1+ (1,0) [0|255] "" XXX
 SG_ BYTE2 : 16|8@1+ (1,0) [0|255] "" XXX
 SG_ BYTE3 : 24|8@1+ (1,0) [0|255] "" XXX
 SG_ BYTE4 : 32|8@1+ (1,0) [0|255] "" XXX
 SG_ BYTE5 : 40|8@1+ (1,0) [0|255] "" XXX
 SG_ BYTE6 : 48|8@1+ (1,0) [0|255] "" XXX
 SG_ BYTE7 : 56|8@1+ (1,0) [0|255] "" XXX
 SG_ BYTE8 : 64|8@1+ (1,0) [0|255] "" XXX
 SG_ BYTE9 : 72|8@1+ (1,0) [0|255] "" XXX
 SG_ BYTE10 : 80|8@1+ (1,0) [0|255] "" XXX
 SG_ BYTE11 : 88|8@1+ (1,0) [0|255] "" XXX
 SG_ BYTE12 : 96|8@1+ (1,0) [0|255] "" XXX
 SG_ BYTE13 : 104|8@1+ (1,0) [0|255] "" XXX
 SG_ BYTE14 : 112|8@1+ (1,0) [0|255] "" XXX
 SG_ BYTE15 : 120|8@1+ (1,0) [0|255] "" XXX
 SG_ BYTE16 : 128|8@1+ (1,0) [0|255] "" XXX
 SG_ BYTE17 : 136|8@1+ (1,0) [0|255] "" XXX
 SG_ BYTE18 : 144|8@1+ (1,0) [0|255] "" XXX
 SG_ BYTE19 : 152|8@1+ (1,0) [0|255] "" XXX
 SG_ BYTE20 : 160|8@1+ (1,0) [0|255] "" XXX
 SG_ BYTE21 : 168|8@1+ (1,0) [0|255] "" XXX
 SG_ BYTE22 : 176|8@1+ (1,0) [0|255] "" XXX
 SG_ BYTE23 : 184|8@1+ (1,0) [0|255] "" XXX

BO_ 957 RADAR_TRACK_957: 24 XXX
 SG_ BYTE0 : 0|8@1+ (1,0) [0|255] "" XXX
 SG_ BYTE1 : 8|8@1+ (1,0) [0|255] "" XXX
 SG_ BYTE2 : 16|8@1+ (1,0) [0|255] "" XXX
 SG_ BYTE3 : 24|8@1+ (1,0) [0|255] "" XXX
 SG_ BYTE4 : 32|8@1+ (1,0) [0|255] "" XXX
 SG_ BYTE5 : 40|8@1+ (1,0) [0|255] "" XXX
 SG_ BYTE6 : 48|8@1+ (1,0) [0|255] "" XXX
 SG_ BYTE7 : 56|8@1+ (1,0) [0|255] "" XXX
 SG_ BYTE8 : 64|8@1+ (1,0) [0|255] "" XXX
 SG_ BYTE9 : 72|8@1+ (1,0) [0|255] "" XXX
 SG_ BYTE10 : 80|8@1+ (1,0) [0|255] "" XXX
 SG_ BYTE11 : 88|8@1+ (1,0) [0|255] "" XXX
 SG_ BYTE12 : 96|8@1+ (1,0) [0|255] "" XXX
 SG_ BYTE13 : 104|8@1+ (1,0) [0|255] "" XXX
 SG_ BYTE14 : 112|8@1+ (1,0) [0|255] "" XXX
 SG_ BYTE15 : 120|8@1+ (1,0) [0|255] "" XXX
 SG_ BYTE16 : 128|8@1+ (1,0) [0|255] "" XXX
 SG_ BYTE17 : 136|8@1+ (1,0) [0|255] "" XXX
 SG_ BYTE18 : 144|8@1+ (1,0) [0|255] "" XXX
 SG_ BYTE19 : 152|8@1+ (1,0) [0|255] "" XXX
 SG_ BYTE20 : 160|8@1+ (1,0) [0|255] "" XXX
 SG_ BYTE21 : 168|8@1+ (1,0) [0|255] "" XXX
 SG_ BYTE22 : 176|8@1+ (1,0) [0|255] "" XXX
 SG_ BYTE23 : 184|8@1+ (1,0) [0|255] "" XXX

BO_ 958 RADAR_TRACK_958: 24 XXX
 SG_ BYTE0 : 0|8@1+ (1,0) [0|255] "" XXX
 SG_ BYTE1 : 8|8@1+ (1,0) [0|255] "" XXX
 SG_ BYTE2 : 16|8@1+ (1,0) [0|255] "" XXX
 SG_ BYTE3 : 24|8@1+ (1,0) [0|255] "" XXX
 SG_ BYTE4 : 32|8@1+ (1,0) [0|255] "" XXX
 SG_ BYTE5 : 40|8@1+ (1,0) [0|255] "" XXX
 SG_ BYTE6 : 48|8@1+ (1,0) [0|255] "" XXX
 SG_ BYTE7 : 56|8@1+ (1,0) [0|255] "" XXX
 SG_ BYTE8 : 64|8@1+ (1,0) [0|255] "" XXX
 SG_ BYTE9 : 72|8@1+ (1,0) [0|255] "" XXX
 SG_ BYTE10 : 80|8@1+ (1,0) [0|255] "" XXX
 SG_ BYTE11 : 88|8@1+ (1,0) [0|255] "" XXX
 SG_ BYTE12 : 96|8@1+ (1,0) [0|255] "" XXX
 SG_ BYTE13 : 104|8@1+ (1,0) [0|255] "" XXX
 SG_ BYTE14 : 112|8@1+ (1,0) [0|255] "" XXX
 SG_ BYTE15 : 120|8@1+ (1,0) [0|255] "" XXX
 SG_ BYTE16 : 128|8@1+ (1,0) [0|255] "" XXX
 SG_ BYTE17 : 136|8@1+ (1,0) [0|255] "" XXX
 SG_ BYTE18 : 144|8@1+ (1,0) [0|255] "" XXX
 SG_ BYTE19 : 152|8@1+ (1,0) [0|255] "" XXX
 SG_ BYTE20 : 160|8@1+ (1,0) [0|255] "" XXX
 SG_ BYTE21 : 168|8@1+ (1,0) [0|255] "" XXX
 SG_ BYTE22 : 176|8@1+ (1,0) [0|255] "" XXX
 SG_ BYTE23 : 184|8@1+ (1,0) [0|255] "" XXX

BO_ 959 RADAR_TRACK_959: 24 XXX
 SG_ BYTE0 : 0|8@1+ (1,0) [0|255] "" XXX
 SG_ BYTE1 : 8|8@1+ (1,0) [0|255] "" XXX
 SG_ BYTE2 : 16|8@1+ (1,0) [0|255] "" XXX
 SG_ BYTE3 : 24|8@1+ (1,0) [0|255] "" XXX
 SG_ BYTE4 : 32|8@1+ (1,0) [0|255] "" XXX
 SG_ BYTE5 : 40|8@1+ (1,0) [0|255] "" XXX
 SG_ BYTE6 : 48|8@1+ (1,0) [0|255] "" XXX
 SG_ BYTE7 : 56|8@1+ (1,0) [0|255] "" XXX
 SG_ BYTE8 : 64|8@1+ (1,0) [0|255] "" XXX
 SG_ BYTE9 : 72|8@1+ (1,0) [0|255] "" XXX
 SG_ BYTE10 : 80|8@1+ (1,0) [0|255] "" XXX
 SG_ BYTE11 : 88|8@1+ (1,0) [0|255] "" XXX
 SG_ BYTE12 : 96|8@1+ (1,0) [0|255] "" XXX
 SG_ BYTE13 : 104|8@1+ (1,0) [0|255] "" XXX
 SG_ BYTE14 : 112|8@1+ (1,0) [0|255] "" XXX
 SG_ BYTE15 : 120|8@1+ (1,0) [0|255] "" XXX
 SG_ BYTE16 : 128|8@1+ (1,0) [0|255] "" XXX
 SG_ BYTE17 : 136|8@1+ (1,0) [0|255] "" XXX
 SG_ BYTE18 : 144|8@1+ (1,0) [0|255] "" XXX
 SG_ BYTE19 : 152|8@1+ (1,0) [0|255] "" XXX
 SG_ BYTE20 : 160|8@1+ (1,0) [0|255] "" XXX
 SG_ BYTE21 : 168|8@1+ (1,0) [0|255] "" XXX
 SG_ BYTE22 : 176|8@1+ (1,0) [0|255] "" XXX
 SG_ BYTE23 : 184|8@1+ (1,0) [0|255] "" XXX

BO_ 960 RADAR_TRACK_960: 24 XXX
 SG_ BYTE0 : 0|8@1+ (1,0) [0|255] "" XXX
 SG_ BYTE1 : 8|8@1+ (1,0) [0|255] "" XXX
 SG_ BYTE2 : 16|8@1+ (1,0) [0|255] "" XXX
 SG_ BYTE3 : 24|8@1+ (1,0) [0|255] "" XXX
 SG_ BYTE4 : 32|8@1+ (1,0) [0|255] "" XXX
 SG_ BYTE5 : 40|8@1+ (1,0) [0|255] "" XXX
 SG_ BYTE6 : 48|8@1+ (1,0) [0|255] "" XXX
 SG_ BYTE7 : 56|8@1+ (1,0) [0|255] "" XXX
 SG_ BYTE8 : 64|8@1+ (1,0) [0|255] "" XXX
 SG_ BYTE9 : 72|8@1+ (1,0) [0|255] "" XXX
 SG_ BYTE10 : 80|8@1+ (1,0) [0|255] "" XXX
 SG_ BYTE11 : 88|8@1+ (1,0) [0|255] "" XXX
 SG_ BYTE12 : 96|8@1+ (1,0) [0|255] "" XXX
 SG_ BYTE13 : 104|8@1+ (1,0) [0|255] "" XXX
 SG_ BYTE14 : 112|8@1+ (1,0) [0|255] "" XXX
 SG_ BYTE15 : 120|8@1+ (1,0) [0|255] "" XXX
 SG_ BYTE16 : 128|8@1+ (1,0) [0|255] "" XXX
 SG_ BYTE17 : 136|8@1+ (1,0) [0|255] "" XXX
 SG_ BYTE18 : 144|8@1+ (1,0) [0|255] "" XXX
 SG_ BYTE19 : 152|8@1+ (1,0) [0|255] "" XXX
 SG_ BYTE20 : 160|8@1+ (1,0) [0|255] "" XXX
 SG_ BYTE21 : 168|8@1+ (1,0) [0|255] "" XXX
 SG_ BYTE22 : 176|8@1+ (1,0) [0|255] "" XXX
 SG_ BYTE23 : 184|8@1+ (1,0) [0|255] "" XXX

BO_ 961 RADAR_TRACK_961: 24 XXX
 SG_ BYTE0 : 0|8@1+ (1,0) [0|255] "" XXX
 SG_ BYTE1 : 8|8@1+ (1,0) [0|255] "" XXX
 SG_ BYTE2 : 16|8@1+ (1,0) [0|255] "" XXX
 SG_ BYTE3 : 24|8@1+ (1,0) [0|255] "" XXX
 SG_ BYTE4 : 32|8@1+ (1,0) [0|255] "" XXX
 SG_ BYTE5 : 40|8@1+ (1,0) [0|255] "" XXX
 SG_ BYTE6 : 48|8@1+ (1,0) [0|255] "" XXX
 SG_ BYTE7 : 56|8@1+ (1,0) [0|255] "" XXX
 SG_ BYTE8 : 64|8@1+ (1,0) [0|255] "" XXX
 SG_ BYTE9 : 72|8@1+ (1,0) [0|255] "" XXX
 SG_ BYTE10 : 80|8@1+ (1,0) [0|255] "" XXX
 SG_ BYTE11 : 88|8@1+ (1,0) [0|255] "" XXX
 SG_ BYTE12 : 96|8@1+ (1,0) [0|255] "" XXX
 SG_ BYTE13 : 104|8@1+ (1,0) [0|255] "" XXX
 SG_ BYTE14 : 112|8@1+ (1,0) [0|255] "" XXX
 SG_ BYTE15 : 120|8@1+ (1,0) [0|255] "" XXX
 SG_ BYTE16 : 128|8@1+ (1,0) [0|255] "" XXX
 SG_ BYTE17 : 136|8@1+ (1,0) [0|255] "" XXX
 SG_ BYTE18 : 144|8@1+ (1,0) [0|255] "" XXX
 SG_ BYTE19 : 152|8@1+ (1,0) [0|255] "" XXX
 SG_ BYTE20 : 160|8@1+ (1,0) [0|255] "" XXX
 SG_ BYTE21 : 168|8@1+ (1,0) [0|255] "" XXX
 SG_ BYTE22 : 176|8@1+ (1,0) [0|255] "" XXX
 SG_ BYTE23 : 184|8@1+ (1,0) [0|255] "" XXX

BO_ 962 RADAR_TRACK_962: 24 XXX
 SG_ BYTE0 : 0|8@1+ (1,0) [0|255] "" XXX
 SG_ BYTE1 : 8|8@1+ (1,0) [0|255] "" XXX
 SG_ BYTE2 : 16|8@1+ (1,0) [0|255] "" XXX
 SG_ BYTE3 : 24|8@1+ (1,0) [0|255] "" XXX
 SG_ BYTE4 : 32|8@1+ (1,0) [0|255] "" XXX
 SG_ BYTE5 : 40|8@1+ (1,0) [0|255] "" XXX
 SG_ BYTE6 : 48|8@1+ (1,0) [0|255] "" XXX
 SG_ BYTE7 : 56|8@1+ (1,0) [0|255] "" XXX
 SG_ BYTE8 : 64|8@1+ (1,0) [0|255] "" XXX
 SG_ BYTE9 : 72|8@1+ (1,0) [0|255] "" XXX
 SG_ BYTE10 : 80|8@1+ (1,0) [0|255] "" XXX
 SG_ BYTE11 : 88|8@1+ (1,0) [0|255] "" XXX
 SG_ BYTE12 : 96|8@1+ (1,0) [0|255] "" XXX
 SG_ BYTE13 : 104|8@1+ (1,0) [0|255] "" XXX
 SG_ BYTE14 : 112|8@1+ (1,0) [0|255] "" XXX
 SG_ BYTE15 : 120|8@1+ (1,0) [0|255] "" XXX
 SG_ BYTE16 : 128|8@1+ (1,0) [0|255] "" XXX
 SG_ BYTE17 : 136|8@1+ (1,0) [0|255] "" XXX
 SG_ BYTE18 : 144|8@1+ (1,0) [0|255] "" XXX
 SG_ BYTE19 : 152|8@1+ (1,0) [0|255] "" XXX
 SG_ BYTE20 : 160|8@1+ (1,0) [0|255] "" XXX
 SG_ BYTE21 : 168|8@1+ (1,0) [0|255] "" XXX
 SG_ BYTE22 : 176|8@1+ (1,0) [0|255] "" XXX
 SG_ BYTE23 : 184|8@1+ (1,0) [0|255] "" XXX

BO_ 963 RADAR_TRACK_963: 24 XXX
 SG_ BYTE0 : 0|8@1+ (1,0) [0|255] "" XXX
 SG_ BYTE1 : 8|8@1+ (1,0) [0|255] "" XXX
 SG_ BYTE2 : 16|8@1+ (1,0) [0|255] "" XXX
 SG_ BYTE3 : 24|8@1+ (1,0) [0|255] "" XXX
 SG_ BYTE4 : 32|8@1+ (1,0) [0|255] "" XXX
 SG_ BYTE5 : 40|8@1+ (1,0) [0|255] "" XXX
 SG_ BYTE6 : 48|8@1+ (1,0) [0|255] "" XXX
 SG_ BYTE7 : 56|8@1+ (1,0) [0|255] "" XXX
 SG_ BYTE8 : 64|8@1+ (1,0) [0|255] "" XXX
 SG_ BYTE9 : 72|8@1+ (1,0) [0|255] "" XXX
 SG_ BYTE10 : 80|8@1+ (1,0) [0|255] "" XXX
 SG_ BYTE11 : 88|8@1+ (1,0) [0|255] "" XXX
 SG_ BYTE12 : 96|8@1+ (1,0) [0|255] "" XXX
 SG_ BYTE13 : 104|8@1+ (1,0) [0|255] "" XXX
 SG_ BYTE14 : 112|8@1+ (1,0) [0|255] "" XXX
 SG_ BYTE15 : 120|8@1+ (1,0) [0|255] "" XXX
 SG_ BYTE16 : 128|8@1+ (1,0) [0|255] "" XXX
 SG_ BYTE17 : 136|8@1+ (1,0) [0|255] "" XXX
 SG_ BYTE18 : 144|8@1+ (1,0) [0|255] "" XXX
 SG_ BYTE19 : 152|8@1+ (1,0) [0|255] "" XXX
 SG_ BYTE20 : 160|8@1+ (1,0) [0|255] "" XXX
 SG_ BYTE21 : 168|8@1+ (1,0) [0|255] "" XXX
 SG_ BYTE22 : 176|8@1+ (1,0) [0|255] "" XXX
 SG_ BYTE23 : 184|8@1+ (1,0) [0|255] "" XXX

BO_ 964 RADAR_TRACK_964: 24 XXX
 SG_ BYTE0 : 0|8@1+ (1,0) [0|255] "" XXX
 SG_ BYTE1 : 8|8@1+ (1,0) [0|255] "" XXX
 SG_ BYTE2 : 16|8@1+ (1,0) [0|255] "" XXX
 SG_ BYTE3 : 24|8@1+ (1,0) [0|255] "" XXX
 SG_ BYTE4 : 32|8@1+ (1,0) [0|255] "" XXX
 SG_ BYTE5 : 40|8@1+ (1,0) [0|255] "" XXX
 SG_ BYTE6 : 48|8@1+ (1,0) [0|255] "" XXX
 SG_ BYTE7 : 56|8@1+ (1,0) [0|255] "" XXX
 SG_ BYTE8 : 64|8@1+ (1,0) [0|255] "" XXX
 SG_ BYTE9 : 72|8@1+ (1,0) [0|255] "" XXX
 SG_ BYTE10 : 80|8@1+ (1,0) [0|255] "" XXX
 SG_ BYTE11 : 88|8@1+ (1,0) [0|255] "" XXX
 SG_ BYTE12 : 96|8@1+ (1,0) [0|255] "" XXX
 SG_ BYTE13 : 104|8@1+ (1,0) [0|255] "" XXX
 SG_ BYTE14 : 112|8@1+ (1,0) [0|255] "" XXX
 SG_ BYTE15 : 120|8@1+ (1,0) [0|255] "" XXX
 SG_ BYTE16 : 128|8@1+ (1,0) [0|255] "" XXX
 SG_ BYTE17 : 136|8@1+ (1,0) [0|255] "" XXX
 SG_ BYTE18 : 144|8@1+ (1,0) [0|255] "" XXX
 SG_ BYTE19 : 152|8@1+ (1,0) [0|255] "" XXX
 SG_ BYTE20 : 160|8@1+ (1,0) [0|255] "" XXX
 SG_ BYTE21 : 168|8@1+ (1,0) [0|255] "" XXX
 SG_ BYTE22 : 176|8@1+ (1,0) [0|255] "" XXX
 SG_ BYTE23 : 184|8@1+ (1,0) [0|255] "" XXX

BO_ 976 EV4_BODY_1: 32 XXX
 SG_ DRIVER_SEATBELT : 0|1@1+ (1,0) [0|1] "" XXX
 SG_ SPEED_REF_1 : 8|16@1+ (0.01,0) [0|655.35] "" XXX
 SG_ BYTE3 : 24|8@1+ (1,0) [0|255] "" XXX
 SG_ BYTE4 : 32|8@1+ (1,0) [0|255] "" XXX
 SG_ BYTE5 : 40|8@1+ (1,0) [0|255] "" XXX
 SG_ BYTE6 : 48|8@1+ (1,0) [0|255] "" XXX
 SG_ BYTE7 : 56|8@1+ (1,0) [0|255] "" XXX
 SG_ BYTE8 : 64|8@1+ (1,0) [0|255] "" XXX
 SG_ BYTE9 : 72|8@1+ (1,0) [0|255] "" XXX
 SG_ BYTE10 : 80|8@1+ (1,0) [0|255] "" XXX
 SG_ BYTE11 : 88|8@1+ (1,0) [0|255] "" XXX
 SG_ BYTE12 : 96|8@1+ (1,0) [0|255] "" XXX
 SG_ BYTE13 : 104|8@1+ (1,0) [0|255] "" XXX
 SG_ BYTE14 : 112|8@1+ (1,0) [0|255] "" XXX
 SG_ BYTE15 : 120|8@1+ (1,0) [0|255] "" XXX
 SG_ BYTE16 : 128|8@1+ (1,0) [0|255] "" XXX
 SG_ BYTE17 : 136|8@1+ (1,0) [0|255] "" XXX
 SG_ BYTE18 : 144|8@1+ (1,0) [0|255] "" XXX
 SG_ BYTE19 : 152|8@1+ (1,0) [0|255] "" XXX
 SG_ BYTE20 : 160|8@1+ (1,0) [0|255] "" XXX
 SG_ BYTE21 : 168|8@1+ (1,0) [0|255] "" XXX
 SG_ BYTE22 : 176|8@1+ (1,0) [0|255] "" XXX
 SG_ BYTE23 : 184|8@1+ (1,0) [0|255] "" XXX
 SG_ BYTE24 : 192|8@1+ (1,0) [0|255] "" XXX
 SG_ BYTE25 : 200|8@1+ (1,0) [0|255] "" XXX
 SG_ BYTE26 : 208|8@1+ (1,0) [0|255] "" XXX
 SG_ BYTE27 : 216|8@1+ (1,0) [0|255] "" XXX
 SG_ BYTE28 : 224|8@1+ (1,0) [0|255] "" XXX
 SG_ BYTE29 : 232|8@1+ (1,0) [0|255] "" XXX
 SG_ BYTE30 : 240|8@1+ (1,0) [0|255] "" XXX
 SG_ BYTE31 : 248|8@1+ (1,0) [0|255] "" XXX

BO_ 977 ID977: 32 XXX
 SG_ BYTE0 : 0|8@1+ (1,0) [0|255] "" XXX
 SG_ BYTE1 : 8|8@1+ (1,0) [0|255] "" XXX
 SG_ BYTE2 : 16|8@1+ (1,0) [0|255] "" XXX
 SG_ BYTE3 : 24|8@1+ (1,0) [0|255] "" XXX
 SG_ BYTE4 : 32|8@1+ (1,0) [0|255] "" XXX
 SG_ BYTE5 : 40|8@1+ (1,0) [0|255] "" XXX
 SG_ BYTE6 : 48|8@1+ (1,0) [0|255] "" XXX
 SG_ BYTE7 : 56|8@1+ (1,0) [0|255] "" XXX
 SG_ BYTE8 : 64|8@1+ (1,0) [0|255] "" XXX
 SG_ BYTE9 : 72|8@1+ (1,0) [0|255] "" XXX
 SG_ BYTE10 : 80|8@1+ (1,0) [0|255] "" XXX
 SG_ BYTE11 : 88|8@1+ (1,0) [0|255] "" XXX
 SG_ BYTE12 : 96|8@1+ (1,0) [0|255] "" XXX
 SG_ BYTE13 : 104|8@1+ (1,0) [0|255] "" XXX
 SG_ BYTE14 : 112|8@1+ (1,0) [0|255] "" XXX
 SG_ BYTE15 : 120|8@1+ (1,0) [0|255] "" XXX
 SG_ BYTE16 : 128|8@1+ (1,0) [0|255] "" XXX
 SG_ BYTE17 : 136|8@1+ (1,0) [0|255] "" XXX
 SG_ BYTE18 : 144|8@1+ (1,0) [0|255] "" XXX
 SG_ BYTE19 : 152|8@1+ (1,0) [0|255] "" XXX
 SG_ BYTE20 : 160|8@1+ (1,0) [0|255] "" XXX
 SG_ BYTE21 : 168|8@1+ (1,0) [0|255] "" XXX
 SG_ BYTE22 : 176|8@1+ (1,0) [0|255] "" XXX
 SG_ BYTE23 : 184|8@1+ (1,0) [0|255] "" XXX
 SG_ BYTE24 : 192|8@1+ (1,0) [0|255] "" XXX
 SG_ BYTE25 : 200|8@1+ (1,0) [0|255] "" XXX
 SG_ BYTE26 : 208|8@1+ (1,0) [0|255] "" XXX
 SG_ BYTE27 : 216|8@1+ (1,0) [0|255] "" XXX
 SG_ BYTE28 : 224|8@1+ (1,0) [0|255] "" XXX
 SG_ BYTE29 : 232|8@1+ (1,0) [0|255] "" XXX
 SG_ BYTE30 : 240|8@1+ (1,0) [0|255] "" XXX
 SG_ BYTE31 : 248|8@1+ (1,0) [0|255] "" XXX

BO_ 978 ID978: 32 XXX
 SG_ BYTE0 : 0|8@1+ (1,0) [0|255] "" XXX
 SG_ BYTE1 : 8|8@1+ (1,0) [0|255] "" XXX
 SG_ BYTE2 : 16|8@1+ (1,0) [0|255] "" XXX
 SG_ BYTE3 : 24|8@1+ (1,0) [0|255] "" XXX
 SG_ BYTE4 : 32|8@1+ (1,0) [0|255] "" XXX
 SG_ BYTE5 : 40|8@1+ (1,0) [0|255] "" XXX
 SG_ BYTE6 : 48|8@1+ (1,0) [0|255] "" XXX
 SG_ BYTE7 : 56|8@1+ (1,0) [0|255] "" XXX
 SG_ BYTE8 : 64|8@1+ (1,0) [0|255] "" XXX
 SG_ BYTE9 : 72|8@1+ (1,0) [0|255] "" XXX
 SG_ BYTE10 : 80|8@1+ (1,0) [0|255] "" XXX
 SG_ BYTE11 : 88|8@1+ (1,0) [0|255] "" XXX
 SG_ BYTE12 : 96|8@1+ (1,0) [0|255] "" XXX
 SG_ BYTE13 : 104|8@1+ (1,0) [0|255] "" XXX
 SG_ BYTE14 : 112|8@1+ (1,0) [0|255] "" XXX
 SG_ BYTE15 : 120|8@1+ (1,0) [0|255] "" XXX
 SG_ BYTE16 : 128|8@1+ (1,0) [0|255] "" XXX
 SG_ BYTE17 : 136|8@1+ (1,0) [0|255] "" XXX
 SG_ BYTE18 : 144|8@1+ (1,0) [0|255] "" XXX
 SG_ BYTE19 : 152|8@1+ (1,0) [0|255] "" XXX
 SG_ BYTE20 : 160|8@1+ (1,0) [0|255] "" XXX
 SG_ BYTE21 : 168|8@1+ (1,0) [0|255] "" XXX
 SG_ BYTE22 : 176|8@1+ (1,0) [0|255] "" XXX
 SG_ BYTE23 : 184|8@1+ (1,0) [0|255] "" XXX
 SG_ BYTE24 : 192|8@1+ (1,0) [0|255] "" XXX
 SG_ BYTE25 : 200|8@1+ (1,0) [0|255] "" XXX
 SG_ BYTE26 : 208|8@1+ (1,0) [0|255] "" XXX
 SG_ BYTE27 : 216|8@1+ (1,0) [0|255] "" XXX
 SG_ BYTE28 : 224|8@1+ (1,0) [0|255] "" XXX
 SG_ BYTE29 : 232|8@1+ (1,0) [0|255] "" XXX
 SG_ BYTE30 : 240|8@1+ (1,0) [0|255] "" XXX
 SG_ BYTE31 : 248|8@1+ (1,0) [0|255] "" XXX

BO_ 979 EV4_BODY_2: 32 XXX
 SG_ DOOR_OPEN_ANY : 0|1@1+ (1,0) [0|1] "" XXX
 SG_ BYTE1 : 8|8@1+ (1,0) [0|255] "" XXX
 SG_ BYTE2 : 16|8@1+ (1,0) [0|255] "" XXX
 SG_ BYTE3 : 24|8@1+ (1,0) [0|255] "" XXX
 SG_ BYTE4 : 32|8@1+ (1,0) [0|255] "" XXX
 SG_ BYTE5 : 40|8@1+ (1,0) [0|255] "" XXX
 SG_ BYTE6 : 48|8@1+ (1,0) [0|255] "" XXX
 SG_ BYTE7 : 56|8@1+ (1,0) [0|255] "" XXX
 SG_ BYTE8 : 64|8@1+ (1,0) [0|255] "" XXX
 SG_ BYTE9 : 72|8@1+ (1,0) [0|255] "" XXX
 SG_ BYTE10 : 80|8@1+ (1,0) [0|255] "" XXX
 SG_ BYTE11 : 88|8@1+ (1,0) [0|255] "" XXX
 SG_ BYTE12 : 96|8@1+ (1,0) [0|255] "" XXX
 SG_ BYTE13 : 104|8@1+ (1,0) [0|255] "" XXX
 SG_ BYTE14 : 112|8@1+ (1,0) [0|255] "" XXX
 SG_ BYTE15 : 120|8@1+ (1,0) [0|255] "" XXX
 SG_ BYTE16 : 128|8@1+ (1,0) [0|255] "" XXX
 SG_ BYTE17 : 136|8@1+ (1,0) [0|255] "" XXX
 SG_ BYTE18 : 144|8@1+ (1,0) [0|255] "" XXX
 SG_ BYTE19 : 152|8@1+ (1,0) [0|255] "" XXX
 SG_ BYTE20 : 160|8@1+ (1,0) [0|255] "" XXX
 SG_ BYTE21 : 168|8@1+ (1,0) [0|255] "" XXX
 SG_ BYTE22 : 176|8@1+ (1,0) [0|255] "" XXX
 SG_ BYTE23 : 184|8@1+ (1,0) [0|255] "" XXX
 SG_ BYTE24 : 192|8@1+ (1,0) [0|255] "" XXX
 SG_ BYTE25 : 200|8@1+ (1,0) [0|255] "" XXX
 SG_ BYTE26 : 208|8@1+ (1,0) [0|255] "" XXX
 SG_ BYTE27 : 216|8@1+ (1,0) [0|255] "" XXX
 SG_ BYTE28 : 224|8@1+ (1,0) [0|255] "" XXX
 SG_ BYTE29 : 232|8@1+ (1,0) [0|255] "" XXX
 SG_ BYTE30 : 240|8@1+ (1,0) [0|255] "" XXX
 SG_ BYTE31 : 248|8@1+ (1,0) [0|255] "" XXX

BO_ 980 ID980: 32 XXX
 SG_ BYTE0 : 0|8@1+ (1,0) [0|255] "" XXX
 SG_ BYTE1 : 8|8@1+ (1,0) [0|255] "" XXX
 SG_ BYTE2 : 16|8@1+ (1,0) [0|255] "" XXX
 SG_ BYTE3 : 24|8@1+ (1,0) [0|255] "" XXX
 SG_ BYTE4 : 32|8@1+ (1,0) [0|255] "" XXX
 SG_ BYTE5 : 40|8@1+ (1,0) [0|255] "" XXX
 SG_ BYTE6 : 48|8@1+ (1,0) [0|255] "" XXX
 SG_ BYTE7 : 56|8@1+ (1,0) [0|255] "" XXX
 SG_ BYTE8 : 64|8@1+ (1,0) [0|255] "" XXX
 SG_ BYTE9 : 72|8@1+ (1,0) [0|255] "" XXX
 SG_ BYTE10 : 80|8@1+ (1,0) [0|255] "" XXX
 SG_ BYTE11 : 88|8@1+ (1,0) [0|255] "" XXX
 SG_ BYTE12 : 96|8@1+ (1,0) [0|255] "" XXX
 SG_ BYTE13 : 104|8@1+ (1,0) [0|255] "" XXX
 SG_ BYTE14 : 112|8@1+ (1,0) [0|255] "" XXX
 SG_ BYTE15 : 120|8@1+ (1,0) [0|255] "" XXX
 SG_ BYTE16 : 128|8@1+ (1,0) [0|255] "" XXX
 SG_ BYTE17 : 136|8@1+ (1,0) [0|255] "" XXX
 SG_ BYTE18 : 144|8@1+ (1,0) [0|255] "" XXX
 SG_ BYTE19 : 152|8@1+ (1,0) [0|255] "" XXX
 SG_ BYTE20 : 160|8@1+ (1,0) [0|255] "" XXX
 SG_ BYTE21 : 168|8@1+ (1,0) [0|255] "" XXX
 SG_ BYTE22 : 176|8@1+ (1,0) [0|255] "" XXX
 SG_ BYTE23 : 184|8@1+ (1,0) [0|255] "" XXX
 SG_ BYTE24 : 192|8@1+ (1,0) [0|255] "" XXX
 SG_ BYTE25 : 200|8@1+ (1,0) [0|255] "" XXX
 SG_ BYTE26 : 208|8@1+ (1,0) [0|255] "" XXX
 SG_ BYTE27 : 216|8@1+ (1,0) [0|255] "" XXX
 SG_ BYTE28 : 224|8@1+ (1,0) [0|255] "" XXX
 SG_ BYTE29 : 232|8@1+ (1,0) [0|255] "" XXX
 SG_ BYTE30 : 240|8@1+ (1,0) [0|255] "" XXX
 SG_ BYTE31 : 248|8@1+ (1,0) [0|255] "" XXX

BO_ 1041 DOORS_SEATBELTS: 8 XXX
 SG_ BYTE0 : 0|8@1+ (1,0) [0|255] "" XXX
 SG_ BYTE1 : 8|8@1+ (1,0) [0|255] "" XXX
 SG_ BYTE2 : 16|8@1+ (1,0) [0|255] "" XXX
 SG_ BYTE3 : 24|8@1+ (1,0) [0|255] "" XXX
 SG_ BYTE4 : 32|8@1+ (1,0) [0|255] "" XXX
 SG_ BYTE5 : 40|8@1+ (1,0) [0|255] "" XXX
 SG_ BYTE6 : 48|8@1+ (1,0) [0|255] "" XXX
 SG_ BYTE7 : 56|8@1+ (1,0) [0|255] "" XXX

BO_ 1043 BLINKERS: 8 XXX

BO_ 1280 ID1280: 16 XXX
 SG_ BYTE0 : 0|8@1+ (1,0) [0|255] "" XXX
 SG_ BYTE1 : 8|8@1+ (1,0) [0|255] "" XXX
 SG_ BYTE2 : 16|8@1+ (1,0) [0|255] "" XXX
 SG_ BYTE3 : 24|8@1+ (1,0) [0|255] "" XXX
 SG_ BYTE4 : 32|8@1+ (1,0) [0|255] "" XXX
 SG_ BYTE5 : 40|8@1+ (1,0) [0|255] "" XXX
 SG_ BYTE6 : 48|8@1+ (1,0) [0|255] "" XXX
 SG_ BYTE7 : 56|8@1+ (1,0) [0|255] "" XXX
 SG_ BYTE8 : 64|8@1+ (1,0) [0|255] "" XXX
 SG_ BYTE9 : 72|8@1+ (1,0) [0|255] "" XXX
 SG_ BYTE10 : 80|8@1+ (1,0) [0|255] "" XXX
 SG_ BYTE11 : 88|8@1+ (1,0) [0|255] "" XXX
 SG_ BYTE12 : 96|8@1+ (1,0) [0|255] "" XXX
 SG_ BYTE13 : 104|8@1+ (1,0) [0|255] "" XXX
 SG_ BYTE14 : 112|8@1+ (1,0) [0|255] "" XXX
 SG_ BYTE15 : 120|8@1+ (1,0) [0|255] "" XXX

VAL_ 53 GEAR 0 "P" 7 "R" 6 "N" 5 "D" ;
VAL_ 304 GEAR 0 "P" 7 "R" 6 "N" 5 "D" ;
VAL_ 64 GEAR 0 "P" 7 "R" 6 "N" 5 "D" ;
